VERSION ""

NS_ :

BS_:

BU_: EVCC C_ECU C_ECU_GW

BO_ 803 EYE323: 8 C_ECU_GW
 SG_ EYE323_7_0_ISA_OFFSET_CURR : 56|5@1+ (1,-10) [-10|10] "" Vector__XXX
 SG_ EYE323_7_5_SLIF_FUNC_INFO : 61|1@1+ (1,0) [0|1] "" Vector__XXX
 SG_ EYE323_7_6_ISA_FUNC_INFO : 62|1@1+ (1,0) [0|1] "" Vector__XXX
 SG_ EYE323_7_7_ISA_CUSTOMIZE_CURR : 63|1@1+ (1,0) [0|1] "" Vector__XXX
 SG_ EYE323_6_0_LDW_OFFSW_INFO : 48|1@1+ (1,0) [0|1] "" Vector__XXX
 SG_ EYE323_6_1_LDW_ON_OFF_SET : 49|1@1+ (1,0) [0|1] "" Vector__XXX
 SG_ EYE323_6_2_CSTM_DDAW_WARN_SET : 50|1@1+ (1,0) [0|1] "" Vector__XXX
 SG_ EYE323_6_3_IACC_FUNC_INFO : 51|1@1+ (1,0) [0|1] "" Vector__XXX
 SG_ EYE323_6_5_CSTM_LDW_TIMING_SET : 53|1@1+ (1,0) [0|1] "" Vector__XXX
 SG_ EYE323_6_6_CSTM_LDW_TIMING : 54|1@1+ (1,0) [0|1] "" Vector__XXX
 SG_ EYE323_6_7_SLOWDOWNL_FUNC_INFO : 55|1@1+ (1,0) [0|1] "" Vector__XXX
 SG_ EYE323_5_0_CNG_GRN_CONT_CURR : 40|1@1+ (1,0) [0|1] "" Vector__XXX
 SG_ EYE323_5_1_TRAFFIC_FUNC_INFO : 41|1@1+ (1,0) [0|1] "" Vector__XXX
 SG_ EYE323_5_2_FCW_OFFSW_INFO : 42|1@1+ (1,0) [0|1] "" Vector__XXX
 SG_ EYE323_5_3_FCW_ON_OFF_SET : 43|1@1+ (1,0) [0|1] "" Vector__XXX
 SG_ EYE323_5_4_WARNING_SEL_CURR : 44|1@1+ (1,0) [0|1] "" Vector__XXX
 SG_ EYE323_5_5_HAPT_FUNC_INFO : 45|1@1+ (1,0) [0|1] "" Vector__XXX
 SG_ EYE323_5_6_TOLLGATE_CONT_CURR : 46|1@1+ (1,0) [0|1] "" Vector__XXX
 SG_ EYE323_5_7_CURVE_CONT_CURR : 47|1@1+ (1,0) [0|1] "" Vector__XXX
 SG_ EYE323_4_0_FCTB_ICON_L : 32|2@1+ (1,0) [0|3] "" Vector__XXX
 SG_ EYE323_4_2_FCTB_ICON_R : 34|2@1+ (1,0) [0|3] "" Vector__XXX
 SG_ EYE323_4_4_FCW_CONT_CURR : 36|2@1+ (1,0) [0|3] "" Vector__XXX
 SG_ EYE323_4_6_FCW_DISPLAY_SEL : 38|2@1+ (1,0) [0|3] "" Vector__XXX
 SG_ EYE323_3_0_AES_FUNC_INFO : 24|1@1+ (1,0) [0|1] "" Vector__XXX
 SG_ EYE323_3_1_CSTM_TSR_NO_ENTRY_SET : 25|1@1+ (1,0) [0|1] "" Vector__XXX
 SG_ EYE323_3_2_CSTM_TSR_STOP_SET : 26|1@1+ (1,0) [0|1] "" Vector__XXX
 SG_ EYE323_3_3_CSTM_TSR_GIVE_WAY_SET : 27|1@1+ (1,0) [0|1] "" Vector__XXX
 SG_ EYE323_3_4_WILDERNESS : 28|1@1+ (1,0) [0|1] "" Vector__XXX
 SG_ EYE323_3_5_AES_OFF : 29|1@1+ (1,0) [0|1] "" Vector__XXX
 SG_ EYE323_3_6_FCTB_IND : 30|2@1+ (1,0) [0|3] "" Vector__XXX
 SG_ EYE323_2_0_CSTM_LDW_ALK_B : 16|2@1+ (1,0) [0|3] "" Vector__XXX
 SG_ EYE323_2_2_CSTM_P_CR : 18|1@1+ (1,0) [0|1] "" Vector__XXX
 SG_ EYE323_2_3_SLOWDOWN_FUNC_INFO2 : 19|1@1+ (1,0) [0|1] "" Vector__XXX
 SG_ EYE323_2_4_CID_CODE_WARN : 20|4@1+ (1,0) [0|15] "" Vector__XXX
 SG_ EYE323_1_0_MSG_COUNTER : 8|4@1+ (1,0) [0|15] "" Vector__XXX
 SG_ EYE323_1_4_DISP_FOLLOW_FORWARD : 12|1@1+ (1,0) [0|1] "" Vector__XXX
 SG_ EYE323_1_5_KEEP_LINE_SENTER_ACT : 13|1@1+ (1,0) [0|1] "" Vector__XXX
 SG_ EYE323_1_6_DDAW_FAIL_OFF : 14|2@1+ (1,0) [0|3] "" Vector__XXX
 SG_ EYE323_0_0_CHECK_SUM : 0|8@1+ (1,0) [0|255] "" Vector__XXX

BO_ 2564481222 EVCC18DAE0C6: 8 EVCC
 SG_ EVCC18DAE0C6_DIAG_DATA : 7|64@0+ (1,0) [0|1.844674407371E+19] ""  C_ECU_GW

BO_ 2564474592 DNT18DAC6E0: 8 C_ECU_GW
 SG_ DNT18DAC6E0_DIAG_DATA : 7|64@0+ (1,0) [0|1.844674407371E+19] ""  EVCC

BO_ 2564481219 EVCC18DAE0C3: 8 EVCC
 SG_ EVCC18DAE0C3_DIAG_DATA : 7|64@0+ (1,0) [0|1.844674407371E+19] ""  C_ECU_GW

BO_ 2564473824 DNT18DAC3E0: 8 C_ECU_GW
 SG_ DNT18DAC3E0_DIAG_DATA : 7|64@0+ (1,0) [0|1.844674407371E+19] ""  EVCC

BO_ 2564481478 EVCC18DAE1C6: 64 EVCC
 SG_ EVCC18DAE1C6_DIAG_DATA_EXT7 : 455|64@0+ (1,0) [0|1.844674407371E+19] ""  C_ECU
 SG_ EVCC18DAE1C6_DIAG_DATA_EXT6 : 391|64@0+ (1,0) [0|1.844674407371E+19] ""  C_ECU
 SG_ EVCC18DAE1C6_DIAG_DATA_EXT5 : 327|64@0+ (1,0) [0|1.844674407371E+19] ""  C_ECU
 SG_ EVCC18DAE1C6_DIAG_DATA_EXT4 : 263|64@0+ (1,0) [0|1.844674407371E+19] ""  C_ECU
 SG_ EVCC18DAE1C6_DIAG_DATA_EXT3 : 199|64@0+ (1,0) [0|1.844674407371E+19] ""  C_ECU
 SG_ EVCC18DAE1C6_DIAG_DATA_EXT2 : 135|64@0+ (1,0) [0|1.844674407371E+19] ""  C_ECU
 SG_ EVCC18DAE1C6_DIAG_DATA_EXT1 : 71|64@0+ (1,0) [0|1.844674407371E+19] ""  C_ECU
 SG_ EVCC18DAE1C6_DIAG_DATA : 7|64@0+ (1,0) [0|1.844674407371E+19] ""  C_ECU

BO_ 2564474593 CECU18DAC6E1: 64 C_ECU
 SG_ CECU18DAC6E1_DIAG_DATA_EXT7 : 455|64@0+ (1,0) [0|1.844674407371E+19] ""  EVCC
 SG_ CECU18DAC6E1_DIAG_DATA_EXT6 : 391|64@0+ (1,0) [0|1.844674407371E+19] ""  EVCC
 SG_ CECU18DAC6E1_DIAG_DATA_EXT5 : 327|64@0+ (1,0) [0|1.844674407371E+19] ""  EVCC
 SG_ CECU18DAC6E1_DIAG_DATA_EXT4 : 263|64@0+ (1,0) [0|1.844674407371E+19] ""  EVCC
 SG_ CECU18DAC6E1_DIAG_DATA_EXT3 : 199|64@0+ (1,0) [0|1.844674407371E+19] ""  EVCC
 SG_ CECU18DAC6E1_DIAG_DATA_EXT2 : 135|64@0+ (1,0) [0|1.844674407371E+19] ""  EVCC
 SG_ CECU18DAC6E1_DIAG_DATA_EXT1 : 71|64@0+ (1,0) [0|1.844674407371E+19] ""  EVCC
 SG_ CECU18DAC6E1_DIAG_DATA : 7|64@0+ (1,0) [0|1.844674407371E+19] ""  EVCC

BO_ 2564481475 EVCC18DAE1C3: 64 EVCC
 SG_ EVCC18DAE1C3_DIAG_DATA_EXT7 : 455|64@0+ (1,0) [0|1.844674407371E+19] ""  C_ECU
 SG_ EVCC18DAE1C3_DIAG_DATA_EXT6 : 391|64@0+ (1,0) [0|1.844674407371E+19] ""  C_ECU
 SG_ EVCC18DAE1C3_DIAG_DATA_EXT5 : 327|64@0+ (1,0) [0|1.844674407371E+19] ""  C_ECU
 SG_ EVCC18DAE1C3_DIAG_DATA_EXT4 : 263|64@0+ (1,0) [0|1.844674407371E+19] ""  C_ECU
 SG_ EVCC18DAE1C3_DIAG_DATA_EXT3 : 199|64@0+ (1,0) [0|1.844674407371E+19] ""  C_ECU
 SG_ EVCC18DAE1C3_DIAG_DATA_EXT2 : 135|64@0+ (1,0) [0|1.844674407371E+19] ""  C_ECU
 SG_ EVCC18DAE1C3_DIAG_DATA_EXT1 : 71|64@0+ (1,0) [0|1.844674407371E+19] ""  C_ECU
 SG_ EVCC18DAE1C3_DIAG_DATA : 7|64@0+ (1,0) [0|1.844674407371E+19] ""  C_ECU

BO_ 2564473825 CECU18DAC3E1: 64 C_ECU
 SG_ CECU18DAC3E1_DIAG_DATA_EXT7 : 455|64@0+ (1,0) [0|1.844674407371E+19] ""  EVCC
 SG_ CECU18DAC3E1_DIAG_DATA_EXT6 : 391|64@0+ (1,0) [0|1.844674407371E+19] ""  EVCC
 SG_ CECU18DAC3E1_DIAG_DATA_EXT5 : 327|64@0+ (1,0) [0|1.844674407371E+19] ""  EVCC
 SG_ CECU18DAC3E1_DIAG_DATA_EXT4 : 263|64@0+ (1,0) [0|1.844674407371E+19] ""  EVCC
 SG_ CECU18DAC3E1_DIAG_DATA_EXT3 : 199|64@0+ (1,0) [0|1.844674407371E+19] ""  EVCC
 SG_ CECU18DAC3E1_DIAG_DATA_EXT2 : 135|64@0+ (1,0) [0|1.844674407371E+19] ""  EVCC
 SG_ CECU18DAC3E1_DIAG_DATA_EXT1 : 71|64@0+ (1,0) [0|1.844674407371E+19] ""  EVCC
 SG_ CECU18DAC3E1_DIAG_DATA : 7|64@0+ (1,0) [0|1.844674407371E+19] ""  EVCC

BO_ 1100 EVCC44C: 8 EVCC
 SG_ EVCC44C_2_0_E2E_COUNTER : 16|8@1+ (1,0) [0|255] ""  C_ECU_GW
 SG_ EVCC44C_0_0_E2E_CRC : 0|16@1+ (1,0) [0|65535] ""  C_ECU_GW

BO_ 1099 EVCC44B: 32 EVCC
 SG_ EVCC44B_27_0_EVSE_ID_7_EVCC : 216|32@1+ (1,0) [0|31] ""  C_ECU_GW
 SG_ EVCC44B_23_0_EVSE_ID_6_EVCC : 184|32@1+ (1,0) [0|31] ""  C_ECU_GW
 SG_ EVCC44B_19_0_EVSE_ID_5_EVCC : 152|32@1+ (1,0) [0|31] ""  C_ECU_GW
 SG_ EVCC44B_15_0_EVSE_ID_4_EVCC : 120|32@1+ (1,0) [0|31] ""  C_ECU_GW
 SG_ EVCC44B_11_0_EVSE_ID_3_EVCC : 88|32@1+ (1,0) [0|31] ""  C_ECU_GW
 SG_ EVCC44B_7_0_EVSE_ID_2_EVCC : 56|32@1+ (1,0) [0|31] ""  C_ECU_GW
 SG_ EVCC44B_3_0_EVSE_ID_1_EVCC : 24|32@1+ (1,0) [0|31] ""  C_ECU_GW
 SG_ EVCC44B_2_0_E2E_COUNTER : 16|8@1+ (1,0) [0|255] ""  C_ECU_GW
 SG_ EVCC44B_0_0_E2E_CRC : 0|16@1+ (1,0) [0|65535] ""  C_ECU_GW

BO_ 1098 EVCC44A: 32 EVCC
 SG_ EVCC44A_3_0_PNC_CC_SAVE_RES_RSLT : 24|8@1+ (1,0) [0|5] ""  C_ECU,C_ECU_GW
 SG_ EVCC44A_2_0_E2E_COUNTER : 16|8@1+ (1,0) [0|255] ""  C_ECU,C_ECU_GW
 SG_ EVCC44A_0_0_E2E_CRC : 0|16@1+ (1,0) [0|65535] ""  C_ECU,C_ECU_GW

BO_ 1097 EVCC449: 8 EVCC
 SG_ EVCC449_2_0_E2E_COUNTER : 16|8@1+ (1,0) [0|255] ""  C_ECU_GW
 SG_ EVCC449_0_0_E2E_CRC : 0|16@1+ (1,0) [0|65535] ""  C_ECU_GW

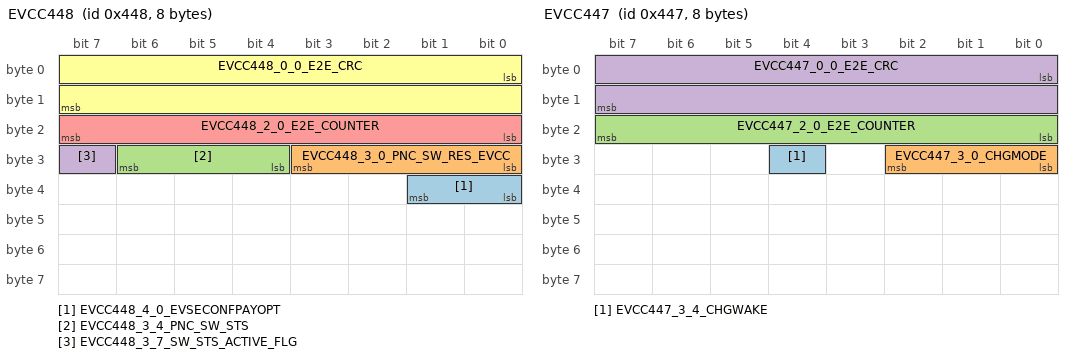
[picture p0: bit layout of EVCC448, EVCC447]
BO_ 1096 EVCC448: 8 EVCC
 SG_ EVCC448_4_0_EVSECONFPAYOPT : 32|2@1+ (1,0) [0|2] ""  C_ECU_GW
 SG_ EVCC448_3_0_PNC_SW_RES_EVCC : 24|4@1+ (1,0) [0|8] ""  C_ECU_GW
 SG_ EVCC448_3_4_PNC_SW_STS : 28|3@1+ (1,0) [0|7] ""  C_ECU_GW
 SG_ EVCC448_3_7_SW_STS_ACTIVE_FLG : 31|1@1+ (1,0) [0|1] ""  C_ECU_GW
 SG_ EVCC448_2_0_E2E_COUNTER : 16|8@1+ (1,0) [0|255] ""  C_ECU_GW
 SG_ EVCC448_0_0_E2E_CRC : 0|16@1+ (1,0) [0|65535] ""  C_ECU_GW

BO_ 1095 EVCC447: 8 EVCC
 SG_ EVCC447_3_4_CHGWAKE : 28|1@1+ (1,0) [0|1] ""  C_ECU,C_ECU_GW
 SG_ EVCC447_3_0_CHGMODE : 24|3@1+ (1,0) [0|7] ""  C_ECU,C_ECU_GW
 SG_ EVCC447_2_0_E2E_COUNTER : 16|8@1+ (1,0) [0|255] ""  C_ECU,C_ECU_GW
 SG_ EVCC447_0_0_E2E_CRC : 0|16@1+ (1,0) [0|65535] ""  C_ECU,C_ECU_GW

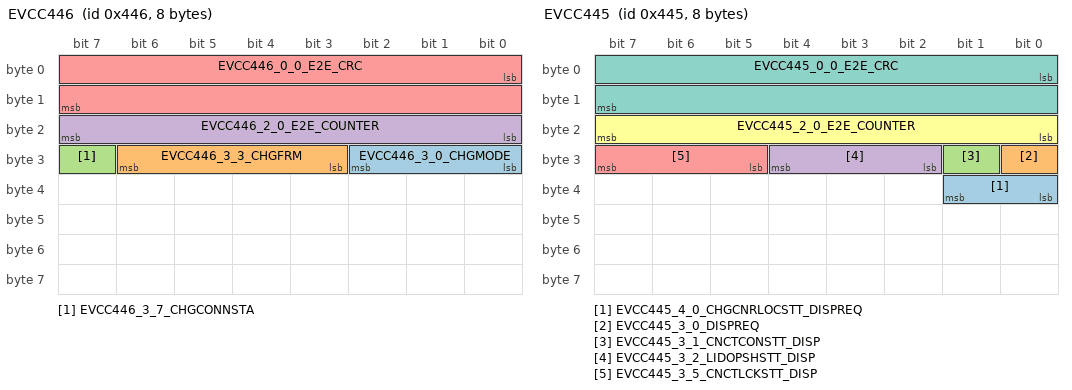
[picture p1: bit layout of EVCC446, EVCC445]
BO_ 1094 EVCC446: 8 EVCC
 SG_ EVCC446_3_0_CHGMODE : 24|3@1+ (1,0) [0|7] ""  C_ECU_GW
 SG_ EVCC446_3_3_CHGFRM : 27|4@1+ (1,0) [0|15] ""  C_ECU_GW
 SG_ EVCC446_3_7_CHGCONNSTA : 31|1@1+ (1,0) [0|1] ""  C_ECU_GW
 SG_ EVCC446_2_0_E2E_COUNTER : 16|8@1+ (1,0) [0|255] ""  C_ECU_GW
 SG_ EVCC446_0_0_E2E_CRC : 0|16@1+ (1,0) [0|65535] ""  C_ECU_GW

BO_ 1093 EVCC445: 8 EVCC
 SG_ EVCC445_4_0_CHGCNRLOCSTT_DISPREQ : 32|2@1+ (1,0) [0|2] ""  C_ECU_GW
 SG_ EVCC445_3_0_DISPREQ : 24|1@1+ (1,0) [0|1] ""  C_ECU_GW
 SG_ EVCC445_3_1_CNCTCONSTT_DISP : 25|1@1+ (1,0) [0|1] ""  C_ECU_GW
 SG_ EVCC445_3_2_LIDOPSHSTT_DISP : 26|3@1+ (1,0) [0|2] ""  C_ECU_GW
 SG_ EVCC445_3_5_CNCTLCKSTT_DISP : 29|3@1+ (1,0) [0|2] ""  C_ECU_GW
 SG_ EVCC445_2_0_E2E_COUNTER : 16|8@1+ (1,0) [0|255] ""  C_ECU_GW
 SG_ EVCC445_0_0_E2E_CRC : 0|16@1+ (1,0) [0|65535] ""  C_ECU_GW

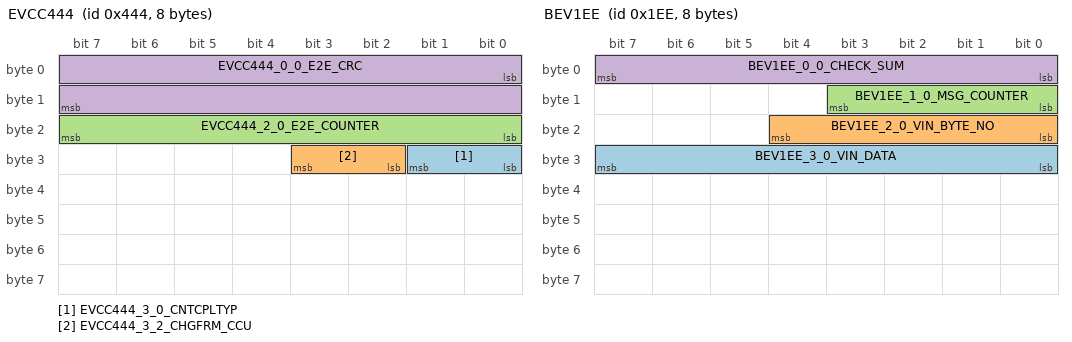
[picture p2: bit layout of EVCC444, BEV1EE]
BO_ 1092 EVCC444: 8 EVCC
 SG_ EVCC444_3_0_CNTCPLTYP : 24|2@1+ (1,0) [0|1] ""  C_ECU_GW
 SG_ EVCC444_3_2_CHGFRM_CCU : 26|2@1+ (1,0) [0|2] ""  C_ECU_GW
 SG_ EVCC444_2_0_E2E_COUNTER : 16|8@1+ (1,0) [0|255] ""  C_ECU_GW
 SG_ EVCC444_0_0_E2E_CRC : 0|16@1+ (1,0) [0|65535] ""  C_ECU_GW

BO_ 1305 EVCC519: 8 EVCC
 SG_ EVCC519_1_4_ACTIVEWAKEUPBIT : 12|1@1+ (1,0) [0|1] ""  C_ECU
 SG_ EVCC519_0_0_SOURCENODEID : 0|8@1+ (1,0) [0|255] ""  C_ECU

BO_ 494 BEV1EE: 8 C_ECU_GW
 SG_ BEV1EE_3_0_VIN_DATA : 24|8@1+ (1,0) [0|255] "" Vector__XXX
 SG_ BEV1EE_2_0_VIN_BYTE_NO : 16|5@1+ (1,0) [0|17] "" Vector__XXX
 SG_ BEV1EE_1_0_MSG_COUNTER : 8|4@1+ (1,0) [0|15] "" Vector__XXX
 SG_ BEV1EE_0_0_CHECK_SUM : 0|8@1+ (1,0) [0|255] "" Vector__XXX

BO_ 2564550625 CECU18DBEFE1: 8 C_ECU
 SG_ CECU18DBEFE1_DIAG_DATA : 7|64@0+ (1,0) [0|1.844674407371E+19] ""  EVCC

BO_ 2564550624 DNT18DBEFE0: 8 C_ECU_GW
 SG_ DNT18DBEFE0_DIAG_DATA : 7|64@0+ (1,0) [0|1.844674407371E+19] "" Vector__XXX

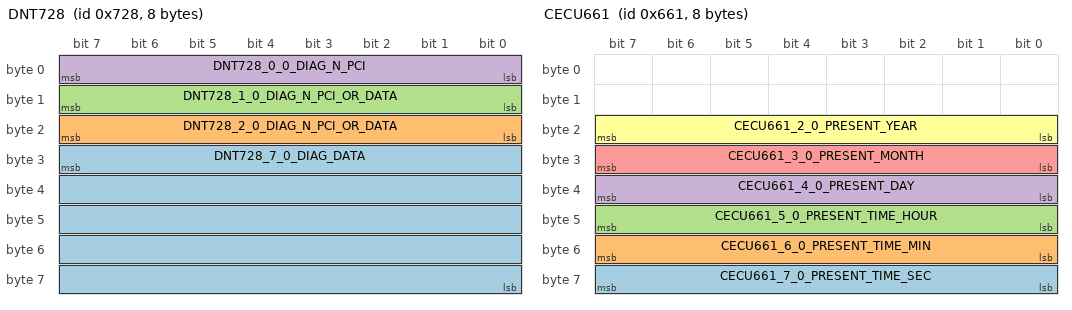
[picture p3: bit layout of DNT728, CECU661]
BO_ 1832 DNT728: 8 C_ECU_GW
 SG_ DNT728_7_0_DIAG_DATA : 31|40@0+ (1,0) [0|1099511627775] "" Vector__XXX
 SG_ DNT728_2_0_DIAG_N_PCI_OR_DATA : 23|8@0+ (1,0) [0|255] "" Vector__XXX
 SG_ DNT728_1_0_DIAG_N_PCI_OR_DATA : 15|8@0+ (1,0) [0|255] "" Vector__XXX
 SG_ DNT728_0_0_DIAG_N_PCI : 7|8@0+ (1,0) [0|255] "" Vector__XXX

BO_ 1280 CGW500: 8 C_ECU
 SG_ CGW500_1_4_ActiveWakeUpBit : 12|1@1+ (1,0) [0|1] ""  EVCC
 SG_ CGW500_0_0_SourceNodeID : 0|8@1+ (1,0) [0|255] ""  EVCC

BO_ 1633 CECU661: 8 C_ECU
 SG_ CECU661_7_0_PRESENT_TIME_SEC : 63|8@0+ (1,0) [0|89] "s"  EVCC
 SG_ CECU661_6_0_PRESENT_TIME_MIN : 55|8@0+ (1,0) [0|89] "m"  EVCC
 SG_ CECU661_5_0_PRESENT_TIME_HOUR : 47|8@0+ (1,0) [0|35] "h"  EVCC
 SG_ CECU661_4_0_PRESENT_DAY : 39|8@0+ (1,0) [1|49] "Day"  EVCC
 SG_ CECU661_3_0_PRESENT_MONTH : 31|8@0+ (1,0) [1|18] "Month"  EVCC
 SG_ CECU661_2_0_PRESENT_YEAR : 23|8@0+ (1,0) [0|153] "Year"  EVCC

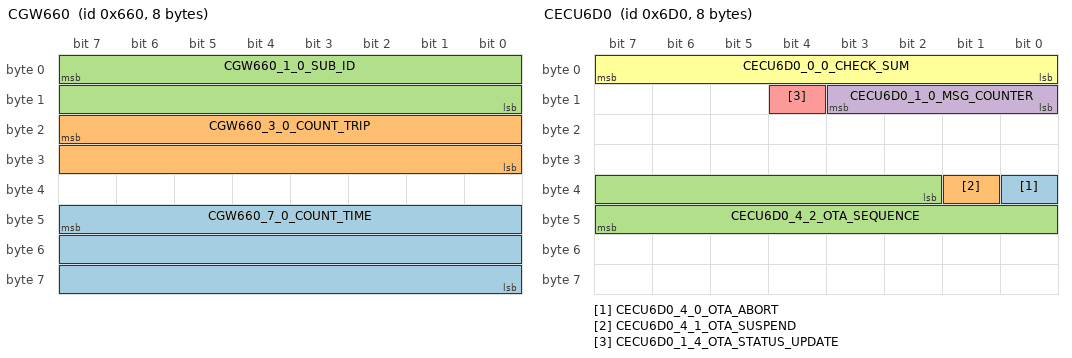
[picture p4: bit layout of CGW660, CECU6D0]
BO_ 1632 CGW660: 8 C_ECU
 SG_ CGW660_7_0_COUNT_TIME : 47|24@0+ (100,0) [0|1677721400] "ms" Vector__XXX
 SG_ CGW660_3_0_COUNT_TRIP : 23|16@0+ (1,0) [0|65534] "trip" Vector__XXX
 SG_ CGW660_1_0_SUB_ID : 7|16@0+ (1,0) [0|65535] "" Vector__XXX

BO_ 1744 CECU6D0: 8 C_ECU
 SG_ CECU6D0_4_0_OTA_ABORT : 32|1@1+ (1,0) [0|1] "" Vector__XXX
 SG_ CECU6D0_4_1_OTA_SUSPEND : 33|1@1+ (1,0) [0|1] "" Vector__XXX
 SG_ CECU6D0_4_2_OTA_SEQUENCE : 34|14@1+ (1,0) [0|33170] "" Vector__XXX
 SG_ CECU6D0_1_0_MSG_COUNTER : 8|4@1+ (1,0) [0|15] "" Vector__XXX
 SG_ CECU6D0_1_4_OTA_STATUS_UPDATE : 12|1@1+ (1,0) [0|0] "" Vector__XXX
 SG_ CECU6D0_0_0_CHECK_SUM : 0|8@1+ (1,0) [0|255] "" Vector__XXX

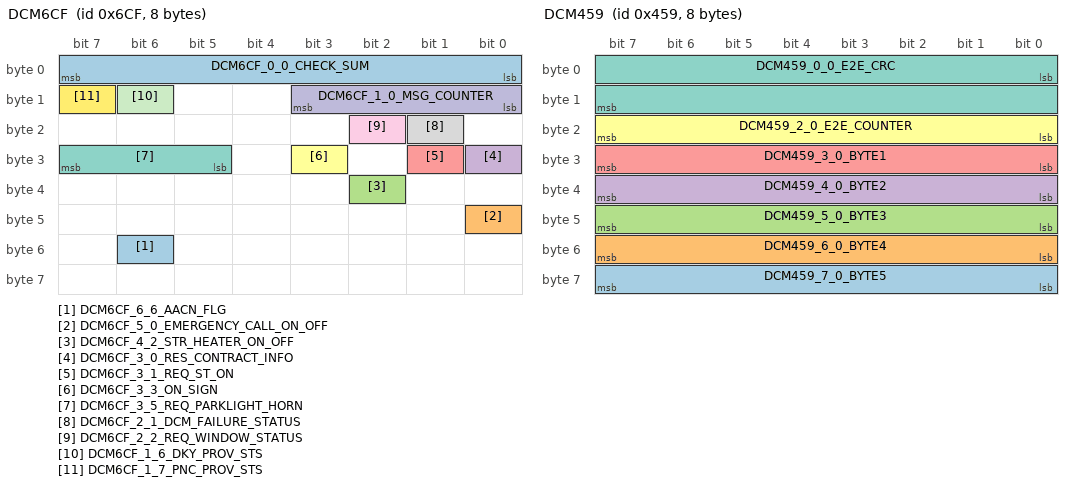
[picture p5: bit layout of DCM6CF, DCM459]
BO_ 1743 DCM6CF: 8 C_ECU_GW
 SG_ DCM6CF_6_6_AACN_FLG : 54|1@1+ (1,0) [0|1] "" Vector__XXX
 SG_ DCM6CF_5_0_EMERGENCY_CALL_ON_OFF : 40|1@1+ (1,0) [0|1] "" Vector__XXX
 SG_ DCM6CF_4_2_STR_HEATER_ON_OFF : 34|1@1+ (1,0) [0|1] "" Vector__XXX
 SG_ DCM6CF_3_0_RES_CONTRACT_INFO : 24|1@1+ (1,0) [0|1] "" Vector__XXX
 SG_ DCM6CF_3_1_REQ_ST_ON : 25|1@1+ (1,0) [0|1] "" Vector__XXX
 SG_ DCM6CF_3_3_ON_SIGN : 27|1@1+ (1,0) [0|1] "" Vector__XXX
 SG_ DCM6CF_3_5_REQ_PARKLIGHT_HORN : 29|3@1+ (1,0) [0|7] "" Vector__XXX
 SG_ DCM6CF_2_1_DCM_FAILURE_STATUS : 17|1@1+ (1,0) [0|1] "" Vector__XXX
 SG_ DCM6CF_2_2_REQ_WINDOW_STATUS : 18|1@1+ (1,0) [0|1] "" Vector__XXX
 SG_ DCM6CF_1_0_MSG_COUNTER : 8|4@1+ (1,0) [0|15] "" Vector__XXX
 SG_ DCM6CF_1_6_DKY_PROV_STS : 14|1@1+ (1,0) [0|1] "" Vector__XXX
 SG_ DCM6CF_1_7_PNC_PROV_STS : 15|1@1+ (1,0) [0|1] ""  EVCC
 SG_ DCM6CF_0_0_CHECK_SUM : 0|8@1+ (1,0) [0|255] "" Vector__XXX

BO_ 1113 DCM459: 8 C_ECU_GW
 SG_ DCM459_7_0_BYTE5 : 56|8@1+ (1,0) [0|255] ""  EVCC
 SG_ DCM459_6_0_BYTE4 : 48|8@1+ (1,0) [0|255] ""  EVCC
 SG_ DCM459_5_0_BYTE3 : 40|8@1+ (1,0) [0|255] ""  EVCC
 SG_ DCM459_4_0_BYTE2 : 32|8@1+ (1,0) [0|255] ""  EVCC
 SG_ DCM459_3_0_BYTE1 : 24|8@1+ (1,0) [0|255] ""  EVCC
 SG_ DCM459_2_0_E2E_COUNTER : 16|8@1+ (1,0) [0|255] ""  EVCC
 SG_ DCM459_0_0_E2E_CRC : 0|16@1+ (1,0) [0|65535] ""  EVCC

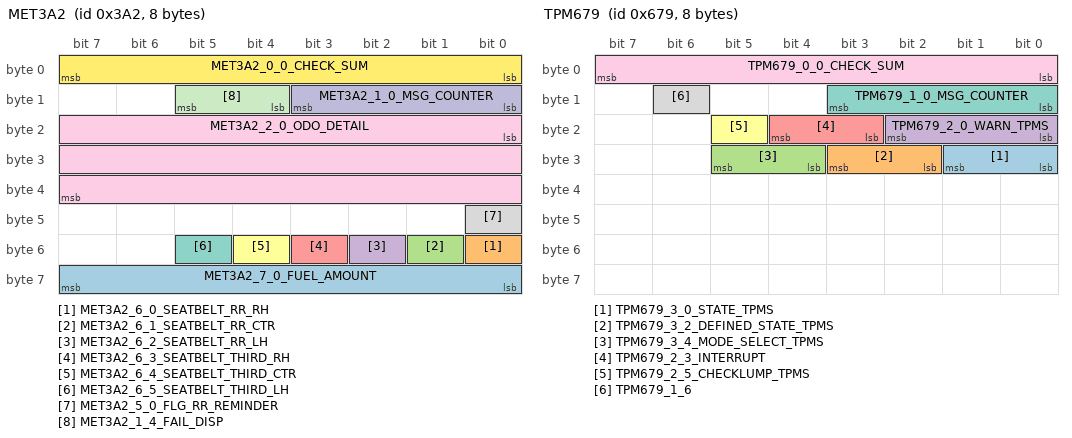
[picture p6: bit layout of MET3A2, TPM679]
BO_ 930 MET3A2: 8 C_ECU_GW
 SG_ MET3A2_7_0_FUEL_AMOUNT : 56|8@1+ (1,0) [0|100] "%" Vector__XXX
 SG_ MET3A2_6_0_SEATBELT_RR_RH : 48|1@1+ (1,0) [0|1] "" Vector__XXX
 SG_ MET3A2_6_1_SEATBELT_RR_CTR : 49|1@1+ (1,0) [0|1] "" Vector__XXX
 SG_ MET3A2_6_2_SEATBELT_RR_LH : 50|1@1+ (1,0) [0|1] "" Vector__XXX
 SG_ MET3A2_6_3_SEATBELT_THIRD_RH : 51|1@1+ (1,0) [0|1] "" Vector__XXX
 SG_ MET3A2_6_4_SEATBELT_THIRD_CTR : 52|1@1+ (1,0) [0|1] "" Vector__XXX
 SG_ MET3A2_6_5_SEATBELT_THIRD_LH : 53|1@1+ (1,0) [0|1] "" Vector__XXX
 SG_ MET3A2_5_0_FLG_RR_REMINDER : 40|1@1+ (1,0) [0|1] "" Vector__XXX
 SG_ MET3A2_2_0_ODO_DETAIL : 16|24@1+ (0.1,0) [0|1609103.5] "km" Vector__XXX
 SG_ MET3A2_1_0_MSG_COUNTER : 8|4@1+ (1,0) [0|15] "" Vector__XXX
 SG_ MET3A2_1_4_FAIL_DISP : 12|2@1+ (1,0) [0|3] "" Vector__XXX
 SG_ MET3A2_0_0_CHECK_SUM : 0|8@1+ (1,0) [0|255] "" Vector__XXX

BO_ 912 MET390: 8 C_ECU_GW
 SG_ MET390_7_0_VDC_ON_OFF : 56|2@1+ (1,0) [0|3] "" Vector__XXX
 SG_ MET390_7_2_RR_DOOR_RECORD_L : 58|1@1+ (1,0) [0|1] "" Vector__XXX
 SG_ MET390_7_3_RR_DOOR_RECORD_R : 59|1@1+ (1,0) [0|1] "" Vector__XXX
 SG_ MET390_7_4_REQ_CHG_CSTM_PSM : 60|1@1+ (1,0) [0|1] "" Vector__XXX
 SG_ MET390_7_5_REQ_RESET_CSTM_PSM : 61|1@1+ (1,0) [0|1] "" Vector__XXX
 SG_ MET390_7_6_CSTM_MIR_AFOLD_CONT : 62|1@1+ (1,0) [0|1] "" Vector__XXX
 SG_ MET390_7_7_CSTM_MIR_RTILT_CONT : 63|1@1+ (1,0) [0|1] "" Vector__XXX
 SG_ MET390_6_0_SEATBELT_DRVR : 48|1@1+ (1,0) [0|1] "" Vector__XXX
 SG_ MET390_6_1_SEATBELT_PASS : 49|1@1+ (1,0) [0|1] "" Vector__XXX
 SG_ MET390_6_2_TURN_SIG_LEFT : 50|1@1+ (1,0) [0|1] "" Vector__XXX
 SG_ MET390_6_3_TURN_SIG_RIGHT : 51|1@1+ (1,0) [0|1] "" Vector__XXX
 SG_ MET390_6_4_BRIGHT_SW : 52|1@1+ (1,0) [0|1] "" Vector__XXX
 SG_ MET390_6_5_FAIL_UART_WA_BOX : 53|1@1+ (1,0) [0|1] "" Vector__XXX
 SG_ MET390_6_6_ISS_OFF_SW : 54|1@1+ (1,0) [0|1] "" Vector__XXX
 SG_ MET390_6_7_FLG_DMS : 55|1@1+ (1,0) [0|1] "" Vector__XXX
 SG_ MET390_5_0_ILL_BRIGHTNESS : 40|8@1+ (0.4,0) [0|100] "%" Vector__XXX
 SG_ MET390_4_0_OUTTEMP_FOR_IND : 32|8@1+ (0.5,-40) [-40|80] "℃" Vector__XXX
 SG_ MET390_3_0_UNIT_SPEED_TRIP : 24|1@1+ (1,0) [0|1] "" Vector__XXX
 SG_ MET390_3_1_FLG_EYESIGHT : 25|1@1+ (1,0) [0|1] "" Vector__XXX
 SG_ MET390_3_2_FLG_ISS : 26|1@1+ (1,0) [0|1] "" Vector__XXX
 SG_ MET390_3_3_FLG_HEV : 27|1@1+ (1,0) [0|1] "" Vector__XXX
 SG_ MET390_3_4_FLG_IMB : 28|1@1+ (1,0) [0|1] "" Vector__XXX
 SG_ MET390_3_5_TIRE_SIZE : 29|1@1+ (1,0) [0|1] "" Vector__XXX
 SG_ MET390_3_6_FLG_XMODE : 30|2@1+ (1,0) [0|3] "" Vector__XXX
 SG_ MET390_2_0_VEHICLE_SERIES : 16|3@1+ (1,0) [0|7] "" Vector__XXX
 SG_ MET390_2_3_DESTINATION : 19|4@1+ (1,0) [0|12] "" Vector__XXX
 SG_ MET390_2_7_PASS_DOOR_RECORD : 23|1@1+ (1,0) [0|1] "" Vector__XXX
 SG_ MET390_1_0_MSG_COUNTER : 8|4@1+ (1,0) [0|15] "" Vector__XXX
 SG_ MET390_1_4_WAKE_UP_FRAME : 12|1@1+ (1,0) [0|1] "" Vector__XXX
 SG_ MET390_1_5_REQ_COMM_CONT : 13|1@1+ (1,0) [0|1] "" Vector__XXX
 SG_ MET390_1_6_DMS_ID_SET : 14|1@1+ (1,0) [0|1] "" Vector__XXX
 SG_ MET390_1_7_FAIL_EEPROM : 15|1@1+ (1,0) [0|1] "" Vector__XXX
 SG_ MET390_0_0_CHECK_SUM : 0|8@1+ (1,0) [0|255] "" Vector__XXX

BO_ 1657 TPM679: 8 C_ECU_GW
 SG_ TPM679_3_0_STATE_TPMS : 24|2@1+ (1,0) [0|3] "" Vector__XXX
 SG_ TPM679_3_2_DEFINED_STATE_TPMS : 26|2@1+ (1,0) [0|3] "" Vector__XXX
 SG_ TPM679_3_4_MODE_SELECT_TPMS : 28|2@1+ (1,0) [0|3] "" Vector__XXX
 SG_ TPM679_2_0_WARN_TPMS : 16|3@1+ (1,0) [0|7] "" Vector__XXX
 SG_ TPM679_2_3_INTERRUPT : 19|2@1+ (1,0) [0|2] "" Vector__XXX
 SG_ TPM679_2_5_CHECKLUMP_TPMS : 21|1@1+ (1,0) [0|1] "" Vector__XXX
 SG_ TPM679_1_0_MSG_COUNTER : 8|4@1+ (1,0) [0|15] "" Vector__XXX
 SG_ TPM679_1_6 : 14|1@1+ (1,0) [0|1] "" Vector__XXX
 SG_ TPM679_0_0_CHECK_SUM : 0|8@1+ (1,0) [0|255] "" Vector__XXX

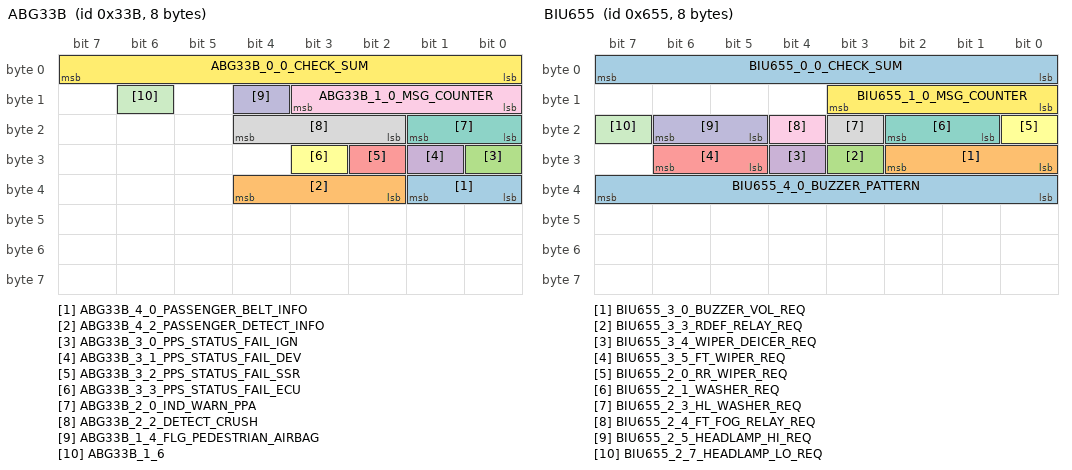
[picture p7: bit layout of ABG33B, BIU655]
BO_ 827 ABG33B: 8 C_ECU_GW
 SG_ ABG33B_4_0_PASSENGER_BELT_INFO : 32|2@1+ (1,0) [0|3] "" Vector__XXX
 SG_ ABG33B_4_2_PASSENGER_DETECT_INFO : 34|3@1+ (1,0) [0|7] "" Vector__XXX
 SG_ ABG33B_3_0_PPS_STATUS_FAIL_IGN : 24|1@1+ (1,0) [0|1] "" Vector__XXX
 SG_ ABG33B_3_1_PPS_STATUS_FAIL_DEV : 25|1@1+ (1,0) [0|1] "" Vector__XXX
 SG_ ABG33B_3_2_PPS_STATUS_FAIL_SSR : 26|1@1+ (1,0) [0|1] "" Vector__XXX
 SG_ ABG33B_3_3_PPS_STATUS_FAIL_ECU : 27|1@1+ (1,0) [0|1] "" Vector__XXX
 SG_ ABG33B_2_0_IND_WARN_PPA : 16|2@1+ (1,0) [0|3] "" Vector__XXX
 SG_ ABG33B_2_2_DETECT_CRUSH : 18|3@1+ (1,0) [0|7] "" Vector__XXX
 SG_ ABG33B_1_0_MSG_COUNTER : 8|4@1+ (1,0) [0|15] "" Vector__XXX
 SG_ ABG33B_1_4_FLG_PEDESTRIAN_AIRBAG : 12|1@1+ (1,0) [0|1] "" Vector__XXX
 SG_ ABG33B_1_6 : 14|1@1+ (1,0) [0|1] "" Vector__XXX
 SG_ ABG33B_0_0_CHECK_SUM : 0|8@1+ (1,0) [0|255] "" Vector__XXX

BO_ 1621 BIU655: 8 C_ECU_GW
 SG_ BIU655_4_0_BUZZER_PATTERN : 32|8@1+ (1,0) [0|240] "" Vector__XXX
 SG_ BIU655_3_0_BUZZER_VOL_REQ : 24|3@1+ (1,0) [0|7] "" Vector__XXX
 SG_ BIU655_3_3_RDEF_RELAY_REQ : 27|1@1+ (1,0) [0|1] "" Vector__XXX
 SG_ BIU655_3_4_WIPER_DEICER_REQ : 28|1@1+ (1,0) [0|1] "" Vector__XXX
 SG_ BIU655_3_5_FT_WIPER_REQ : 29|2@1+ (1,0) [0|3] "" Vector__XXX
 SG_ BIU655_2_0_RR_WIPER_REQ : 16|1@1+ (1,0) [0|1] "" Vector__XXX
 SG_ BIU655_2_1_WASHER_REQ : 17|2@1+ (1,0) [0|3] "" Vector__XXX
 SG_ BIU655_2_3_HL_WASHER_REQ : 19|1@1+ (1,0) [0|1] "" Vector__XXX
 SG_ BIU655_2_4_FT_FOG_RELAY_REQ : 20|1@1+ (1,0) [0|1] "" Vector__XXX
 SG_ BIU655_2_5_HEADLAMP_HI_REQ : 21|2@1+ (1,0) [0|3] "" Vector__XXX
 SG_ BIU655_2_7_HEADLAMP_LO_REQ : 23|1@1+ (1,0) [0|1] "" Vector__XXX
 SG_ BIU655_1_0_MSG_COUNTER : 8|4@1+ (1,0) [0|15] "" Vector__XXX
 SG_ BIU655_0_0_CHECK_SUM : 0|8@1+ (1,0) [0|255] "" Vector__XXX

BO_ 1618 BIU652: 8 C_ECU_GW
 SG_ BIU652_7_0_IND_SECURITY_IMB : 56|8@1+ (1,0) [0|240] "" Vector__XXX
 SG_ BIU652_6_0_OCCUPATION_3RDRH : 48|1@1+ (1,0) [0|1] "" Vector__XXX
 SG_ BIU652_6_1_OCCUPATION_3RDCTR : 49|1@1+ (1,0) [0|1] "" Vector__XXX
 SG_ BIU652_6_2_OCCUPATION_3RDLH : 50|1@1+ (1,0) [0|1] "" Vector__XXX
 SG_ BIU652_6_3_OCCUPATION_RRRH : 51|1@1+ (1,0) [0|1] "" Vector__XXX
 SG_ BIU652_6_4_OCCUPATION_RRCTR : 52|1@1+ (1,0) [0|1] "" Vector__XXX
 SG_ BIU652_6_5_OCCUPATION_RRLH : 53|1@1+ (1,0) [0|1] "" Vector__XXX
 SG_ BIU652_6_6_HORNHAZARD_RES_SIG : 54|1@1+ (1,0) [0|1] "" Vector__XXX
 SG_ BIU652_6_7_OCCUPATION_DRVR : 55|1@1+ (1,0) [0|1] "" Vector__XXX
 SG_ BIU652_5_0_STATUS_ROOMLAMP : 40|3@1+ (1,0) [0|7] "" Vector__XXX
 SG_ BIU652_5_3_HEADLAMP_SMALL : 43|1@1+ (1,0) [0|1] "" Vector__XXX
 SG_ BIU652_5_4_ALL_UNLOCK_STATE : 44|1@1+ (1,0) [0|1] "" Vector__XXX
 SG_ BIU652_5_5_DRVR_UNLOCK_STATE : 45|1@1+ (1,0) [0|1] "" Vector__XXX
 SG_ BIU652_5_6_ALL_LOCK_STATE : 46|1@1+ (1,0) [0|1] "" Vector__XXX
 SG_ BIU652_4_0_TRIG_LOCK_UNLOCK : 32|8@1+ (1,0) [0|255] "" Vector__XXX
 SG_ BIU652_3_0_DOOR_DRVR : 24|1@1+ (1,0) [0|1] ""  EVCC
 SG_ BIU652_3_1_DOOR_PASS : 25|1@1+ (1,0) [0|1] ""  EVCC
 SG_ BIU652_3_2_DOOR_RRRH : 26|1@1+ (1,0) [0|1] ""  EVCC
 SG_ BIU652_3_3_DOOR_RRLH : 27|1@1+ (1,0) [0|1] ""  EVCC
 SG_ BIU652_3_4_DOOR_RG : 28|1@1+ (1,0) [0|1] ""  EVCC
 SG_ BIU652_3_5_DOOR_TR : 29|1@1+ (1,0) [0|1] ""  EVCC
 SG_ BIU652_3_7_OPENSW_RG : 31|1@1+ (1,0) [0|1] "" Vector__XXX
 SG_ BIU652_2_0_LOCKSTATUS_DRVR : 16|1@1+ (1,0) [0|1] ""  EVCC
 SG_ BIU652_2_1_LOCKSTATUS_PASS : 17|1@1+ (1,0) [0|1] ""  EVCC
 SG_ BIU652_2_2_LOCKSTATUS_RRRH : 18|1@1+ (1,0) [0|1] ""  EVCC
 SG_ BIU652_2_3_LOCKSTATUS_RRLH : 19|1@1+ (1,0) [0|1] ""  EVCC
 SG_ BIU652_2_4_LOCKSTATUS_RG : 20|1@1+ (1,0) [0|1] ""  EVCC
 SG_ BIU652_2_6_UNLOCK_DOORKEYSW : 22|1@1+ (1,0) [0|1] "" Vector__XXX
 SG_ BIU652_2_7_LOCK_DOORKEYSW : 23|1@1+ (1,0) [0|1] "" Vector__XXX
 SG_ BIU652_1_0_MSG_COUNTER : 8|4@1+ (1,0) [0|15] "" Vector__XXX
 SG_ BIU652_0_0_CHECK_SUM : 0|8@1+ (1,0) [0|255] "" Vector__XXX

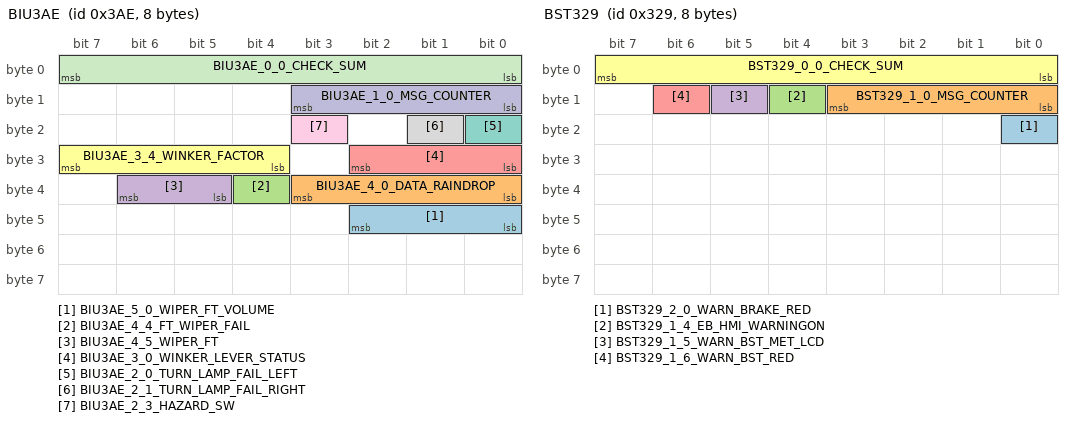
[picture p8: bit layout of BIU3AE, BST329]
BO_ 942 BIU3AE: 8 C_ECU_GW
 SG_ BIU3AE_5_0_WIPER_FT_VOLUME : 40|3@1+ (1,0) [0|5] "" Vector__XXX
 SG_ BIU3AE_4_0_DATA_RAINDROP : 32|4@1+ (1,0) [0|8] "" Vector__XXX
 SG_ BIU3AE_4_4_FT_WIPER_FAIL : 36|1@1+ (1,0) [0|1] "" Vector__XXX
 SG_ BIU3AE_4_5_WIPER_FT : 37|2@1+ (1,0) [0|3] "" Vector__XXX
 SG_ BIU3AE_3_0_WINKER_LEVER_STATUS : 24|3@1+ (1,0) [0|5] "" Vector__XXX
 SG_ BIU3AE_3_4_WINKER_FACTOR : 28|4@1+ (1,0) [0|15] "" Vector__XXX
 SG_ BIU3AE_2_0_TURN_LAMP_FAIL_LEFT : 16|1@1+ (1,0) [0|1] "" Vector__XXX
 SG_ BIU3AE_2_1_TURN_LAMP_FAIL_RIGHT : 17|1@1+ (1,0) [0|1] "" Vector__XXX
 SG_ BIU3AE_2_3_HAZARD_SW : 19|1@1+ (1,0) [0|1] "" Vector__XXX
 SG_ BIU3AE_1_0_MSG_COUNTER : 8|4@1+ (1,0) [0|15] "" Vector__XXX
 SG_ BIU3AE_0_0_CHECK_SUM : 0|8@1+ (1,0) [0|255] "" Vector__XXX

BO_ 940 BIU3AC: 8 C_ECU_GW
 SG_ BIU3AC_7_0_HEADLAMP_SMALL : 56|1@1+ (1,0) [0|1] "" Vector__XXX
 SG_ BIU3AC_7_1_HEADLAMP_LO_REQ : 57|1@1+ (1,0) [0|1] "" Vector__XXX
 SG_ BIU3AC_7_2_HEADLAMP_HI_REQ : 58|1@1+ (1,0) [0|1] "" Vector__XXX
 SG_ BIU3AC_7_3_FT_FOG_RELAY_REQ : 59|1@1+ (1,0) [0|1] "" Vector__XXX
 SG_ BIU3AC_7_4_FOGLAMP_RR : 60|1@1+ (1,0) [0|1] "" Vector__XXX
 SG_ BIU3AC_7_5_DRL : 61|1@1+ (1,0) [0|1] "" Vector__XXX
 SG_ BIU3AC_7_6_WIPER_FRONT : 62|1@1+ (1,0) [0|1] "" Vector__XXX
 SG_ BIU3AC_7_7_RDEF_RELAY_REQ : 63|1@1+ (1,0) [0|1] "" Vector__XXX
 SG_ BIU3AC_6_0_RDEFOGSW : 48|1@1+ (1,0) [0|1] "" Vector__XXX
 SG_ BIU3AC_6_1_CSTM_PRG : 49|1@1+ (1,0) [0|1] "" Vector__XXX
 SG_ BIU3AC_6_2_FAIL_SHIFTLOCKSOL : 50|1@1+ (1,0) [0|1] "" Vector__XXX
 SG_ BIU3AC_6_3_REQ_CANCEL_ISS : 51|1@1+ (1,0) [0|1] "" Vector__XXX
 SG_ BIU3AC_6_4_REVERSE_MT : 52|1@1+ (1,0) [0|1] "" Vector__XXX
 SG_ BIU3AC_6_5_HANDBRAKE : 53|1@1+ (1,0) [0|1] "" Vector__XXX
 SG_ BIU3AC_6_6_BRAKELAMPSW : 54|1@1+ (1,0) [0|1] "" Vector__XXX
 SG_ BIU3AC_6_7_TOWING_SW : 55|1@1+ (1,0) [0|1] "" Vector__XXX
 SG_ BIU3AC_5_0_LANE_OFF_SW : 40|2@1+ (1,0) [0|3] "" Vector__XXX
 SG_ BIU3AC_5_2_PCR_OFF_SW : 42|2@1+ (1,0) [0|3] "" Vector__XXX
 SG_ BIU3AC_5_4_DIMMER_CANCEL : 44|1@1+ (1,0) [0|1] "" Vector__XXX
 SG_ BIU3AC_5_5_KEYSW : 45|1@1+ (1,0) [0|1] "" Vector__XXX
 SG_ BIU3AC_5_6_IND_ND_SHIFTLOCK : 46|1@1+ (1,0) [0|1] "" Vector__XXX
 SG_ BIU3AC_4_0_DOOR_DRVR : 32|1@1+ (1,0) [0|1] "" Vector__XXX
 SG_ BIU3AC_4_1_DOOR_PASS : 33|1@1+ (1,0) [0|1] "" Vector__XXX
 SG_ BIU3AC_4_2_DOOR_RRRH : 34|1@1+ (1,0) [0|1] "" Vector__XXX
 SG_ BIU3AC_4_3_DOOR_RRLH : 35|1@1+ (1,0) [0|1] "" Vector__XXX
 SG_ BIU3AC_4_4_DOOR_RG : 36|1@1+ (1,0) [0|1] "" Vector__XXX
 SG_ BIU3AC_4_5_DOOR_TR : 37|1@1+ (1,0) [0|1] "" Vector__XXX
 SG_ BIU3AC_4_6_HOOD_CLOSE : 38|1@1+ (1,0) [0|1] "" Vector__XXX
 SG_ BIU3AC_4_7_HOOD_OPEN : 39|1@1+ (1,0) [0|1] "" Vector__XXX
 SG_ BIU3AC_3_0_GW_STSW_RES : 24|1@1+ (1,0) [0|1] "" Vector__XXX
 SG_ BIU3AC_3_1_GW_POWER_RES : 25|2@1+ (1,0) [0|2] "" Vector__XXX
 SG_ BIU3AC_3_3_ST1 : 27|1@1+ (1,0) [0|1] "" Vector__XXX
 SG_ BIU3AC_3_4_ST2 : 28|1@1+ (1,0) [0|1] "" Vector__XXX
 SG_ BIU3AC_3_5_ACC : 29|1@1+ (1,0) [0|1] "" Vector__XXX
 SG_ BIU3AC_3_6_IGA : 30|1@1+ (1,0) [0|1] "" Vector__XXX
 SG_ BIU3AC_3_7_BAT_BACKUP : 31|1@1+ (1,0) [0|1] "" Vector__XXX
 SG_ BIU3AC_2_0_CSTM_AC : 16|1@1+ (1,0) [0|1] "" Vector__XXX
 SG_ BIU3AC_2_1_IMB_SMT : 17|2@1+ (1,0) [0|3] "" Vector__XXX
 SG_ BIU3AC_2_3_CSTM_WGN_SDN : 19|1@1+ (1,0) [0|1] "" Vector__XXX
 SG_ BIU3AC_2_4_VAL_SEAT_BACK_CTSM : 20|1@1+ (1,0) [0|1] "" Vector__XXX
 SG_ BIU3AC_2_5_VAL_MIR_AFOLD_CTSM : 21|1@1+ (1,0) [0|1] "" Vector__XXX
 SG_ BIU3AC_2_6_VAL_MIR_RTILT_CTSM : 22|1@1+ (1,0) [0|1] "" Vector__XXX
 SG_ BIU3AC_2_7_WIPER_REAR : 23|1@1+ (1,0) [0|1] "" Vector__XXX
 SG_ BIU3AC_1_0_MSG_COUNTER : 8|4@1+ (1,0) [0|15] "" Vector__XXX
 SG_ BIU3AC_1_4_PADDLESHIFT_DOWN_SW : 12|1@1+ (1,0) [0|1] "" Vector__XXX
 SG_ BIU3AC_1_5_PADDLESHIFT_UP_SW : 13|1@1+ (1,0) [0|1] "" Vector__XXX
 SG_ BIU3AC_1_6_MANUALMODE_SW : 14|1@1+ (1,0) [0|1] "" Vector__XXX
 SG_ BIU3AC_0_0_CHECK_SUM : 0|8@1+ (1,0) [0|255] "" Vector__XXX

BO_ 1616 BIU650: 8 C_ECU_GW
 SG_ BIU650_7_0_Reserved : 56|1@1+ (1,0) [0|1] "" Vector__XXX
 SG_ BIU650_7_1_Reserved : 57|1@1+ (1,0) [0|1] "" Vector__XXX
 SG_ BIU650_7_2_Reserved : 58|1@1+ (1,0) [0|1] "" Vector__XXX
 SG_ BIU650_7_3_DOOR_LINK_SW_STS : 59|1@1+ (1,0) [0|1] "" Vector__XXX
 SG_ BIU650_7_4_Reserved : 60|1@1+ (1,0) [0|1] "" Vector__XXX
 SG_ BIU650_6_0_Reserved : 48|3@1+ (1,0) [0|7] "" Vector__XXX
 SG_ BIU650_6_3_RR_WIPER_STATUS : 51|2@1+ (1,0) [0|3] "" Vector__XXX
 SG_ BIU650_6_5_WIPER_SENSITIVITY_CTM : 53|2@1+ (1,0) [0|3] "" Vector__XXX
 SG_ BIU650_5_0_Reserved : 40|1@1+ (1,0) [0|1] "" Vector__XXX
 SG_ BIU650_5_1_Reserved : 41|1@1+ (1,0) [0|1] "" Vector__XXX
 SG_ BIU650_5_2_FMH_DOOR_LOCK : 42|2@1+ (1,0) [0|3] "" Vector__XXX
 SG_ BIU650_5_4_LMH_DOOR_LOCK : 44|2@1+ (1,0) [0|3] "" Vector__XXX
 SG_ BIU650_4_0_REQ_OPE_AUTOLIGHT : 32|2@1+ (1,0) [0|3] "" Vector__XXX
 SG_ BIU650_4_2_STATE_SHINSSR : 34|2@1+ (1,0) [0|3] "" Vector__XXX
 SG_ BIU650_4_4_STATE_RLS_FAIL : 36|2@1+ (1,0) [0|3] "" Vector__XXX
 SG_ BIU650_3_0_REQ_FWASHER_ITLOCK : 24|1@1+ (1,0) [0|1] "" Vector__XXX
 SG_ BIU650_3_1_FWIPER_RTN : 25|1@1+ (1,0) [0|1] "" Vector__XXX
 SG_ BIU650_3_2_TURN_LAMP_STATE_LEFT : 26|1@1+ (1,0) [0|1] "" Vector__XXX
 SG_ BIU650_3_3_TURN_LAMP_STATE_RIGHT : 27|1@1+ (1,0) [0|1] "" Vector__XXX
 SG_ BIU650_3_4_Reserved : 28|1@1+ (1,0) [0|1] "" Vector__XXX
 SG_ BIU650_2_0_HEADLAMP_SMALL_SW : 16|1@1+ (1,0) [0|1] "" Vector__XXX
 SG_ BIU650_2_1_HEADLAMP_LO_SW : 17|1@1+ (1,0) [0|1] "" Vector__XXX
 SG_ BIU650_2_2_HEADLAMP_OFF_SW : 18|1@1+ (1,0) [0|1] "" Vector__XXX
 SG_ BIU650_2_3_HEADLAMP_Hi_SW : 19|1@1+ (1,0) [0|1] "" Vector__XXX
 SG_ BIU650_2_4_HEAD_LAMP_PASS_SW : 20|1@1+ (1,0) [0|1] "" Vector__XXX
 SG_ BIU650_2_5_FFOG_SW : 21|1@1+ (1,0) [0|1] "" Vector__XXX
 SG_ BIU650_2_6_RFOG_SW : 22|1@1+ (1,0) [0|1] "" Vector__XXX
 SG_ BIU650_1_0_MSG_COUNTER : 8|4@1+ (1,0) [0|15] "" Vector__XXX
 SG_ BIU650_0_0_CHECK_SUM : 0|8@1+ (1,0) [0|255] "" Vector__XXX

BO_ 809 BST329: 8 C_ECU_GW
 SG_ BST329_2_0_WARN_BRAKE_RED : 16|1@1+ (1,0) [0|1] "" Vector__XXX
 SG_ BST329_1_0_MSG_COUNTER : 8|4@1+ (1,0) [0|15] "" Vector__XXX
 SG_ BST329_1_4_EB_HMI_WARNINGON : 12|1@1+ (1,0) [0|1] "" Vector__XXX
 SG_ BST329_1_5_WARN_BST_MET_LCD : 13|1@1+ (1,0) [0|1] "" Vector__XXX
 SG_ BST329_1_6_WARN_BST_RED : 14|1@1+ (1,0) [0|1] "" Vector__XXX
 SG_ BST329_0_0_CHECK_SUM : 0|8@1+ (1,0) [0|255] "" Vector__XXX

BO_ 811 EPB32B: 8 C_ECU_GW
 SG_ EPB32B_7_0_AVH_TARGET_PRESS : 56|8@1+ (0.0235,0) [0|255] "MPa" Vector__XXX
 SG_ EPB32B_6_0_VEHICLE_RUN_STOP_FLG : 48|2@1+ (1,0) [0|3] "" Vector__XXX
 SG_ EPB32B_6_2_REQ_HILL_P_CAUTION : 50|1@1+ (1,0) [0|1] "" Vector__XXX
 SG_ EPB32B_5_0_FLG_AVH_OILPRES_EPB : 40|1@1+ (1,0) [0|1] "" Vector__XXX
 SG_ EPB32B_5_1_FLG_AVH : 41|1@1+ (1,0) [0|1] "" Vector__XXX
 SG_ EPB32B_5_2_AVH_INTENSIFY_PRES : 42|1@1+ (1,0) [0|1] "" Vector__XXX
 SG_ EPB32B_5_3_BREAK_IND : 43|2@1+ (1,0) [0|3] "" Vector__XXX
 SG_ EPB32B_5_5_AVH_ON_LAMP : 45|1@1+ (1,0) [0|1] "" Vector__XXX
 SG_ EPB32B_5_6_AVH_FUNC_ON_LUMP : 46|1@1+ (1,0) [0|1] "" Vector__XXX
 SG_ EPB32B_5_7_AVH_ACTIVE : 47|1@1+ (1,0) [0|1] "" Vector__XXX
 SG_ EPB32B_4_0_BUZZER : 32|2@1+ (1,0) [0|3] "" Vector__XXX
 SG_ EPB32B_4_2_HILL_HOLD_ON_LAMP : 34|1@1+ (1,0) [0|1] "" Vector__XXX
 SG_ EPB32B_4_3_CLAMP_LAMP : 35|2@1+ (1,0) [0|3] "" Vector__XXX
 SG_ EPB32B_4_5_WARN_LAMP : 37|2@1+ (1,0) [0|3] "" Vector__XXX
 SG_ EPB32B_4_7_WARN_EPB_MET_LCD : 39|1@1+ (1,0) [0|1] "" Vector__XXX
 SG_ EPB32B_3_0_STATUS_EPB : 24|3@1+ (1,0) [0|7] "" Vector__XXX
 SG_ EPB32B_3_3_DYNAMIC_PARKING : 27|1@1+ (1,0) [0|1] "" Vector__XXX
 SG_ EPB32B_3_4_HILL_HOLD_RUN_FLG : 28|1@1+ (1,0) [0|1] "" Vector__XXX
 SG_ EPB32B_3_5_INHIBIT_ISS_DELAY : 29|1@1+ (1,0) [0|1] "" Vector__XXX
 SG_ EPB32B_3_6_INHIBIT_ISS : 30|1@1+ (1,0) [0|1] "" Vector__XXX
 SG_ EPB32B_3_7_AVH_PERMIT_CONT_ACC : 31|1@1+ (1,0) [0|1] "" Vector__XXX
 SG_ EPB32B_2_0_ERR_INFO : 16|2@1+ (1,0) [0|3] "" Vector__XXX
 SG_ EPB32B_2_2_EPB_FAIL_FLG1 : 18|1@1+ (1,0) [0|1] "" Vector__XXX
 SG_ EPB32B_2_3_EPB_FAIL_FLG2 : 19|1@1+ (1,0) [0|1] "" Vector__XXX
 SG_ EPB32B_2_4_EPB_FAIL_FLG3 : 20|1@1+ (1,0) [0|1] "" Vector__XXX
 SG_ EPB32B_1_0_MSG_COUNTER : 8|4@1+ (1,0) [0|15] "" Vector__XXX
 SG_ EPB32B_1_4_WAKE_UP_FRAME : 12|1@1+ (1,0) [0|1] "" Vector__XXX
 SG_ EPB32B_1_5_REQ_COMM_CONT : 13|1@1+ (1,0) [0|1] "" Vector__XXX
 SG_ EPB32B_1_6 : 14|1@1+ (1,0) [0|1] "" Vector__XXX
 SG_ EPB32B_0_0_CHECK_SUM : 0|8@1+ (1,0) [0|255] "" Vector__XXX

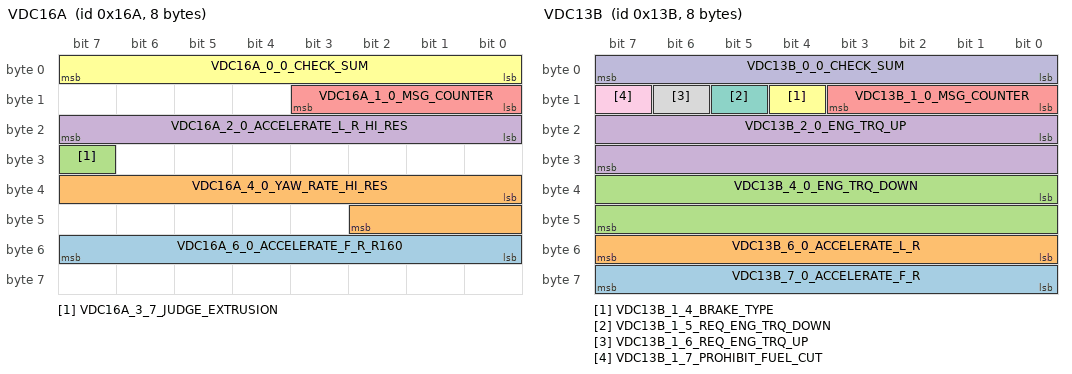
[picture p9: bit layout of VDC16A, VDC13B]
BO_ 362 VDC16A: 8 C_ECU_GW
 SG_ VDC16A_6_0_ACCELERATE_F_R_R160 : 48|8@1- (0.2,0) [-17.6|17.6] "m/s^2" Vector__XXX
 SG_ VDC16A_4_0_YAW_RATE_HI_RES : 32|11@1- (0.1,0) [-85|85] "deg/s" Vector__XXX
 SG_ VDC16A_3_7_JUDGE_EXTRUSION : 31|1@1+ (1,0) [0|1] "" Vector__XXX
 SG_ VDC16A_2_0_ACCELERATE_L_R_HI_RES : 16|8@1- (0.1,0) [-7|7] "m/s2" Vector__XXX
 SG_ VDC16A_1_0_MSG_COUNTER : 8|4@1+ (1,0) [0|15] "" Vector__XXX
 SG_ VDC16A_0_0_CHECK_SUM : 0|8@1+ (1,0) [0|255] "" Vector__XXX

BO_ 808 VDC328: 8 C_ECU_GW
 SG_ VDC328_7_1_IND_WARN_CBC : 57|1@1+ (1,0) [0|1] "" Vector__XXX
 SG_ VDC328_7_2_ACTIVATE_CBC : 58|1@1+ (1,0) [0|1] "" Vector__XXX
 SG_ VDC328_7_3_FLAG_ACT_CBC : 59|1@1+ (1,0) [0|1] "" Vector__XXX
 SG_ VDC328_6_0_PROHIBIT_VDC_OFF_CCU : 48|1@1+ (1,0) [0|1] "" Vector__XXX
 SG_ VDC328_6_1_PROHIBIT_AVH_CCU : 49|1@1+ (1,0) [0|1] "" Vector__XXX
 SG_ VDC328_5_0_VDC_BUZZER : 40|2@1+ (1,0) [0|3] "" Vector__XXX
 SG_ VDC328_5_2_WARN_BRAKE_BOOST : 42|1@1+ (1,0) [0|1] "" Vector__XXX
 SG_ VDC328_5_4_WARN_RBS : 44|2@1+ (1,0) [0|3] "" Vector__XXX
 SG_ VDC328_5_6_IND_HSA_ON : 46|1@1+ (1,0) [0|1] "" Vector__XXX
 SG_ VDC328_5_7_IND_TCS_OFF : 47|1@1+ (1,0) [0|1] "" Vector__XXX
 SG_ VDC328_4_0_IND_VDC_OFF : 32|1@1+ (1,0) [0|1] "" Vector__XXX
 SG_ VDC328_4_1_STATE_ACTIVATE_VDC : 33|1@1+ (1,0) [0|1] "" Vector__XXX
 SG_ VDC328_4_2_IND_HSA_OFF : 34|1@1+ (1,0) [0|1] "" Vector__XXX
 SG_ VDC328_4_3_IND_HDC : 35|2@1+ (1,0) [0|3] "" Vector__XXX
 SG_ VDC328_4_5_WARNING_BRAKE_SYS : 37|2@1+ (1,0) [0|3] "" Vector__XXX
 SG_ VDC328_4_7_ACTIVE_OHB : 39|1@1+ (1,0) [0|1] "" Vector__XXX
 SG_ VDC328_3_0_IND_WARN_EBD : 24|1@1+ (1,0) [0|1] "" Vector__XXX
 SG_ VDC328_3_1_IND_WARN_ABS : 25|1@1+ (1,0) [0|1] "" Vector__XXX
 SG_ VDC328_3_2_IND_WARN_VDC : 26|1@1+ (1,0) [0|1] "" Vector__XXX
 SG_ VDC328_3_3_IND_WARN_HSA : 27|1@1+ (1,0) [0|1] "" Vector__XXX
 SG_ VDC328_3_4_WARN_BRAKEFLUID_LV : 28|2@1+ (1,0) [0|3] "" Vector__XXX
 SG_ VDC328_3_6_IND_TCS_OFF : 30|1@1+ (1,0) [0|1] "" Vector__XXX
 SG_ VDC328_3_7_EXIST_EPB : 31|1@1+ (1,0) [0|1] "" Vector__XXX
 SG_ VDC328_2_0_WARN_EBD_MET_LCD : 16|1@1+ (1,0) [0|1] "" Vector__XXX
 SG_ VDC328_2_1_WARN_ABS_MET_LCD : 17|1@1+ (1,0) [0|1] "" Vector__XXX
 SG_ VDC328_2_2_WARN_VDC_MET_LCD : 18|1@1+ (1,0) [0|1] "" Vector__XXX
 SG_ VDC328_2_3_WARN_HSA_MET_LCD : 19|1@1+ (1,0) [0|1] "" Vector__XXX
 SG_ VDC328_2_4_EXIST_VECTARING : 20|1@1+ (1,0) [0|1] "" Vector__XXX
 SG_ VDC328_1_0_MSG_COUNTER : 8|4@1+ (1,0) [0|15] "" Vector__XXX
 SG_ VDC328_0_0_CHECK_SUM : 0|8@1+ (1,0) [0|255] "" Vector__XXX

BO_ 315 VDC13B: 8 C_ECU_GW
 SG_ VDC13B_7_0_ACCELERATE_F_R : 56|8@1- (0.1,0) [-12.5|12.5] "m/s^2" Vector__XXX
 SG_ VDC13B_6_0_ACCELERATE_L_R : 48|8@1- (0.1923,0) [-17.64|17.64] "m/s^2" Vector__XXX
 SG_ VDC13B_4_0_ENG_TRQ_DOWN : 32|16@1+ (0.1,-1000) [-1000|5553.5] "Nm" Vector__XXX
 SG_ VDC13B_2_0_ENG_TRQ_UP : 16|16@1+ (0.1,-1000) [-1000|5553.5] "Nm" Vector__XXX
 SG_ VDC13B_1_0_MSG_COUNTER : 8|4@1+ (1,0) [0|15] "" Vector__XXX
 SG_ VDC13B_1_4_BRAKE_TYPE : 12|1@1+ (1,0) [0|1] "" Vector__XXX
 SG_ VDC13B_1_5_REQ_ENG_TRQ_DOWN : 13|1@1+ (1,0) [0|1] "" Vector__XXX
 SG_ VDC13B_1_6_REQ_ENG_TRQ_UP : 14|1@1+ (1,0) [0|1] "" Vector__XXX
 SG_ VDC13B_1_7_PROHIBIT_FUEL_CUT : 15|1@1+ (1,0) [0|1] "" Vector__XXX
 SG_ VDC13B_0_0_CHECK_SUM : 0|8@1+ (1,0) [0|255] "" Vector__XXX

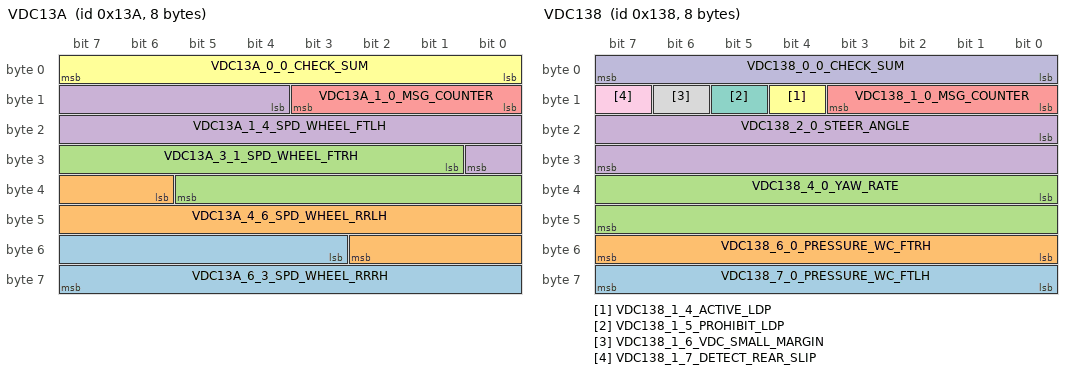
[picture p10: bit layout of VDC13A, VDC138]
BO_ 314 VDC13A: 8 C_ECU_GW
 SG_ VDC13A_6_3_SPD_WHEEL_RRRH : 51|13@1+ (0.05625,0) [0|299.98125] "km/h" Vector__XXX
 SG_ VDC13A_4_6_SPD_WHEEL_RRLH : 38|13@1+ (0.05625,0) [0|299.98125] "km/h" Vector__XXX
 SG_ VDC13A_3_1_SPD_WHEEL_FTRH : 25|13@1+ (0.05625,0) [0|299.98125] "km/h" Vector__XXX
 SG_ VDC13A_1_4_SPD_WHEEL_FTLH : 12|13@1+ (0.05625,0) [0|299.98125] "km/h" Vector__XXX
 SG_ VDC13A_1_0_MSG_COUNTER : 8|4@1+ (1,0) [0|15] "" Vector__XXX
 SG_ VDC13A_0_0_CHECK_SUM : 0|8@1+ (1,0) [0|255] "" Vector__XXX

BO_ 313 VDC139: 8 C_ECU_GW
 SG_ VDC139_7_4_FAIL_PRESSURE_SSR : 60|1@1+ (1,0) [0|1] "" Vector__XXX
 SG_ VDC139_7_5_STATUS_EPB : 61|3@1+ (1,0) [0|7] "" Vector__XXX
 SG_ VDC139_6_0_SSR_N_PRESS : 48|12@1+ (1,0) [193|3896] "" Vector__XXX
 SG_ VDC139_5_0_PRESSURE_BRAKE : 40|8@1+ (0.13058823529412,0) [0|25] "MPa" Vector__XXX
 SG_ VDC139_4_0_HDC_STATUS : 32|2@1+ (1,0) [0|3] "" Vector__XXX
 SG_ VDC139_4_2_BRAKELAMPSW : 34|1@1+ (1,0) [0|1] "" Vector__XXX
 SG_ VDC139_4_3_FAIL_BRAKELAMPSW : 35|1@1+ (1,0) [0|1] "" Vector__XXX
 SG_ VDC139_4_4_ACTIVATE_ABS : 36|1@1+ (1,0) [0|1] "" Vector__XXX
 SG_ VDC139_4_5_ACTIVATE_TCS : 37|1@1+ (1,0) [0|1] "" Vector__XXX
 SG_ VDC139_4_6_CONT_OVER_STR : 38|1@1+ (1,0) [0|1] "" Vector__XXX
 SG_ VDC139_4_7_CONT_UNDER_STR : 39|1@1+ (1,0) [0|1] "" Vector__XXX
 SG_ VDC139_3_5_FAIL_VDC_SSR : 29|1@1+ (1,0) [0|1] "" Vector__XXX
 SG_ VDC139_3_6_FAIL_SPD_SSR_FHI : 30|1@1+ (1,0) [0|1] "" Vector__XXX
 SG_ VDC139_3_7_FAIL_ABS_SYS : 31|1@1+ (1,0) [0|1] "" Vector__XXX
 SG_ VDC139_2_0_SPD_WHEEL_AVE : 16|13@1+ (0.05625,0) [0|299.98125] "km/h" Vector__XXX
 SG_ VDC139_1_0_MSG_COUNTER : 8|4@1+ (1,0) [0|15] "" Vector__XXX
 SG_ VDC139_1_4_FAIL_HDC_SYS : 12|1@1+ (1,0) [0|1] "" Vector__XXX
 SG_ VDC139_1_5_VEHICLE_HIGHT : 13|2@1+ (1,0) [0|2] "" Vector__XXX
 SG_ VDC139_1_7_REPROGRAMING : 15|1@1+ (1,0) [0|1] "" Vector__XXX
 SG_ VDC139_0_0_CHECK_SUM : 0|8@1+ (1,0) [0|255] "" Vector__XXX

BO_ 312 VDC138: 8 C_ECU_GW
 SG_ VDC138_7_0_PRESSURE_WC_FTLH : 56|8@1+ (0.08,0) [0|20.4] "MPa" Vector__XXX
 SG_ VDC138_6_0_PRESSURE_WC_FTRH : 48|8@1+ (0.08,0) [0|20.4] "MPa" Vector__XXX
 SG_ VDC138_4_0_YAW_RATE : 32|16@1- (0.0047358121330724,0) [-1.571|1.571] "rad/s" Vector__XXX
 SG_ VDC138_2_0_STEER_ANGLE : 16|16@1- (0.1,0) [-719.9|719.9] "deg" Vector__XXX
 SG_ VDC138_1_0_MSG_COUNTER : 8|4@1+ (1,0) [0|15] "" Vector__XXX
 SG_ VDC138_1_4_ACTIVE_LDP : 12|1@1+ (1,0) [0|1] "" Vector__XXX
 SG_ VDC138_1_5_PROHIBIT_LDP : 13|1@1+ (1,0) [0|1] "" Vector__XXX
 SG_ VDC138_1_6_VDC_SMALL_MARGIN : 14|1@1+ (1,0) [0|1] "" Vector__XXX
 SG_ VDC138_1_7_DETECT_REAR_SLIP : 15|1@1+ (1,0) [0|1] "" Vector__XXX
 SG_ VDC138_0_0_CHECK_SUM : 0|8@1+ (1,0) [0|255] "" Vector__XXX

BO_ 1143 CCU477: 32 C_ECU_GW
 SG_ CCU477_28_4_Reserved : 228|4@1+ (1,0) [0|16] "" Vector__XXX
 SG_ CCU477_28_2_TIM_CHG_CHG_FLG : 226|1@1+ (1,0) [0|3] "" Vector__XXX
 SG_ CCU477_28_0_TIM_CHG_ICON_DISP : 224|2@1+ (1,0) [0|3] "" Vector__XXX
 SG_ CCU477_27_4_TIM_CHG_STATUS : 220|4@1+ (1,0) [0|15] ""  EVCC
 SG_ CCU477_27_1_DEP_TIM_PRE_CON_FLAG : 217|3@1+ (1,0) [0|7] "" Vector__XXX
 SG_ CCU477_27_0_TIM_CHG_PERM_FLAG : 216|1@1+ (1,0) [0|1] "" Vector__XXX
 SG_ CCU477_26_0_TIM4_CHG_WEEK_DAYS : 208|8@1+ (1,0) [0|255] "" Vector__XXX
 SG_ CCU477_25_3_Reserved : 203|5@1+ (1,0) [0|31] "" Vector__XXX
 SG_ CCU477_24_0_TIM4_CHG_END_TIME : 192|11@1+ (1,0) [0|1439] "min" Vector__XXX
 SG_ CCU477_23_5_Reserved : 189|3@1+ (1,0) [0|7] "" Vector__XXX
 SG_ CCU477_22_2_TIM4_CHG_START_TIME : 178|11@1+ (1,0) [0|1439] "min" Vector__XXX
 SG_ CCU477_22_0_TIM4_CHG_SET_TYPE : 176|2@1+ (1,0) [0|3] "" Vector__XXX
 SG_ CCU477_21_7_Reserved : 175|1@1+ (1,0) [0|1] "" Vector__XXX
 SG_ CCU477_21_5_TIM4_CHG_SW_STS : 173|2@1+ (1,0) [0|3] "" Vector__XXX
 SG_ CCU477_21_0_TIM4_DISP_ID : 168|5@1+ (1,0) [0|31] "" Vector__XXX
 SG_ CCU477_20_0_TIM3_CHG_WEEK_DAYS : 160|8@1+ (1,0) [0|255] "" Vector__XXX
 SG_ CCU477_19_3_Reserved : 155|5@1+ (1,0) [0|31] "" Vector__XXX
 SG_ CCU477_18_0_TIM3_CHG_END_TIME : 144|11@1+ (1,0) [0|1439] "min" Vector__XXX
 SG_ CCU477_17_5_Reserved : 141|3@1+ (1,0) [0|7] "" Vector__XXX
 SG_ CCU477_16_2_TIM3_CHG_START_TIME : 130|11@1+ (1,0) [0|1439] "min" Vector__XXX
 SG_ CCU477_16_0_TIM3_CHG_SET_TYPE : 128|2@1+ (1,0) [0|3] "" Vector__XXX
 SG_ CCU477_15_7_Reserved : 127|1@1+ (1,0) [0|1] "" Vector__XXX
 SG_ CCU477_15_5_TIM3_CHG_SW_STS : 125|2@1+ (1,0) [0|3] "" Vector__XXX
 SG_ CCU477_15_0_TIM3_DISP_ID : 120|5@1+ (1,0) [0|31] "" Vector__XXX
 SG_ CCU477_14_0_TIM2_CHG_WEEK_DAYS : 112|8@1+ (1,0) [0|255] "" Vector__XXX
 SG_ CCU477_13_3_Reserved : 107|5@1+ (1,0) [0|31] "" Vector__XXX
 SG_ CCU477_12_0_TIM2_CHG_END_TIME : 96|11@1+ (1,0) [0|1439] "min" Vector__XXX
 SG_ CCU477_11_5_Reserved : 93|3@1+ (1,0) [0|7] "" Vector__XXX
 SG_ CCU477_10_2_TIM2_CHG_START_TIME : 82|11@1+ (1,0) [0|1439] "min" Vector__XXX
 SG_ CCU477_10_0_TIM2_CHG_SET_TYPE : 80|2@1+ (1,0) [0|3] "" Vector__XXX
 SG_ CCU477_9_7_Reserved : 79|1@1+ (1,0) [0|1] "" Vector__XXX
 SG_ CCU477_9_5_TIM2_CHG_SW_STS : 77|2@1+ (1,0) [0|3] "" Vector__XXX
 SG_ CCU477_9_0_TIM2_DISP_ID : 72|5@1+ (1,0) [0|31] "" Vector__XXX
 SG_ CCU477_8_0_TIM1_CHG_WEEK_DAYS : 64|8@1+ (1,0) [0|255] "" Vector__XXX
 SG_ CCU477_7_3_Reserved : 59|5@1+ (1,0) [0|31] "" Vector__XXX
 SG_ CCU477_6_0_TIM1_CHG_END_TIME : 48|11@1+ (1,0) [0|1439] "min" Vector__XXX
 SG_ CCU477_5_5_Reserved : 45|3@1+ (1,0) [0|7] "" Vector__XXX
 SG_ CCU477_4_2_TIM1_CHG_START_TIME : 34|11@1+ (1,0) [0|1439] "min" Vector__XXX
 SG_ CCU477_4_0_TIM1_CHG_SET_TYPE : 32|2@1+ (1,0) [0|3] "" Vector__XXX
 SG_ CCU477_3_7_Reserved : 31|1@1+ (1,0) [0|1] "" Vector__XXX
 SG_ CCU477_3_5_TIM1_CHG_SW_STS : 29|2@1+ (1,0) [0|3] "" Vector__XXX
 SG_ CCU477_3_0_TIM1_DISP_ID : 24|5@1+ (1,0) [0|31] "" Vector__XXX
 SG_ CCU477_2_0_E2E_COUNTER : 16|8@1+ (1,0) [0|255] ""  EVCC
 SG_ CCU477_0_0_E2E_CRC : 0|16@1+ (1,0) [0|65535] ""  EVCC

BO_ 1142 CCU476: 32 C_ECU_GW
 SG_ CCU476_17_2_SW_STOP_CHG : 138|1@1+ (1,0) [0|1] "" Vector__XXX
 SG_ CCU476_17_1_SW_NORMAL_MOD_CHG : 137|1@1+ (1,0) [0|1] "" Vector__XXX
 SG_ CCU476_17_0_SW_PWR_MOD_CHG : 136|1@1+ (1,0) [0|1] "" Vector__XXX
 SG_ CCU476_16_4_AC_CUR_MAX_LIM_CHG : 132|4@1+ (1,0) [0|6] "A" Vector__XXX
 SG_ CCU476_16_0_DC_PWR_MAX_LIM_CHG : 128|4@1+ (1,0) [0|8] "kW" Vector__XXX
 SG_ CCU476_15_0_SOC_MAX_LIM_CHG : 120|7@1+ (1,0) [0|100] "%" Vector__XXX
 SG_ CCU476_14_0_HIS_ID_PNC : 112|7@1+ (1,0) [0|100] "" Vector__XXX
 SG_ CCU476_13_5_SW_CAUTION_PNC : 109|1@1+ (1,0) [0|1] "" Vector__XXX
 SG_ CCU476_13_4_SW_NEW_PNC : 108|1@1+ (1,0) [0|1] "" Vector__XXX
 SG_ CCU476_13_3_START_CTR_PNC : 107|1@1+ (1,0) [0|1] "" Vector__XXX
 SG_ CCU476_13_1_STS_PNC : 105|2@1+ (1,0) [0|3] "" Vector__XXX
 SG_ CCU476_13_0_DESC_PNC : 104|1@1+ (1,0) [0|1] "" Vector__XXX
 SG_ CCU476_11_1_STOP_TIM_TIM_CHG : 89|9@1+ (5,0) [0|1435] "" Vector__XXX
 SG_ CCU476_10_0_START_TIM_TIM_CHG : 80|9@1+ (5,0) [0|1435] "" Vector__XXX
 SG_ CCU476_9_0_WKD_SET_TIM_CHG : 72|3@1+ (1,0) [0|7] "" Vector__XXX
 SG_ CCU476_8_0_LOGIN_REQ_TIM_CHG : 64|2@1+ (1,0) [0|3] "" Vector__XXX
 SG_ CCU476_7_0_WKD_SEL_TIM_CHG : 56|7@1+ (1,0) [0|127] "" Vector__XXX
 SG_ CCU476_5_1_STOP_TIM_CH_TIM_CHG : 41|9@1+ (5,0) [0|1435] "" Vector__XXX
 SG_ CCU476_4_0_START_TIM_CH_TIM_CHG : 32|9@1+ (5,0) [0|1435] "" Vector__XXX
 SG_ CCU476_3_0_PNC_SW_REQ_CCU : 24|3@1+ (1,0) [0|5] ""  EVCC
 SG_ CCU476_2_7_SW_TIM_CHG : 23|1@1+ (1,0) [0|1] "" Vector__XXX
 SG_ CCU476_2_0_E2E_COUNTER : 16|8@1+ (1,0) [0|255] ""  EVCC
 SG_ CCU476_0_0_E2E_CRC : 0|16@1+ (1,0) [0|65535] ""  EVCC

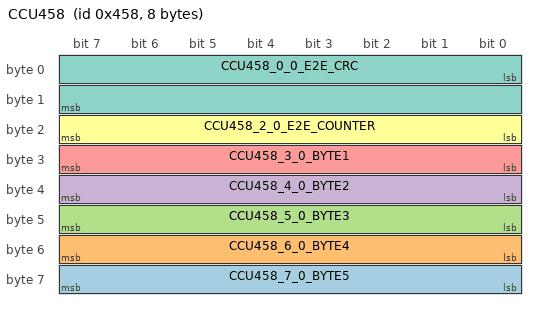
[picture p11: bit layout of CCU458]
BO_ 1112 CCU458: 8 C_ECU_GW
 SG_ CCU458_7_0_BYTE5 : 56|8@1+ (1,0) [0|255] ""  EVCC
 SG_ CCU458_6_0_BYTE4 : 48|8@1+ (1,0) [0|255] ""  EVCC
 SG_ CCU458_5_0_BYTE3 : 40|8@1+ (1,0) [0|255] ""  EVCC
 SG_ CCU458_4_0_BYTE2 : 32|8@1+ (1,0) [0|255] ""  EVCC
 SG_ CCU458_3_0_BYTE1 : 24|8@1+ (1,0) [0|255] ""  EVCC
 SG_ CCU458_2_0_E2E_COUNTER : 16|8@1+ (1,0) [0|255] ""  EVCC
 SG_ CCU458_0_0_E2E_CRC : 0|16@1+ (1,0) [0|65535] ""  EVCC

CM_ SG_ 803 EYE323_7_0_ISA_OFFSET_CURR "ISA制限車速オフセット値
";
CM_ SG_ 803 EYE323_7_5_SLIF_FUNC_INFO "標識認識機能有無情報
";
CM_ SG_ 803 EYE323_7_6_ISA_FUNC_INFO "ISA機能有無情報
";
CM_ SG_ 803 EYE323_7_7_ISA_CUSTOMIZE_CURR "ｱｲｻｲﾄｶｽﾀﾏｲｽﾞ現在設定値(ISA)
";
CM_ SG_ 803 EYE323_6_0_LDW_OFFSW_INFO "LDW音　OFFスイッチ有無
";
CM_ SG_ 803 EYE323_6_1_LDW_ON_OFF_SET "LDW音 ON/OFF現在設定値
";
CM_ SG_ 803 EYE323_6_2_CSTM_DDAW_WARN_SET "カスタマイズ現在値(DDAW警報)
";
CM_ SG_ 803 EYE323_6_3_IACC_FUNC_INFO "iACC機能有無フラグ
";
CM_ SG_ 803 EYE323_6_5_CSTM_LDW_TIMING_SET "LDWタイミングカスタマイズ現在設定値
";
CM_ SG_ 803 EYE323_6_6_CSTM_LDW_TIMING "LDWタイミングカスタマイズ有無
";
CM_ SG_ 803 EYE323_6_7_SLOWDOWNL_FUNC_INFO "カーブ前減速機能有無
";
CM_ SG_ 803 EYE323_5_0_CNG_GRN_CONT_CURR "カスタマイズ現在値（青信号切り替わりお知らせ）
";
CM_ SG_ 803 EYE323_5_1_TRAFFIC_FUNC_INFO "信号制御機能有無
";
CM_ SG_ 803 EYE323_5_2_FCW_OFFSW_INFO "FCW OFFスイッチ有無
";
CM_ SG_ 803 EYE323_5_3_FCW_ON_OFF_SET "FCW ON/OFF現在設定値
";
CM_ SG_ 803 EYE323_5_4_WARNING_SEL_CURR "カスタマイズ現在値（警報方法）
";
CM_ SG_ 803 EYE323_5_5_HAPT_FUNC_INFO "ステア振動（警報方法）機能有無
";
CM_ SG_ 803 EYE323_5_6_TOLLGATE_CONT_CURR "カスタマイズ現在値（料金所減速 ）
";
CM_ SG_ 803 EYE323_5_7_CURVE_CONT_CURR "カスタマイズ現在値（カーブ減速 ）
";
CM_ SG_ 803 EYE323_4_0_FCTB_ICON_L "FCTBお知らせアイコン_左
";
CM_ SG_ 803 EYE323_4_2_FCTB_ICON_R "FCTBお知らせアイコン_右
";
CM_ SG_ 803 EYE323_4_4_FCW_CONT_CURR "カスタマイズ現在値（FCW)
";
CM_ SG_ 803 EYE323_4_6_FCW_DISPLAY_SEL "FCWカスタマイズ項目表示指示
";
CM_ SG_ 803 EYE323_3_0_AES_FUNC_INFO "AES機能有無
";
CM_ SG_ 803 EYE323_3_1_CSTM_TSR_NO_ENTRY_SET "カスタマイズ現在値(進入禁止標識)
";
CM_ SG_ 803 EYE323_3_2_CSTM_TSR_STOP_SET "カスタマイズ現在値(一時停止標識)
";
CM_ SG_ 803 EYE323_3_3_CSTM_TSR_GIVE_WAY_SET "カスタマイズ現在値(前方優先道路標識)
";
CM_ SG_ 803 EYE323_3_4_WILDERNESS "Wilderness識別情報
";
CM_ SG_ 803 EYE323_3_5_AES_OFF "AES  OFFｲﾝｼﾞｹｰﾀ信号
";
CM_ SG_ 803 EYE323_3_6_FCTB_IND "FCTBインジケータ
";
CM_ SG_ 803 EYE323_2_0_CSTM_LDW_ALK_B "ｱｲｻｲﾄｶｽﾀﾏｲｽﾞ現在値設定（LDW/ALK-B）
";
CM_ SG_ 803 EYE323_2_2_CSTM_P_CR "ｱｲｻｲﾄｶｽﾀﾏｲｽﾞ現在値設定（P-CR）
";
CM_ SG_ 803 EYE323_2_3_SLOWDOWN_FUNC_INFO2 "料金所前減速機能有無
";
CM_ SG_ 803 EYE323_2_4_CID_CODE_WARN "CID警報ｺｰﾄﾞ
";
CM_ SG_ 803 EYE323_1_0_MSG_COUNTER "ﾒｯｾｰｼﾞｶｳﾝﾀ
";
CM_ SG_ 803 EYE323_1_4_DISP_FOLLOW_FORWARD "先行車追従表示フラグ
";
CM_ SG_ 803 EYE323_1_5_KEEP_LINE_SENTER_ACT "白線中央維持制御中フラグ
";
CM_ SG_ 803 EYE323_1_6_DDAW_FAIL_OFF "DDAW故障/OFF灯
";
CM_ SG_ 803 EYE323_0_0_CHECK_SUM "ﾁｪｯｸｻﾑ
";
CM_ SG_ 2564481222 EVCC18DAE0C6_DIAG_DATA "ﾃﾞｰﾀ
";
CM_ SG_ 2564474592 DNT18DAC6E0_DIAG_DATA "ﾃﾞｰﾀ
";
CM_ SG_ 2564481219 EVCC18DAE0C3_DIAG_DATA "ﾃﾞｰﾀ
";
CM_ SG_ 2564473824 DNT18DAC3E0_DIAG_DATA "ﾃﾞｰﾀ
";
CM_ SG_ 2564481478 EVCC18DAE1C6_DIAG_DATA_EXT7 "ﾃﾞｰﾀ
";
CM_ SG_ 2564481478 EVCC18DAE1C6_DIAG_DATA_EXT6 "ﾃﾞｰﾀ
";
CM_ SG_ 2564481478 EVCC18DAE1C6_DIAG_DATA_EXT5 "ﾃﾞｰﾀ
";
CM_ SG_ 2564481478 EVCC18DAE1C6_DIAG_DATA_EXT4 "ﾃﾞｰﾀ
";
CM_ SG_ 2564481478 EVCC18DAE1C6_DIAG_DATA_EXT3 "ﾃﾞｰﾀ
";
CM_ SG_ 2564481478 EVCC18DAE1C6_DIAG_DATA_EXT2 "ﾃﾞｰﾀ
";
CM_ SG_ 2564481478 EVCC18DAE1C6_DIAG_DATA_EXT1 "ﾃﾞｰﾀ
";
CM_ SG_ 2564481478 EVCC18DAE1C6_DIAG_DATA "ﾃﾞｰﾀ
";
CM_ SG_ 2564474593 CECU18DAC6E1_DIAG_DATA_EXT7 "ﾃﾞｰﾀ
";
CM_ SG_ 2564474593 CECU18DAC6E1_DIAG_DATA_EXT6 "ﾃﾞｰﾀ
";
CM_ SG_ 2564474593 CECU18DAC6E1_DIAG_DATA_EXT5 "ﾃﾞｰﾀ
";
CM_ SG_ 2564474593 CECU18DAC6E1_DIAG_DATA_EXT4 "ﾃﾞｰﾀ
";
CM_ SG_ 2564474593 CECU18DAC6E1_DIAG_DATA_EXT3 "ﾃﾞｰﾀ
";
CM_ SG_ 2564474593 CECU18DAC6E1_DIAG_DATA_EXT2 "ﾃﾞｰﾀ
";
CM_ SG_ 2564474593 CECU18DAC6E1_DIAG_DATA_EXT1 "ﾃﾞｰﾀ
";
CM_ SG_ 2564474593 CECU18DAC6E1_DIAG_DATA "ﾃﾞｰﾀ
";
CM_ SG_ 2564481475 EVCC18DAE1C3_DIAG_DATA_EXT7 "ﾃﾞｰﾀ
";
CM_ SG_ 2564481475 EVCC18DAE1C3_DIAG_DATA_EXT6 "ﾃﾞｰﾀ
";
CM_ SG_ 2564481475 EVCC18DAE1C3_DIAG_DATA_EXT5 "ﾃﾞｰﾀ
";
CM_ SG_ 2564481475 EVCC18DAE1C3_DIAG_DATA_EXT4 "ﾃﾞｰﾀ
";
CM_ SG_ 2564481475 EVCC18DAE1C3_DIAG_DATA_EXT3 "ﾃﾞｰﾀ
";
CM_ SG_ 2564481475 EVCC18DAE1C3_DIAG_DATA_EXT2 "ﾃﾞｰﾀ
";
CM_ SG_ 2564481475 EVCC18DAE1C3_DIAG_DATA_EXT1 "ﾃﾞｰﾀ
";
CM_ SG_ 2564481475 EVCC18DAE1C3_DIAG_DATA "ﾃﾞｰﾀ
";
CM_ SG_ 2564473825 CECU18DAC3E1_DIAG_DATA_EXT7 "ﾃﾞｰﾀ
";
CM_ SG_ 2564473825 CECU18DAC3E1_DIAG_DATA_EXT6 "ﾃﾞｰﾀ
";
CM_ SG_ 2564473825 CECU18DAC3E1_DIAG_DATA_EXT5 "ﾃﾞｰﾀ
";
CM_ SG_ 2564473825 CECU18DAC3E1_DIAG_DATA_EXT4 "ﾃﾞｰﾀ
";
CM_ SG_ 2564473825 CECU18DAC3E1_DIAG_DATA_EXT3 "ﾃﾞｰﾀ
";
CM_ SG_ 2564473825 CECU18DAC3E1_DIAG_DATA_EXT2 "ﾃﾞｰﾀ
";
CM_ SG_ 2564473825 CECU18DAC3E1_DIAG_DATA_EXT1 "ﾃﾞｰﾀ
";
CM_ SG_ 2564473825 CECU18DAC3E1_DIAG_DATA "ﾃﾞｰﾀ
";
CM_ SG_ 1100 EVCC44C_2_0_E2E_COUNTER "E2Eカウンタ
";
CM_ SG_ 1100 EVCC44C_0_0_E2E_CRC "CRC
";
CM_ SG_ 1099 EVCC44B_27_0_EVSE_ID_7_EVCC "EVSE ID_7_EVCC
";
CM_ SG_ 1099 EVCC44B_23_0_EVSE_ID_6_EVCC "EVSE ID_6_EVCC
";
CM_ SG_ 1099 EVCC44B_19_0_EVSE_ID_5_EVCC "EVSE ID_5_EVCC
";
CM_ SG_ 1099 EVCC44B_15_0_EVSE_ID_4_EVCC "EVSE ID_4_EVCC
";
CM_ SG_ 1099 EVCC44B_11_0_EVSE_ID_3_EVCC "EVSE ID_3_EVCC
";
CM_ SG_ 1099 EVCC44B_7_0_EVSE_ID_2_EVCC "EVSE ID_2_EVCC
";
CM_ SG_ 1099 EVCC44B_3_0_EVSE_ID_1_EVCC "EVSE ID_1_EVCC
";
CM_ SG_ 1099 EVCC44B_2_0_E2E_COUNTER "E2Eカウンタ
";
CM_ SG_ 1099 EVCC44B_0_0_E2E_CRC "CRC
";
CM_ SG_ 1098 EVCC44A_3_0_PNC_CC_SAVE_RES_RSLT "PnC契約関連証明書保存応答
";
CM_ SG_ 1098 EVCC44A_2_0_E2E_COUNTER "E2Eカウンタ
";
CM_ SG_ 1098 EVCC44A_0_0_E2E_CRC "CRC
";
CM_ SG_ 1097 EVCC449_2_0_E2E_COUNTER "E2Eカウンタ
";
CM_ SG_ 1097 EVCC449_0_0_E2E_CRC "CRC
";
CM_ SG_ 1096 EVCC448_4_0_EVSECONFPAYOPT "支払い方式
";
CM_ SG_ 1096 EVCC448_3_0_PNC_SW_RES_EVCC "PnCサービスONOFF切替応答_EVCC
";
CM_ SG_ 1096 EVCC448_3_4_PNC_SW_STS "PnC_ONOFFLOCK状態表示
";
CM_ SG_ 1096 EVCC448_3_7_SW_STS_ACTIVE_FLG "PnC状態表示_変化有無フラグ_EVCC
";
CM_ SG_ 1096 EVCC448_2_0_E2E_COUNTER "E2Eカウンタ
";
CM_ SG_ 1096 EVCC448_0_0_E2E_CRC "CRC
";
CM_ SG_ 1095 EVCC447_3_4_CHGWAKE "車両システム起動要求
";
CM_ SG_ 1095 EVCC447_3_0_CHGMODE "充放電モード
";
CM_ SG_ 1095 EVCC447_2_0_E2E_COUNTER "E2Eカウンタ
";
CM_ SG_ 1095 EVCC447_0_0_E2E_CRC "CRC
";
CM_ SG_ 1094 EVCC446_3_0_CHGMODE "充放電モード
";
CM_ SG_ 1094 EVCC446_3_3_CHGFRM "充電方式
";
CM_ SG_ 1094 EVCC446_3_7_CHGCONNSTA "充電コネクタ接続状態
";
CM_ SG_ 1094 EVCC446_2_0_E2E_COUNTER "E2Eカウンタ
";
CM_ SG_ 1094 EVCC446_0_0_E2E_CRC "CRC
";
CM_ SG_ 1093 EVCC445_4_0_CHGCNRLOCSTT_DISPREQ "充電コネクタロック状態表示要求
";
CM_ SG_ 1093 EVCC445_3_0_DISPREQ "App表示要求ステータス
";
CM_ SG_ 1093 EVCC445_3_1_CNCTCONSTT_DISP "充電コネクタ接続状態
";
CM_ SG_ 1093 EVCC445_3_2_LIDOPSHSTT_DISP "リッド開閉状態
";
CM_ SG_ 1093 EVCC445_3_5_CNCTLCKSTT_DISP "充電コネクタロック状態
";
CM_ SG_ 1093 EVCC445_2_0_E2E_COUNTER "E2Eカウンタ
";
CM_ SG_ 1093 EVCC445_0_0_E2E_CRC "CRC
";
CM_ SG_ 1092 EVCC444_3_0_CNTCPLTYP "接続カプラータイプ
";
CM_ SG_ 1092 EVCC444_3_2_CHGFRM_CCU "充電方式
";
CM_ SG_ 1092 EVCC444_2_0_E2E_COUNTER "E2Eカウンタ
";
CM_ SG_ 1092 EVCC444_0_0_E2E_CRC "CRC
";
CM_ SG_ 1305 EVCC519_1_4_ACTIVEWAKEUPBIT "Active Wakeup ﾌﾗｸﾞ
";
CM_ SG_ 1305 EVCC519_0_0_SOURCENODEID "送信元ID
";
CM_ SG_ 494 BEV1EE_3_0_VIN_DATA "VIN Data
";
CM_ SG_ 494 BEV1EE_2_0_VIN_BYTE_NO "VIN ByteNo
";
CM_ SG_ 494 BEV1EE_1_0_MSG_COUNTER "ﾒｯｾｰｼﾞｶｳﾝﾀ
";
CM_ SG_ 494 BEV1EE_0_0_CHECK_SUM "ﾁｪｯｸｻﾑ
";
CM_ SG_ 2564550625 CECU18DBEFE1_DIAG_DATA "ﾃﾞｰﾀ
";
CM_ SG_ 2564550624 DNT18DBEFE0_DIAG_DATA "ﾃﾞｰﾀ
";
CM_ SG_ 1832 DNT728_7_0_DIAG_DATA "ﾃﾞｰﾀ
";
CM_ SG_ 1832 DNT728_2_0_DIAG_N_PCI_OR_DATA "N_PCI　 or 　ﾃﾞｰﾀ
";
CM_ SG_ 1832 DNT728_1_0_DIAG_N_PCI_OR_DATA "N_PCI　 or 　ﾃﾞｰﾀ
";
CM_ SG_ 1832 DNT728_0_0_DIAG_N_PCI "N_PCI
";
CM_ SG_ 1280 CGW500_1_4_ActiveWakeUpBit "Active Wakeup ﾌﾗｸﾞ
";
CM_ SG_ 1280 CGW500_0_0_SourceNodeID "送信元ID
";
CM_ SG_ 1633 CECU661_7_0_PRESENT_TIME_SEC "現在時刻(秒)
";
CM_ SG_ 1633 CECU661_6_0_PRESENT_TIME_MIN "現在時刻(分)
";
CM_ SG_ 1633 CECU661_5_0_PRESENT_TIME_HOUR "現在時刻(時)
";
CM_ SG_ 1633 CECU661_4_0_PRESENT_DAY "現在年月日(日)
";
CM_ SG_ 1633 CECU661_3_0_PRESENT_MONTH "現在年月日(月)
";
CM_ SG_ 1633 CECU661_2_0_PRESENT_YEAR "現在年月日(年)
";
CM_ SG_ 1632 CGW660_7_0_COUNT_TIME "時間ｶｳﾝﾀ
";
CM_ SG_ 1632 CGW660_3_0_COUNT_TRIP "Tripｶｳﾝﾀ
";
CM_ SG_ 1632 CGW660_1_0_SUB_ID "ｻﾌﾞID
";
CM_ SG_ 1744 CECU6D0_4_0_OTA_ABORT "OTA中止
";
CM_ SG_ 1744 CECU6D0_4_1_OTA_SUSPEND "OTA中断
";
CM_ SG_ 1744 CECU6D0_4_2_OTA_SEQUENCE "OTA実行シーケンス
";
CM_ SG_ 1744 CECU6D0_1_0_MSG_COUNTER "ﾒｯｾｰｼﾞｶｳﾝﾀ
";
CM_ SG_ 1744 CECU6D0_1_4_OTA_STATUS_UPDATE "OTAステータス アップデート実行中
";
CM_ SG_ 1744 CECU6D0_0_0_CHECK_SUM "ﾁｪｯｸｻﾑ
";
CM_ SG_ 1743 DCM6CF_6_6_AACN_FLG "AACNフラグ
";
CM_ SG_ 1743 DCM6CF_5_0_EMERGENCY_CALL_ON_OFF "緊急通報ON/OFF
";
CM_ SG_ 1743 DCM6CF_4_2_STR_HEATER_ON_OFF "ｽﾃｱﾘﾝｸﾞﾋｰﾀｰ ON/OFF
";
CM_ SG_ 1743 DCM6CF_3_0_RES_CONTRACT_INFO "ﾘﾓｽﾀ契約情報
";
CM_ SG_ 1743 DCM6CF_3_1_REQ_ST_ON "Request ST ON
";
CM_ SG_ 1743 DCM6CF_3_3_ON_SIGN "E/G start signal
";
CM_ SG_ 1743 DCM6CF_3_5_REQ_PARKLIGHT_HORN "Request park light ＆Horn
";
CM_ SG_ 1743 DCM6CF_2_1_DCM_FAILURE_STATUS "DCM故障ｽﾃｰﾀｽ
";
CM_ SG_ 1743 DCM6CF_2_2_REQ_WINDOW_STATUS "窓&ｻﾝﾙｰﾌ開閉状態要求
";
CM_ SG_ 1743 DCM6CF_1_0_MSG_COUNTER "ﾒｯｾｰｼﾞｶｳﾝﾀ
";
CM_ SG_ 1743 DCM6CF_1_6_DKY_PROV_STS "DKCU向けDKY契約状態通知
";
CM_ SG_ 1743 DCM6CF_1_7_PNC_PROV_STS "EVCC向けPnC契約状態通知
";
CM_ SG_ 1743 DCM6CF_0_0_CHECK_SUM "ﾁｪｯｸｻﾑ
";
CM_ SG_ 1113 DCM459_7_0_BYTE5 "開発用変数5
";
CM_ SG_ 1113 DCM459_6_0_BYTE4 "開発用変数4
";
CM_ SG_ 1113 DCM459_5_0_BYTE3 "開発用変数3
";
CM_ SG_ 1113 DCM459_4_0_BYTE2 "開発用変数2
";
CM_ SG_ 1113 DCM459_3_0_BYTE1 "開発用変数1
";
CM_ SG_ 1113 DCM459_2_0_E2E_COUNTER "E2Eカウンタ
";
CM_ SG_ 1113 DCM459_0_0_E2E_CRC "CRC
";
CM_ SG_ 930 MET3A2_7_0_FUEL_AMOUNT "残燃料表示
";
CM_ SG_ 930 MET3A2_6_0_SEATBELT_RR_RH "ｼｰﾄﾍﾞﾙﾄﾊﾞｯｸﾙSW　後席右
";
CM_ SG_ 930 MET3A2_6_1_SEATBELT_RR_CTR "ｼｰﾄﾍﾞﾙﾄﾊﾞｯｸﾙSW　後席中央
";
CM_ SG_ 930 MET3A2_6_2_SEATBELT_RR_LH "ｼｰﾄﾍﾞﾙﾄﾊﾞｯｸﾙSW　後席左
";
CM_ SG_ 930 MET3A2_6_3_SEATBELT_THIRD_RH "ｼｰﾄﾍﾞﾙﾄﾊﾞｯｸﾙSW　3rd後席右
";
CM_ SG_ 930 MET3A2_6_4_SEATBELT_THIRD_CTR "ｼｰﾄﾍﾞﾙﾄﾊﾞｯｸﾙSW　3rd後席中央
";
CM_ SG_ 930 MET3A2_6_5_SEATBELT_THIRD_LH "ｼｰﾄﾍﾞﾙﾄﾊﾞｯｸﾙSW　3rd後席左
";
CM_ SG_ 930 MET3A2_5_0_FLG_RR_REMINDER "幼児置き去り警報実施フラグ
";
CM_ SG_ 930 MET3A2_2_0_ODO_DETAIL "オドﾒｰﾀ値
";
CM_ SG_ 930 MET3A2_1_0_MSG_COUNTER "ﾒｯｾｰｼﾞｶｳﾝﾀ
";
CM_ SG_ 930 MET3A2_1_4_FAIL_DISP "MET表示フェールフラグ
";
CM_ SG_ 930 MET3A2_0_0_CHECK_SUM "ﾁｪｯｸｻﾑ
";
CM_ SG_ 912 MET390_7_0_VDC_ON_OFF "VDC SW情報
";
CM_ SG_ 912 MET390_7_2_RR_DOOR_RECORD_L "後席ﾄﾞｱ開履歴送信（左）
";
CM_ SG_ 912 MET390_7_3_RR_DOOR_RECORD_R "後席ﾄﾞｱ開履歴送信（右）
";
CM_ SG_ 912 MET390_7_4_REQ_CHG_CSTM_PSM "PSMｶｽﾀﾏｲｽﾞ要求変更
";
CM_ SG_ 912 MET390_7_5_REQ_RESET_CSTM_PSM "PSM　ｶｽﾀﾏｲｽﾞﾘｾｯﾄ要求
";
CM_ SG_ 912 MET390_7_6_CSTM_MIR_AFOLD_CONT "ﾄﾞｱﾐﾗｰｶｽﾀﾏｲｽﾞ変更設定(ｵｰﾄ電動格納ﾐﾗｰ)
";
CM_ SG_ 912 MET390_7_7_CSTM_MIR_RTILT_CONT "ﾄﾞｱﾐﾗｰｶｽﾀﾏｲｽﾞ変更設定(ﾘﾊﾞｰｽ連動ﾐﾗｰ)
";
CM_ SG_ 912 MET390_6_0_SEATBELT_DRVR "ｼｰﾄﾍﾞﾙﾄﾊﾞｯｸﾙSW　D席
";
CM_ SG_ 912 MET390_6_1_SEATBELT_PASS "ｼｰﾄﾍﾞﾙﾄﾊﾞｯｸﾙSW　P席
";
CM_ SG_ 912 MET390_6_2_TURN_SIG_LEFT "ﾀｰﾝ左出力信号
";
CM_ SG_ 912 MET390_6_3_TURN_SIG_RIGHT "ﾀｰﾝ右出力信号
";
CM_ SG_ 912 MET390_6_4_BRIGHT_SW "ﾌﾞﾗｲﾄ信号
";
CM_ SG_ 912 MET390_6_5_FAIL_UART_WA_BOX "WA-BOX UART通信異常
";
CM_ SG_ 912 MET390_6_6_ISS_OFF_SW "ISS OFFｽｲｯﾁ状態
";
CM_ SG_ 912 MET390_6_7_FLG_DMS "DMS車両装備情報
";
CM_ SG_ 912 MET390_5_0_ILL_BRIGHTNESS "ｲﾙﾐ輝度値
";
CM_ SG_ 912 MET390_4_0_OUTTEMP_FOR_IND "表示用外気温
";
CM_ SG_ 912 MET390_3_0_UNIT_SPEED_TRIP "速度計/距離計表示単位
";
CM_ SG_ 912 MET390_3_1_FLG_EYESIGHT "EyeSightﾌﾗｸﾞ
";
CM_ SG_ 912 MET390_3_2_FLG_ISS "ISSﾌﾗｸﾞ
";
CM_ SG_ 912 MET390_3_3_FLG_HEV "HEVﾌﾗｸﾞ
";
CM_ SG_ 912 MET390_3_4_FLG_IMB "IMﾌﾗｸﾞ
";
CM_ SG_ 912 MET390_3_5_TIRE_SIZE "ﾀｲﾔ径情報
";
CM_ SG_ 912 MET390_3_6_FLG_XMODE "Xモード車両装備情報
";
CM_ SG_ 912 MET390_2_0_VEHICLE_SERIES "車型情報
";
CM_ SG_ 912 MET390_2_3_DESTINATION "仕向地情報
";
CM_ SG_ 912 MET390_2_7_PASS_DOOR_RECORD "助手席ﾄﾞｱ開履歴送信
";
CM_ SG_ 912 MET390_1_0_MSG_COUNTER "ﾒｯｾｰｼﾞｶｳﾝﾀ
";
CM_ SG_ 912 MET390_1_4_WAKE_UP_FRAME "ｳｪｲｸｱｯﾌﾟﾌﾚｰﾑ識別ﾌﾗｸﾞ
";
CM_ SG_ 912 MET390_1_5_REQ_COMM_CONT "通信継続要求ﾌﾗｸﾞ
";
CM_ SG_ 912 MET390_1_6_DMS_ID_SET "DMS ID設定完了ﾌﾗｸﾞ
";
CM_ SG_ 912 MET390_1_7_FAIL_EEPROM "EEPROMﾌｪｰﾙ
";
CM_ SG_ 912 MET390_0_0_CHECK_SUM "ﾁｪｯｸｻﾑ
";
CM_ SG_ 1657 TPM679_3_0_STATE_TPMS "TPMS状態ﾌﾗｸﾞ
";
CM_ SG_ 1657 TPM679_3_2_DEFINED_STATE_TPMS "TPMS状態確定
";
CM_ SG_ 1657 TPM679_3_4_MODE_SELECT_TPMS "TPMSカスタマイズMode種別
";
CM_ SG_ 1657 TPM679_2_0_WARN_TPMS "TPMSｳｫｰﾆﾝｸﾞ
";
CM_ SG_ 1657 TPM679_2_3_INTERRUPT "割り込み表示
";
CM_ SG_ 1657 TPM679_2_5_CHECKLUMP_TPMS "TPMSチェックランプ点灯信号
";
CM_ SG_ 1657 TPM679_1_0_MSG_COUNTER "ﾒｯｾｰｼﾞｶｳﾝﾀ
";
CM_ SG_ 1657 TPM679_1_6 "予約:通信継続要求ﾌﾗｸﾞ(拡張)
";
CM_ SG_ 1657 TPM679_0_0_CHECK_SUM "ﾁｪｯｸｻﾑ
";
CM_ SG_ 827 ABG33B_4_0_PASSENGER_BELT_INFO "助手席シートベルト情報
";
CM_ SG_ 827 ABG33B_4_2_PASSENGER_DETECT_INFO "助手席乗員判定情報
";
CM_ SG_ 827 ABG33B_3_0_PPS_STATUS_FAIL_IGN "歩行者保護A/B故障有無状態（点火）
";
CM_ SG_ 827 ABG33B_3_1_PPS_STATUS_FAIL_DEV "歩行者保護A/B故障有無状態（ﾃﾞﾊﾞｲｽ）
";
CM_ SG_ 827 ABG33B_3_2_PPS_STATUS_FAIL_SSR "歩行者保護A/B故障有無状態（ｾﾝｻ）
";
CM_ SG_ 827 ABG33B_3_3_PPS_STATUS_FAIL_ECU "歩行者保護A/B故障有無状態（ECU）
";
CM_ SG_ 827 ABG33B_2_0_IND_WARN_PPA "歩行者ｴｱﾊﾞｯｸﾞｳｫｰﾆﾝｸﾞﾗﾝﾌﾟ点灯・点滅要求
";
CM_ SG_ 827 ABG33B_2_2_DETECT_CRUSH "衝突検知信号(歩行者)
";
CM_ SG_ 827 ABG33B_1_0_MSG_COUNTER "ﾒｯｾｰｼﾞｶｳﾝﾀ
";
CM_ SG_ 827 ABG33B_1_4_FLG_PEDESTRIAN_AIRBAG "歩行者保護A/B有無ﾌﾗｸﾞ
";
CM_ SG_ 827 ABG33B_1_6 "予約:通信継続要求ﾌﾗｸﾞ(拡張)
";
CM_ SG_ 827 ABG33B_0_0_CHECK_SUM "ﾁｪｯｸｻﾑ
";
CM_ SG_ 1621 BIU655_4_0_BUZZER_PATTERN "ﾌﾞｻﾞｰ出力ﾊﾟﾀｰﾝ要求
";
CM_ SG_ 1621 BIU655_3_0_BUZZER_VOL_REQ "室外ﾌﾞｻﾞｰ音量要求
";
CM_ SG_ 1621 BIU655_3_3_RDEF_RELAY_REQ "ﾘｱﾃﾞﾌｫｯｶﾞ出力要求
";
CM_ SG_ 1621 BIU655_3_4_WIPER_DEICER_REQ "ﾜｲﾊﾟﾃﾞｱｲｻ出力要求
";
CM_ SG_ 1621 BIU655_3_5_FT_WIPER_REQ "Fﾜｲﾊﾟ駆動要求
";
CM_ SG_ 1621 BIU655_2_0_RR_WIPER_REQ "Rﾜｲﾊﾟ駆動要求
";
CM_ SG_ 1621 BIU655_2_1_WASHER_REQ "ｳｫｯｼｬ出力要求
";
CM_ SG_ 1621 BIU655_2_3_HL_WASHER_REQ "H/Lｳｫｯｼｬ出力要求
";
CM_ SG_ 1621 BIU655_2_4_FT_FOG_RELAY_REQ "Fﾌｫｸﾞﾗﾝﾌﾟﾘﾚｰ出力要求
";
CM_ SG_ 1621 BIU655_2_5_HEADLAMP_HI_REQ "ﾗｲﾃｨﾝｸﾞHi出力要求
";
CM_ SG_ 1621 BIU655_2_7_HEADLAMP_LO_REQ "ﾗｲﾃｨﾝｸﾞLo出力要求
";
CM_ SG_ 1621 BIU655_1_0_MSG_COUNTER "ﾒｯｾｰｼﾞｶｳﾝﾀ
";
CM_ SG_ 1621 BIU655_0_0_CHECK_SUM "ﾁｪｯｸｻﾑ
";
CM_ SG_ 1618 BIU652_7_0_IND_SECURITY_IMB "ｾｷｭﾘﾃｨ(ｲﾓﾋﾞ)ｲﾝｼﾞｹｰﾀ表示
";
CM_ SG_ 1618 BIU652_6_0_OCCUPATION_3RDRH "3列目右乗員有無信号
";
CM_ SG_ 1618 BIU652_6_1_OCCUPATION_3RDCTR "3列目中央乗員有無信号
";
CM_ SG_ 1618 BIU652_6_2_OCCUPATION_3RDLH "3列目左乗員有無信号
";
CM_ SG_ 1618 BIU652_6_3_OCCUPATION_RRRH "後席右乗員有無信号
";
CM_ SG_ 1618 BIU652_6_4_OCCUPATION_RRCTR "後席中央乗員有無信号
";
CM_ SG_ 1618 BIU652_6_5_OCCUPATION_RRLH "後席左乗員有無信号
";
CM_ SG_ 1618 BIU652_6_6_HORNHAZARD_RES_SIG "ﾘﾓｰﾄﾎｰﾝ&ﾗｲﾄ応答信号
";
CM_ SG_ 1618 BIU652_6_7_OCCUPATION_DRVR "D席乗員有無信号
";
CM_ SG_ 1618 BIU652_5_0_STATUS_ROOMLAMP "ﾙｰﾑﾗﾝﾌﾟ状態
";
CM_ SG_ 1618 BIU652_5_3_HEADLAMP_SMALL "ﾍｯﾄﾞﾗﾝﾌﾟ　ｽﾓｰﾙ
";
CM_ SG_ 1618 BIU652_5_4_ALL_UNLOCK_STATE "全席ｱﾝﾛｯｸ出力状態
";
CM_ SG_ 1618 BIU652_5_5_DRVR_UNLOCK_STATE "運転席ｱﾝﾛｯｸ出力状態
";
CM_ SG_ 1618 BIU652_5_6_ALL_LOCK_STATE "全席ﾛｯｸ出力状態
";
CM_ SG_ 1618 BIU652_4_0_TRIG_LOCK_UNLOCK "ﾄﾞｱﾛｯｸ/ｱﾝﾛｯｸ出力要因信号
";
CM_ SG_ 1618 BIU652_3_0_DOOR_DRVR "ﾄﾞｱSW　D席
";
CM_ SG_ 1618 BIU652_3_1_DOOR_PASS "ﾄﾞｱSW　P席
";
CM_ SG_ 1618 BIU652_3_2_DOOR_RRRH "ﾄﾞｱSW　後席右
";
CM_ SG_ 1618 BIU652_3_3_DOOR_RRLH "ﾄﾞｱSW　後席左
";
CM_ SG_ 1618 BIU652_3_4_DOOR_RG "ﾄﾞｱSW　Rｹﾞｰﾄ
";
CM_ SG_ 1618 BIU652_3_5_DOOR_TR "ﾄﾞｱSW　ﾄﾗﾝｸ
";
CM_ SG_ 1618 BIU652_3_7_OPENSW_RG "ﾘﾔｹﾞｰﾄｵｰﾌﾟﾅSW信号
";
CM_ SG_ 1618 BIU652_2_0_LOCKSTATUS_DRVR "ﾄﾞｱﾛｯｸ状態信号（運席）
";
CM_ SG_ 1618 BIU652_2_1_LOCKSTATUS_PASS "ﾄﾞｱﾛｯｸ状態信号（助手席）
";
CM_ SG_ 1618 BIU652_2_2_LOCKSTATUS_RRRH "ﾄﾞｱﾛｯｸ状態信号（後席右）
";
CM_ SG_ 1618 BIU652_2_3_LOCKSTATUS_RRLH "ﾄﾞｱﾛｯｸ状態信号（後席左）
";
CM_ SG_ 1618 BIU652_2_4_LOCKSTATUS_RG "ﾄﾞｱﾛｯｸ状態信号（Rｹﾞｰﾄ）
";
CM_ SG_ 1618 BIU652_2_6_UNLOCK_DOORKEYSW "ﾄﾞｱｷｰSW　ｱﾝﾛｯｸ
";
CM_ SG_ 1618 BIU652_2_7_LOCK_DOORKEYSW "ﾄﾞｱｷｰSW ﾛｯｸ
";
CM_ SG_ 1618 BIU652_1_0_MSG_COUNTER "ﾒｯｾｰｼﾞｶｳﾝﾀ
";
CM_ SG_ 1618 BIU652_0_0_CHECK_SUM "ﾁｪｯｸｻﾑ
";
CM_ SG_ 942 BIU3AE_5_0_WIPER_FT_VOLUME "ﾄﾞﾗｲﾊﾞAUTO感度設定
";
CM_ SG_ 942 BIU3AE_4_0_DATA_RAINDROP "雨滴情報
";
CM_ SG_ 942 BIU3AE_4_4_FT_WIPER_FAIL "Fﾜｲﾊﾟﾌｪｰﾙ状態
";
CM_ SG_ 942 BIU3AE_4_5_WIPER_FT "FtﾜｲﾊﾟSW状態
";
CM_ SG_ 942 BIU3AE_3_0_WINKER_LEVER_STATUS "ウィンカーレバー状態
";
CM_ SG_ 942 BIU3AE_3_4_WINKER_FACTOR "ｳｨﾝｶｰ出力要因
";
CM_ SG_ 942 BIU3AE_2_0_TURN_LAMP_FAIL_LEFT "メインバルブ異常検知(左)
";
CM_ SG_ 942 BIU3AE_2_1_TURN_LAMP_FAIL_RIGHT "メインバルブ異常検知(右)
";
CM_ SG_ 942 BIU3AE_2_3_HAZARD_SW "ハザードSW状態
";
CM_ SG_ 942 BIU3AE_1_0_MSG_COUNTER "ﾒｯｾｰｼﾞｶｳﾝﾀ
";
CM_ SG_ 942 BIU3AE_0_0_CHECK_SUM "ﾁｪｯｸｻﾑ
";
CM_ SG_ 940 BIU3AC_7_0_HEADLAMP_SMALL "ﾍｯﾄﾞﾗﾝﾌﾟ　ｽﾓｰﾙ
";
CM_ SG_ 940 BIU3AC_7_1_HEADLAMP_LO_REQ "ﾗｲﾃｨﾝｸﾞLo出力要求
";
CM_ SG_ 940 BIU3AC_7_2_HEADLAMP_HI_REQ "ﾗｲﾃｨﾝｸﾞHi出力要求
";
CM_ SG_ 940 BIU3AC_7_3_FT_FOG_RELAY_REQ "Fﾌｫｸﾞﾗﾝﾌﾟﾘﾚｰ出力要求
";
CM_ SG_ 940 BIU3AC_7_4_FOGLAMP_RR "ﾘｱﾌｫｸﾞﾗﾝﾌﾟ
";
CM_ SG_ 940 BIU3AC_7_5_DRL "DRL出力信号
";
CM_ SG_ 940 BIU3AC_7_6_WIPER_FRONT "FTﾜｲﾊﾟ(RTN)
";
CM_ SG_ 940 BIU3AC_7_7_RDEF_RELAY_REQ "ﾘｱﾃﾞﾌｫｯｶﾞ出力要求
";
CM_ SG_ 940 BIU3AC_6_0_RDEFOGSW "ﾘｱﾃﾞﾌｫｯｶﾞSW状態
";
CM_ SG_ 940 BIU3AC_6_1_CSTM_PRG "ﾊﾟﾜｰﾘｱｹﾞｰﾄ有無ﾌﾗｸﾞ
";
CM_ SG_ 940 BIU3AC_6_2_FAIL_SHIFTLOCKSOL "ｼﾌﾄﾛｯｸｿﾚﾉｲﾄﾞ異常
";
CM_ SG_ 940 BIU3AC_6_3_REQ_CANCEL_ISS "ISSｷｬﾝｾﾙ要求
";
CM_ SG_ 940 BIU3AC_6_4_REVERSE_MT "MTﾘﾊﾞｰｽSW
";
CM_ SG_ 940 BIU3AC_6_5_HANDBRAKE "ﾊﾟｰｷﾝｸﾞﾌﾞﾚｰｷSW
";
CM_ SG_ 940 BIU3AC_6_6_BRAKELAMPSW "ﾌﾞﾚｰｷﾗﾝﾌﾟSW
";
CM_ SG_ 940 BIU3AC_6_7_TOWING_SW "ﾄｰｲﾝｸﾞSW
";
CM_ SG_ 940 BIU3AC_5_0_LANE_OFF_SW "LANE OFFｽｲｯﾁ
";
CM_ SG_ 940 BIU3AC_5_2_PCR_OFF_SW "P-CR　OFFｽｲｯﾁ
";
CM_ SG_ 940 BIU3AC_5_4_DIMMER_CANCEL "ﾃﾞｨﾏｰｷｬﾝｾﾙ信号
";
CM_ SG_ 940 BIU3AC_5_5_KEYSW "ｷｰSW
";
CM_ SG_ 940 BIU3AC_5_6_IND_ND_SHIFTLOCK "N-Dｼﾌﾄﾛｯｸ用ﾌﾞﾚｰｷ押下表示有無
";
CM_ SG_ 940 BIU3AC_4_0_DOOR_DRVR "ﾄﾞｱSW　D席
";
CM_ SG_ 940 BIU3AC_4_1_DOOR_PASS "ﾄﾞｱSW　P席
";
CM_ SG_ 940 BIU3AC_4_2_DOOR_RRRH "ﾄﾞｱSW　後席右
";
CM_ SG_ 940 BIU3AC_4_3_DOOR_RRLH "ﾄﾞｱSW　後席左
";
CM_ SG_ 940 BIU3AC_4_4_DOOR_RG "ﾄﾞｱSW　Rｹﾞｰﾄ
";
CM_ SG_ 940 BIU3AC_4_5_DOOR_TR "ﾄﾞｱSW　ﾄﾗﾝｸ
";
CM_ SG_ 940 BIU3AC_4_6_HOOD_CLOSE "ﾌｰﾄﾞSW　閉側
";
CM_ SG_ 940 BIU3AC_4_7_HOOD_OPEN "ﾌｰﾄﾞＳＷ　開側
";
CM_ SG_ 940 BIU3AC_3_0_GW_STSW_RES "RESからのSTSWﾃﾞｰﾀ
";
CM_ SG_ 940 BIU3AC_3_1_GW_POWER_RES "SMTからのﾘﾓｽﾀ電源ONﾃﾞｰﾀ
";
CM_ SG_ 940 BIU3AC_3_3_ST1 "STﾌﾗｸﾞ1
";
CM_ SG_ 940 BIU3AC_3_4_ST2 "STﾌﾗｸﾞ2
";
CM_ SG_ 940 BIU3AC_3_5_ACC "ACC
";
CM_ SG_ 940 BIU3AC_3_6_IGA "IG-a
";
CM_ SG_ 940 BIU3AC_3_7_BAT_BACKUP "B/up
";
CM_ SG_ 940 BIU3AC_2_0_CSTM_AC "A/C　ＣＡＮ接続有無ﾌﾗｸﾞ
";
CM_ SG_ 940 BIU3AC_2_1_IMB_SMT "IM/SMT判別情報
";
CM_ SG_ 940 BIU3AC_2_3_CSTM_WGN_SDN "WGN/SDN判別ﾌﾗｸﾞ
";
CM_ SG_ 940 BIU3AC_2_4_VAL_SEAT_BACK_CTSM "ｼｰﾄ現在設定値
";
CM_ SG_ 940 BIU3AC_2_5_VAL_MIR_AFOLD_CTSM "ﾐﾗｰ電格設定値
";
CM_ SG_ 940 BIU3AC_2_6_VAL_MIR_RTILT_CTSM "R連動ﾐﾗｰ設定値
";
CM_ SG_ 940 BIU3AC_2_7_WIPER_REAR "RRﾜｲﾊﾟ(RTN)
";
CM_ SG_ 940 BIU3AC_1_0_MSG_COUNTER "ﾒｯｾｰｼﾞｶｳﾝﾀ
";
CM_ SG_ 940 BIU3AC_1_4_PADDLESHIFT_DOWN_SW "ﾊﾟﾄﾞﾙｼﾌﾄﾀﾞｳﾝSW
";
CM_ SG_ 940 BIU3AC_1_5_PADDLESHIFT_UP_SW "ﾊﾟﾄﾞﾙｼﾌﾄｱｯﾌﾟSW
";
CM_ SG_ 940 BIU3AC_1_6_MANUALMODE_SW "ﾏﾆｭｱﾙﾓｰﾄﾞSW
";
CM_ SG_ 940 BIU3AC_0_0_CHECK_SUM "ﾁｪｯｸｻﾑ
";
CM_ SG_ 1616 BIU650_7_0_Reserved "ワイパーサービスモードSW操作禁止フラグ
";
CM_ SG_ 1616 BIU650_7_1_Reserved "ワイパーサービスモード有無フラグ
";
CM_ SG_ 1616 BIU650_7_2_Reserved "ワイパーサービスモード状態
";
CM_ SG_ 1616 BIU650_7_3_DOOR_LINK_SW_STS "室内灯DOOR連動SW状態
";
CM_ SG_ 1616 BIU650_7_4_Reserved "ウィンドウロックSW信号
";
CM_ SG_ 1616 BIU650_6_0_Reserved "オートライト感度調整設定値
";
CM_ SG_ 1616 BIU650_6_3_RR_WIPER_STATUS "Ｒワイパ駆動状態
";
CM_ SG_ 1616 BIU650_6_5_WIPER_SENSITIVITY_CTM "ワイパ感度設定
";
CM_ SG_ 1616 BIU650_5_0_Reserved "ﾄﾞｱSW運転席信号
";
CM_ SG_ 1616 BIU650_5_1_Reserved "全ﾄﾞｱ開閉変化ｲﾍﾞﾝﾄ判定
";
CM_ SG_ 1616 BIU650_5_2_FMH_DOOR_LOCK "フォローミーホームドアロック判定
";
CM_ SG_ 1616 BIU650_5_4_LMH_DOOR_LOCK "リードミーホームドアロック判定
";
CM_ SG_ 1616 BIU650_4_0_REQ_OPE_AUTOLIGHT "オートライト点灯/消灯要求
";
CM_ SG_ 1616 BIU650_4_2_STATE_SHINSSR "ライトセンサステータス
";
CM_ SG_ 1616 BIU650_4_4_STATE_RLS_FAIL "RLS異常状態
";
CM_ SG_ 1616 BIU650_3_0_REQ_FWASHER_ITLOCK "F ウォッシャ連動要求
";
CM_ SG_ 1616 BIU650_3_1_FWIPER_RTN "F ワイパ（RTN)補正
";
CM_ SG_ 1616 BIU650_3_2_TURN_LAMP_STATE_LEFT "左ターンランプ状態
";
CM_ SG_ 1616 BIU650_3_3_TURN_LAMP_STATE_RIGHT "右ターンランプ状態
";
CM_ SG_ 1616 BIU650_3_4_Reserved "RES操作ﾗｲﾃｨﾝｸﾞ1出力要求
";
CM_ SG_ 1616 BIU650_2_0_HEADLAMP_SMALL_SW "ライティング1SW信号
";
CM_ SG_ 1616 BIU650_2_1_HEADLAMP_LO_SW "ライティング2SW信号
";
CM_ SG_ 1616 BIU650_2_2_HEADLAMP_OFF_SW "ライティングOFF SW信号
";
CM_ SG_ 1616 BIU650_2_3_HEADLAMP_Hi_SW "ディマーHi SW 信号
";
CM_ SG_ 1616 BIU650_2_4_HEAD_LAMP_PASS_SW "ディマーPass SW 信号
";
CM_ SG_ 1616 BIU650_2_5_FFOG_SW "FフォグランプSW信号
";
CM_ SG_ 1616 BIU650_2_6_RFOG_SW "RフォグランプSW信号
";
CM_ SG_ 1616 BIU650_1_0_MSG_COUNTER "メッセージカウンタ
";
CM_ SG_ 1616 BIU650_0_0_CHECK_SUM "チェックサム
";
CM_ SG_ 809 BST329_2_0_WARN_BRAKE_RED "電動ﾌﾞｰｽﾀﾜｰﾆﾝｸﾞﾗﾝﾌﾟ信号（赤）
";
CM_ SG_ 809 BST329_1_0_MSG_COUNTER "メッセージカウンタ
";
CM_ SG_ 809 BST329_1_4_EB_HMI_WARNINGON "電動ﾌﾞｰｽﾀﾜｰﾆﾝｸﾞﾗﾝﾌﾟ信号
";
CM_ SG_ 809 BST329_1_5_WARN_BST_MET_LCD "メータ内液晶用BSTウォーニング
";
CM_ SG_ 809 BST329_1_6_WARN_BST_RED "ﾜｰﾆﾝｸﾞﾗﾝﾌﾟ信号（赤）
";
CM_ SG_ 809 BST329_0_0_CHECK_SUM "チェックサム
";
CM_ SG_ 811 EPB32B_7_0_AVH_TARGET_PRESS "AVH目標保持圧
";
CM_ SG_ 811 EPB32B_6_0_VEHICLE_RUN_STOP_FLG "車両走行停止判定ﾌﾗｸﾞ
";
CM_ SG_ 811 EPB32B_6_2_REQ_HILL_P_CAUTION "坂道駐車警告表示要求
";
CM_ SG_ 811 EPB32B_5_0_FLG_AVH_OILPRES_EPB "AVH制御ﾌﾗｸﾞ(液圧/EPB)
";
CM_ SG_ 811 EPB32B_5_1_FLG_AVH "AVH作動ﾌﾗｸﾞ
";
CM_ SG_ 811 EPB32B_5_2_AVH_INTENSIFY_PRES "ISS中AVH中増圧ﾌﾗｸﾞ
";
CM_ SG_ 811 EPB32B_5_3_BREAK_IND "ﾌﾞﾚｰｷ踏み指示
";
CM_ SG_ 811 EPB32B_5_5_AVH_ON_LAMP "AVH_ON灯
";
CM_ SG_ 811 EPB32B_5_6_AVH_FUNC_ON_LUMP "AVH 作動灯
";
CM_ SG_ 811 EPB32B_5_7_AVH_ACTIVE "AVH有無ﾌﾗｸﾞ
";
CM_ SG_ 811 EPB32B_4_0_BUZZER "ﾌﾞｻﾞｰ
";
CM_ SG_ 811 EPB32B_4_2_HILL_HOLD_ON_LAMP "ﾋﾙﾎｰﾙﾄﾞ機能ONﾗﾝﾌﾟ
";
CM_ SG_ 811 EPB32B_4_3_CLAMP_LAMP "EPB作動灯
";
CM_ SG_ 811 EPB32B_4_5_WARN_LAMP "EPB警告灯
";
CM_ SG_ 811 EPB32B_4_7_WARN_EPB_MET_LCD "ﾒｰﾀ内液晶用EPB警告灯
";
CM_ SG_ 811 EPB32B_3_0_STATUS_EPB "EPB作動状態
";
CM_ SG_ 811 EPB32B_3_3_DYNAMIC_PARKING "動的ﾊﾟｰｷﾝｸﾞﾌﾗｸﾞ
";
CM_ SG_ 811 EPB32B_3_4_HILL_HOLD_RUN_FLG "ﾋﾙﾎｰﾙﾄﾞ作動ﾌﾗｸﾞ
";
CM_ SG_ 811 EPB32B_3_5_INHIBIT_ISS_DELAY "ISS作動禁止要求ﾌﾗｸﾞ(判定ﾃﾞｨﾚｲ有り)
";
CM_ SG_ 811 EPB32B_3_6_INHIBIT_ISS "ISS作動禁止要求ﾌﾗｸﾞ(判定ﾃﾞｨﾚｲ無し)
";
CM_ SG_ 811 EPB32B_3_7_AVH_PERMIT_CONT_ACC "AVH-ACC協調許可フラグ
";
CM_ SG_ 811 EPB32B_2_0_ERR_INFO "EPBｴﾗｰ情報
";
CM_ SG_ 811 EPB32B_2_2_EPB_FAIL_FLG1 "EPBﾌｪｰﾙﾌﾗｸﾞ1
";
CM_ SG_ 811 EPB32B_2_3_EPB_FAIL_FLG2 "EPBﾌｪｰﾙﾌﾗｸﾞ2
";
CM_ SG_ 811 EPB32B_2_4_EPB_FAIL_FLG3 "EPBﾌｪｰﾙﾌﾗｸﾞ3
";
CM_ SG_ 811 EPB32B_1_0_MSG_COUNTER "ﾒｯｾｰｼﾞｶｳﾝﾀ
";
CM_ SG_ 811 EPB32B_1_4_WAKE_UP_FRAME "ｳｪｲｸｱｯﾌﾟﾌﾚｰﾑ識別ﾌﾗｸﾞ
";
CM_ SG_ 811 EPB32B_1_5_REQ_COMM_CONT "通信継続要求ﾌﾗｸﾞ
";
CM_ SG_ 811 EPB32B_1_6 "予約:通信継続要求ﾌﾗｸﾞ(拡張)
";
CM_ SG_ 811 EPB32B_0_0_CHECK_SUM "ﾁｪｯｸｻﾑ
";
CM_ SG_ 362 VDC16A_6_0_ACCELERATE_F_R_R160 "前後Gｾﾝｻ値(UN-R160-01用)
";
CM_ SG_ 362 VDC16A_4_0_YAW_RATE_HI_RES "ヨーレート(高分解能)
";
CM_ SG_ 362 VDC16A_3_7_JUDGE_EXTRUSION "押し出し判定ﾌﾗｸﾞ
";
CM_ SG_ 362 VDC16A_2_0_ACCELERATE_L_R_HI_RES "横加速度(高分解能)
";
CM_ SG_ 362 VDC16A_1_0_MSG_COUNTER "メッセージカウンタ
";
CM_ SG_ 362 VDC16A_0_0_CHECK_SUM "チェックサム
";
CM_ SG_ 808 VDC328_7_1_IND_WARN_CBC "CBC 警告灯
";
CM_ SG_ 808 VDC328_7_2_ACTIVATE_CBC "CBC 作動灯
";
CM_ SG_ 808 VDC328_7_3_FLAG_ACT_CBC "CBC 作動フラグ
";
CM_ SG_ 808 VDC328_6_0_PROHIBIT_VDC_OFF_CCU "CCU協調VDC OFF制御禁止状態
";
CM_ SG_ 808 VDC328_6_1_PROHIBIT_AVH_CCU "CCU協調AVH制御禁止状態
";
CM_ SG_ 808 VDC328_5_0_VDC_BUZZER "VDCブザー
";
CM_ SG_ 808 VDC328_5_2_WARN_BRAKE_BOOST "ﾌﾞﾚｰｷ倍力機能ｳｫｰﾆﾝｸﾞ
";
CM_ SG_ 808 VDC328_5_4_WARN_RBS "RBS 警告灯
";
CM_ SG_ 808 VDC328_5_6_IND_HSA_ON "HSA ON灯
";
CM_ SG_ 808 VDC328_5_7_IND_TCS_OFF "TCS OFFﾗﾝﾌﾟ
";
CM_ SG_ 808 VDC328_4_0_IND_VDC_OFF "VDC OFFﾗﾝﾌﾟ
";
CM_ SG_ 808 VDC328_4_1_STATE_ACTIVATE_VDC "VDC/TCS作動状態信号
";
CM_ SG_ 808 VDC328_4_2_IND_HSA_OFF "HSA OFF灯
";
CM_ SG_ 808 VDC328_4_3_IND_HDC "HDCﾗﾝﾌﾟ
";
CM_ SG_ 808 VDC328_4_5_WARNING_BRAKE_SYS "ブレーキシステムウォーニング
";
CM_ SG_ 808 VDC328_4_7_ACTIVE_OHB "OHB作動ﾌﾗｸﾞ
";
CM_ SG_ 808 VDC328_3_0_IND_WARN_EBD "EBDｳｫｰﾆﾝｸﾞ
";
CM_ SG_ 808 VDC328_3_1_IND_WARN_ABS "ABSｳｫｰﾆﾝｸﾞ
";
CM_ SG_ 808 VDC328_3_2_IND_WARN_VDC "VDCｳｫｰﾆﾝｸﾞ
";
CM_ SG_ 808 VDC328_3_3_IND_WARN_HSA "HSA警告灯(HSAｳｫｰﾆﾝｸﾞ)
";
CM_ SG_ 808 VDC328_3_4_WARN_BRAKEFLUID_LV "ﾌﾞﾚｰｷﾌﾙｰﾄﾞﾚﾍﾞﾙ警告灯
";
CM_ SG_ 808 VDC328_3_6_IND_TCS_OFF "TCS OFFランプ
";
CM_ SG_ 808 VDC328_3_7_EXIST_EPB "EPB設定情報
";
CM_ SG_ 808 VDC328_2_0_WARN_EBD_MET_LCD "ﾒｰﾀ内液晶用EBDｳｫｰﾆﾝｸﾞ
";
CM_ SG_ 808 VDC328_2_1_WARN_ABS_MET_LCD "ﾒｰﾀ内液晶用ABSｳｫｰﾆﾝｸﾞ
";
CM_ SG_ 808 VDC328_2_2_WARN_VDC_MET_LCD "ﾒｰﾀ内液晶用VDCｳｫｰﾆﾝｸﾞ
";
CM_ SG_ 808 VDC328_2_3_WARN_HSA_MET_LCD "ﾒｰﾀ内液晶用HSA警告灯(HSAｳｫｰﾆﾝｸﾞ)
";
CM_ SG_ 808 VDC328_2_4_EXIST_VECTARING "ﾍﾞｸﾀﾘﾝｸﾞ機能設定情報
";
CM_ SG_ 808 VDC328_1_0_MSG_COUNTER "ﾒｯｾｰｼﾞｶｳﾝﾀ
";
CM_ SG_ 808 VDC328_0_0_CHECK_SUM "ﾁｪｯｸｻﾑ
";
CM_ SG_ 315 VDC13B_7_0_ACCELERATE_F_R "前後Gｾﾝｻ値
";
CM_ SG_ 315 VDC13B_6_0_ACCELERATE_L_R "横加速度
";
CM_ SG_ 315 VDC13B_4_0_ENG_TRQ_DOWN "ｴﾝｼﾞﾝﾄﾙｸ減少要求値
";
CM_ SG_ 315 VDC13B_2_0_ENG_TRQ_UP "ｴﾝｼﾞﾝﾄﾙｸｱｯﾌﾟ要求値
";
CM_ SG_ 315 VDC13B_1_0_MSG_COUNTER "ﾒｯｾｰｼﾞｶｳﾝﾀ
";
CM_ SG_ 315 VDC13B_1_4_BRAKE_TYPE "ﾌﾞﾚｰｷｼｽﾃﾑﾌﾗｸﾞ
";
CM_ SG_ 315 VDC13B_1_5_REQ_ENG_TRQ_DOWN "ｴﾝｼﾞﾝﾄﾙｸ減少要求ﾌﾗｸﾞ
";
CM_ SG_ 315 VDC13B_1_6_REQ_ENG_TRQ_UP "ｴﾝｼﾞﾝﾄﾙｸｱｯﾌﾟ要求ﾌﾗｸﾞ
";
CM_ SG_ 315 VDC13B_1_7_PROHIBIT_FUEL_CUT "ﾌｭｰｴﾙｶｯﾄ禁止ﾌﾗｸﾞ
";
CM_ SG_ 315 VDC13B_0_0_CHECK_SUM "ﾁｪｯｸｻﾑ
";
CM_ SG_ 314 VDC13A_6_3_SPD_WHEEL_RRRH "右後輪車輪速
";
CM_ SG_ 314 VDC13A_4_6_SPD_WHEEL_RRLH "左後輪車輪速
";
CM_ SG_ 314 VDC13A_3_1_SPD_WHEEL_FTRH "右前輪車輪速
";
CM_ SG_ 314 VDC13A_1_4_SPD_WHEEL_FTLH "左前輪車輪速
";
CM_ SG_ 314 VDC13A_1_0_MSG_COUNTER "ﾒｯｾｰｼﾞｶｳﾝﾀ
";
CM_ SG_ 314 VDC13A_0_0_CHECK_SUM "ﾁｪｯｸｻﾑ
";
CM_ SG_ 313 VDC139_7_4_FAIL_PRESSURE_SSR "圧力ｾﾝｻ故障ﾌﾗｸﾞ
";
CM_ SG_ 313 VDC139_7_5_STATUS_EPB "EPB作動状態
";
CM_ SG_ 313 VDC139_6_0_SSR_N_PRESS "負圧ｾﾝｻ値
";
CM_ SG_ 313 VDC139_5_0_PRESSURE_BRAKE "ﾌﾞﾚｰｷ圧力
";
CM_ SG_ 313 VDC139_4_0_HDC_STATUS "HDC状態信号
";
CM_ SG_ 313 VDC139_4_2_BRAKELAMPSW "BLS信号
";
CM_ SG_ 313 VDC139_4_3_FAIL_BRAKELAMPSW "BLS故障信号
";
CM_ SG_ 313 VDC139_4_4_ACTIVATE_ABS "ABS作動ﾌﾗｸﾞ
";
CM_ SG_ 313 VDC139_4_5_ACTIVATE_TCS "TCS作動ﾌﾗｸﾞ
";
CM_ SG_ 313 VDC139_4_6_CONT_OVER_STR "VDCｵｰﾊﾞｰ制御ﾌﾗｸﾞ
";
CM_ SG_ 313 VDC139_4_7_CONT_UNDER_STR "VDCｱﾝﾀﾞｰ制御ﾌﾗｸﾞ
";
CM_ SG_ 313 VDC139_3_5_FAIL_VDC_SSR "VDCｾﾝｻﾌｪｰﾙﾌﾗｸﾞ
";
CM_ SG_ 313 VDC139_3_6_FAIL_SPD_SSR_FHI "ｽﾋﾟｰﾄﾞｾﾝｻﾌｪｰﾙﾌﾗｸﾞ（FHI）
";
CM_ SG_ 313 VDC139_3_7_FAIL_ABS_SYS "ABSｼｽﾃﾑﾌｪｰﾙﾌﾗｸﾞ
";
CM_ SG_ 313 VDC139_2_0_SPD_WHEEL_AVE "駆動輪軸平均車輪速（VSO）
";
CM_ SG_ 313 VDC139_1_0_MSG_COUNTER "ﾒｯｾｰｼﾞｶｳﾝﾀ
";
CM_ SG_ 313 VDC139_1_4_FAIL_HDC_SYS "HDCｼｽﾃﾑﾌｪｰﾙﾌﾗｸﾞ
";
CM_ SG_ 313 VDC139_1_5_VEHICLE_HIGHT "車高情報
";
CM_ SG_ 313 VDC139_1_7_REPROGRAMING "CAN診断・送信停止
";
CM_ SG_ 313 VDC139_0_0_CHECK_SUM "ﾁｪｯｸｻﾑ
";
CM_ SG_ 312 VDC138_7_0_PRESSURE_WC_FTLH "FL W/C実液圧
";
CM_ SG_ 312 VDC138_6_0_PRESSURE_WC_FTRH "FR W/C実液圧
";
CM_ SG_ 312 VDC138_4_0_YAW_RATE "ﾖｰﾚｰﾄ
";
CM_ SG_ 312 VDC138_2_0_STEER_ANGLE "舵角ｾﾝｻ
";
CM_ SG_ 312 VDC138_1_0_MSG_COUNTER "ﾒｯｾｰｼﾞｶｳﾝﾀ
";
CM_ SG_ 312 VDC138_1_4_ACTIVE_LDP "LDP作動ﾌﾗｸﾞ
";
CM_ SG_ 312 VDC138_1_5_PROHIBIT_LDP "LDP禁止ﾌﾗｸﾞ
";
CM_ SG_ 312 VDC138_1_6_VDC_SMALL_MARGIN "VDC介入余裕小ﾌﾗｸﾞ
";
CM_ SG_ 312 VDC138_1_7_DETECT_REAR_SLIP "ﾘｱｽﾘｯﾌﾟ検出ﾌﾗｸﾞ
";
CM_ SG_ 312 VDC138_0_0_CHECK_SUM "ﾁｪｯｸｻﾑ
";
CM_ SG_ 1143 CCU477_28_4_Reserved "RESERVED
";
CM_ SG_ 1143 CCU477_28_2_TIM_CHG_CHG_FLG "タイマー充電設定変更フラグ
";
CM_ SG_ 1143 CCU477_28_0_TIM_CHG_ICON_DISP "タイマー充電アイコン表示要求
";
CM_ SG_ 1143 CCU477_27_4_TIM_CHG_STATUS "タイマー充電ステータス
";
CM_ SG_ 1143 CCU477_27_1_DEP_TIM_PRE_CON_FLAG "プレコンディションニングフラグ
";
CM_ SG_ 1143 CCU477_27_0_TIM_CHG_PERM_FLAG "タイマー充電許可禁止
";
CM_ SG_ 1143 CCU477_26_0_TIM4_CHG_WEEK_DAYS "タイマー充電ID4曜日
";
CM_ SG_ 1143 CCU477_25_3_Reserved "RESERVED
";
CM_ SG_ 1143 CCU477_24_0_TIM4_CHG_END_TIME "タイマー充電ID4終了時刻
";
CM_ SG_ 1143 CCU477_23_5_Reserved "RESERVED
";
CM_ SG_ 1143 CCU477_22_2_TIM4_CHG_START_TIME "タイマー充電ID4開始時刻
";
CM_ SG_ 1143 CCU477_22_0_TIM4_CHG_SET_TYPE "タイマー充電ID4タイプ
";
CM_ SG_ 1143 CCU477_21_7_Reserved "RESERVED
";
CM_ SG_ 1143 CCU477_21_5_TIM4_CHG_SW_STS "タイマー充電ID4オン・オフ状態
";
CM_ SG_ 1143 CCU477_21_0_TIM4_DISP_ID "タイマー充電ID4の表示順番ID
";
CM_ SG_ 1143 CCU477_20_0_TIM3_CHG_WEEK_DAYS "タイマー充電ID3曜日
";
CM_ SG_ 1143 CCU477_19_3_Reserved "RESERVED
";
CM_ SG_ 1143 CCU477_18_0_TIM3_CHG_END_TIME "タイマー充電ID3終了時刻
";
CM_ SG_ 1143 CCU477_17_5_Reserved "RESERVED
";
CM_ SG_ 1143 CCU477_16_2_TIM3_CHG_START_TIME "タイマー充電ID3開始時刻
";
CM_ SG_ 1143 CCU477_16_0_TIM3_CHG_SET_TYPE "タイマー充電ID3タイプ
";
CM_ SG_ 1143 CCU477_15_7_Reserved "RESERVED
";
CM_ SG_ 1143 CCU477_15_5_TIM3_CHG_SW_STS "タイマー充電ID3オン・オフ状態
";
CM_ SG_ 1143 CCU477_15_0_TIM3_DISP_ID "タイマー充電ID3の表示順番ID
";
CM_ SG_ 1143 CCU477_14_0_TIM2_CHG_WEEK_DAYS "タイマー充電ID2曜日
";
CM_ SG_ 1143 CCU477_13_3_Reserved "RESERVED
";
CM_ SG_ 1143 CCU477_12_0_TIM2_CHG_END_TIME "タイマー充電ID2終了時刻
";
CM_ SG_ 1143 CCU477_11_5_Reserved "RESERVED
";
CM_ SG_ 1143 CCU477_10_2_TIM2_CHG_START_TIME "タイマー充電ID2開始時刻
";
CM_ SG_ 1143 CCU477_10_0_TIM2_CHG_SET_TYPE "タイマー充電ID2タイプ
";
CM_ SG_ 1143 CCU477_9_7_Reserved "RESERVED
";
CM_ SG_ 1143 CCU477_9_5_TIM2_CHG_SW_STS "タイマー充電ID2オン・オフ状態
";
CM_ SG_ 1143 CCU477_9_0_TIM2_DISP_ID "タイマー充電ID2の表示順番ID
";
CM_ SG_ 1143 CCU477_8_0_TIM1_CHG_WEEK_DAYS "タイマー充電ID1曜日
";
CM_ SG_ 1143 CCU477_7_3_Reserved "RESERVED
";
CM_ SG_ 1143 CCU477_6_0_TIM1_CHG_END_TIME "タイマー充電ID1終了時刻
";
CM_ SG_ 1143 CCU477_5_5_Reserved "RESERVED
";
CM_ SG_ 1143 CCU477_4_2_TIM1_CHG_START_TIME "タイマー充電ID1開始時刻
";
CM_ SG_ 1143 CCU477_4_0_TIM1_CHG_SET_TYPE "タイマー充電ID1タイプ
";
CM_ SG_ 1143 CCU477_3_7_Reserved "RESERVED
";
CM_ SG_ 1143 CCU477_3_5_TIM1_CHG_SW_STS "タイマー充電ID1オン・オフ状態
";
CM_ SG_ 1143 CCU477_3_0_TIM1_DISP_ID "タイマー充電ID1の表示順番ID
";
CM_ SG_ 1143 CCU477_2_0_E2E_COUNTER "E2Eカウンタ
";
CM_ SG_ 1143 CCU477_0_0_E2E_CRC "CRC
";
CM_ SG_ 1142 CCU476_17_2_SW_STOP_CHG "充電停止要求
";
CM_ SG_ 1142 CCU476_17_1_SW_NORMAL_MOD_CHG "ノーマルモード要求
";
CM_ SG_ 1142 CCU476_17_0_SW_PWR_MOD_CHG "パワーモード要求
";
CM_ SG_ 1142 CCU476_16_4_AC_CUR_MAX_LIM_CHG "AC充電電流上限設定値(IVI)
";
CM_ SG_ 1142 CCU476_16_0_DC_PWR_MAX_LIM_CHG "DC充電電力上限設定値(IVI)
";
CM_ SG_ 1142 CCU476_15_0_SOC_MAX_LIM_CHG "充電量上限設定要求値
";
CM_ SG_ 1142 CCU476_14_0_HIS_ID_PNC "履歴ID
";
CM_ SG_ 1142 CCU476_13_5_SW_CAUTION_PNC "PnCcaution_push
";
CM_ SG_ 1142 CCU476_13_4_SW_NEW_PNC "New_push
";
CM_ SG_ 1142 CCU476_13_3_START_CTR_PNC "PnC_契約開始
";
CM_ SG_ 1142 CCU476_13_1_STS_PNC "PnC_Status
";
CM_ SG_ 1142 CCU476_13_0_DESC_PNC "PnC説明
";
CM_ SG_ 1142 CCU476_11_1_STOP_TIM_TIM_CHG "充電終了設定時刻
";
CM_ SG_ 1142 CCU476_10_0_START_TIM_TIM_CHG "充電開始設定時刻
";
CM_ SG_ 1142 CCU476_9_0_WKD_SET_TIM_CHG "充電設定曜日
";
CM_ SG_ 1142 CCU476_8_0_LOGIN_REQ_TIM_CHG "タイマー設定登録要求
";
CM_ SG_ 1142 CCU476_7_0_WKD_SEL_TIM_CHG "曜日選択
";
CM_ SG_ 1142 CCU476_5_1_STOP_TIM_CH_TIM_CHG "終了設定時刻変更
";
CM_ SG_ 1142 CCU476_4_0_START_TIM_CH_TIM_CHG "開始設定時刻変更
";
CM_ SG_ 1142 CCU476_3_0_PNC_SW_REQ_CCU "PnCサービスOnOff切替要求_CCU
";
CM_ SG_ 1142 CCU476_2_7_SW_TIM_CHG "オン/オフ状態
";
CM_ SG_ 1142 CCU476_2_0_E2E_COUNTER "E2Eカウンタ
";
CM_ SG_ 1142 CCU476_0_0_E2E_CRC "CRC
";
CM_ SG_ 1112 CCU458_7_0_BYTE5 "開発用変数5
";
CM_ SG_ 1112 CCU458_6_0_BYTE4 "開発用変数4
";
CM_ SG_ 1112 CCU458_5_0_BYTE3 "開発用変数3
";
CM_ SG_ 1112 CCU458_4_0_BYTE2 "開発用変数2
";
CM_ SG_ 1112 CCU458_3_0_BYTE1 "開発用変数1
";
CM_ SG_ 1112 CCU458_2_0_E2E_COUNTER "E2Eカウンタ
";
CM_ SG_ 1112 CCU458_0_0_E2E_CRC "CRC
";
BA_DEF_  "DBCConverterVersion" STRING ;
BA_DEF_  "Manufacturer" STRING ;
BA_DEF_  "BusType" STRING ;
BA_DEF_ BU_  "DiagNode" ENUM  "No","Yes";
BA_DEF_ BU_  "ILUsed" ENUM  "No","Yes";
BA_DEF_ BU_  "NodeLayerModules" STRING ;
BA_DEF_ SG_  "Fhi_SignalComment" STRING ;
BA_DEF_ SG_  "GenSigInactiveValue" INT 0 10000;
BA_DEF_ SG_  "GenSigStartValue" FLOAT 0 100000000000;
BA_DEF_ SG_  "GenSigSendType" ENUM  "Cyclic","OnWrite","OnWriteWithRepetition","OnChange","OnChangeWithRepetition","IfActive","IfActiveWithRepetition","NoSigSendType";
BA_DEF_ BO_  "MsgRoutingId" STRING ;
BA_DEF_ BO_  "DiagResponse" ENUM  "No","Yes";
BA_DEF_ BO_  "DiagRequest" ENUM  "No","Yes";
BA_DEF_ BO_  "DiagState" ENUM  "No","Yes";
BA_DEF_ BO_  "GenMsgILSupport" ENUM  "No","Yes";
BA_DEF_ BO_  "GenMsgNrOfRepetition" INT 0 999999;
BA_DEF_ BO_  "GenMsgDelayTime" INT 0 1000;
BA_DEF_ BO_  "GenMsgCycleTimeFast" INT 0 10000;
BA_DEF_ BO_  "GenMsgCycleTime" INT 0 10000;
BA_DEF_ BO_  "GenMsgSendType" ENUM  "Cyclic","NotUsed","NotUsed","NotUsed","NotUsed","Cyclic","NotUsed","IfActive","NoMsgSendType";
BA_DEF_ BO_  "CANFD_BRS" ENUM  "0","1";
BA_DEF_ BO_  "VFrameFormat" ENUM  "StandardCAN","ExtendedCAN","reserved","reserved","reserved","reserved","reserved","reserved","reserved","reserved","reserved","reserved","reserved","reserved","StandardCAN_FD","ExtendedCAN_FD";
BA_DEF_DEF_  "DBCConverterVersion" "2.0";
BA_DEF_DEF_  "Manufacturer" "FHI";
BA_DEF_DEF_  "BusType" "";
BA_DEF_DEF_  "DiagNode" "No";
BA_DEF_DEF_  "ILUsed" "Yes";
BA_DEF_DEF_  "NodeLayerModules" "CANoeILNLSubaru.dll";
BA_DEF_DEF_  "Fhi_SignalComment" "";
BA_DEF_DEF_  "GenSigInactiveValue" 0;
BA_DEF_DEF_  "GenSigStartValue" 0;
BA_DEF_DEF_  "GenSigSendType" "NoSigSendType";
BA_DEF_DEF_  "MsgRoutingId" "";
BA_DEF_DEF_  "DiagResponse" "No";
BA_DEF_DEF_  "DiagRequest" "No";
BA_DEF_DEF_  "DiagState" "No";
BA_DEF_DEF_  "GenMsgILSupport" "Yes";
BA_DEF_DEF_  "GenMsgNrOfRepetition" 0;
BA_DEF_DEF_  "GenMsgDelayTime" 0;
BA_DEF_DEF_  "GenMsgCycleTimeFast" 0;
BA_DEF_DEF_  "GenMsgCycleTime" 0;
BA_DEF_DEF_  "GenMsgSendType" "Cyclic";
BA_DEF_DEF_  "CANFD_BRS" "1";
BA_DEF_DEF_  "VFrameFormat" "StandardCAN";
BA_ "BusType" "CAN FD";
BA_ "DiagNode" BU_ EVCC 1;
BA_ "DiagNode" BU_ C_ECU 1;
BA_ "DiagNode" BU_ C_ECU_GW 1;
BA_ "GenMsgILSupport" BO_ 803 0;
BA_ "MsgRoutingId" BO_ 803 "269 ";
BA_ "GenMsgNrOfRepetition" BO_ 803 2;
BA_ "GenMsgCycleTimeFast" BO_ 803 50;
BA_ "GenMsgDelayTime" BO_ 803 50;
BA_ "GenMsgCycleTime" BO_ 803 100;
BA_ "VFrameFormat" BO_ 803 14;
BA_ "VFrameFormat" BO_ 2564481222 1;
BA_ "MsgRoutingId" BO_ 2564481222 "251 ";
BA_ "GenMsgILSupport" BO_ 2564481222 0;
BA_ "DiagResponse" BO_ 2564481222 1;
BA_ "GenMsgNrOfRepetition" BO_ 2564481222 1;
BA_ "GenMsgSendType" BO_ 2564481222 8;
BA_ "VFrameFormat" BO_ 2564474592 1;
BA_ "MsgRoutingId" BO_ 2564474592 "250 ";
BA_ "GenMsgILSupport" BO_ 2564474592 0;
BA_ "DiagRequest" BO_ 2564474592 1;
BA_ "GenMsgNrOfRepetition" BO_ 2564474592 1;
BA_ "GenMsgSendType" BO_ 2564474592 8;
BA_ "VFrameFormat" BO_ 2564481219 1;
BA_ "MsgRoutingId" BO_ 2564481219 "249 ";
BA_ "GenMsgILSupport" BO_ 2564481219 0;
BA_ "DiagResponse" BO_ 2564481219 1;
BA_ "GenMsgNrOfRepetition" BO_ 2564481219 1;
BA_ "GenMsgSendType" BO_ 2564481219 8;
BA_ "VFrameFormat" BO_ 2564473824 1;
BA_ "MsgRoutingId" BO_ 2564473824 "248 ";
BA_ "GenMsgILSupport" BO_ 2564473824 0;
BA_ "DiagRequest" BO_ 2564473824 1;
BA_ "GenMsgNrOfRepetition" BO_ 2564473824 1;
BA_ "GenMsgSendType" BO_ 2564473824 8;
BA_ "GenMsgILSupport" BO_ 2564481478 0;
BA_ "DiagResponse" BO_ 2564481478 1;
BA_ "GenMsgNrOfRepetition" BO_ 2564481478 1;
BA_ "GenMsgSendType" BO_ 2564481478 8;
BA_ "VFrameFormat" BO_ 2564481478 15;
BA_ "GenMsgILSupport" BO_ 2564474593 0;
BA_ "DiagRequest" BO_ 2564474593 1;
BA_ "GenMsgNrOfRepetition" BO_ 2564474593 1;
BA_ "GenMsgSendType" BO_ 2564474593 8;
BA_ "VFrameFormat" BO_ 2564474593 15;
BA_ "GenMsgILSupport" BO_ 2564481475 0;
BA_ "DiagResponse" BO_ 2564481475 1;
BA_ "GenMsgNrOfRepetition" BO_ 2564481475 1;
BA_ "GenMsgSendType" BO_ 2564481475 8;
BA_ "VFrameFormat" BO_ 2564481475 15;
BA_ "GenMsgILSupport" BO_ 2564473825 0;
BA_ "DiagRequest" BO_ 2564473825 1;
BA_ "GenMsgNrOfRepetition" BO_ 2564473825 1;
BA_ "GenMsgSendType" BO_ 2564473825 8;
BA_ "VFrameFormat" BO_ 2564473825 15;
BA_ "MsgRoutingId" BO_ 1100 "247 ";
BA_ "GenMsgCycleTime" BO_ 1100 100;
BA_ "VFrameFormat" BO_ 1100 14;
BA_ "MsgRoutingId" BO_ 1099 "246 ";
BA_ "GenMsgCycleTime" BO_ 1099 100;
BA_ "VFrameFormat" BO_ 1099 14;
BA_ "MsgRoutingId" BO_ 1098 "245 ";
BA_ "GenMsgNrOfRepetition" BO_ 1098 3;
BA_ "GenMsgCycleTimeFast" BO_ 1098 100;
BA_ "GenMsgSendType" BO_ 1098 8;
BA_ "VFrameFormat" BO_ 1098 14;
BA_ "MsgRoutingId" BO_ 1097 "244 ";
BA_ "GenMsgCycleTime" BO_ 1097 100;
BA_ "VFrameFormat" BO_ 1097 14;
BA_ "MsgRoutingId" BO_ 1096 "243 ";
BA_ "GenMsgCycleTime" BO_ 1096 100;
BA_ "VFrameFormat" BO_ 1096 14;
BA_ "MsgRoutingId" BO_ 1095 "242 ";
BA_ "GenMsgNrOfRepetition" BO_ 1095 1;
BA_ "GenMsgDelayTime" BO_ 1095 10;
BA_ "GenMsgCycleTime" BO_ 1095 100;
BA_ "VFrameFormat" BO_ 1095 14;
BA_ "MsgRoutingId" BO_ 1094 "241 ";
BA_ "GenMsgCycleTime" BO_ 1094 100;
BA_ "VFrameFormat" BO_ 1094 14;
BA_ "MsgRoutingId" BO_ 1093 "240 ";
BA_ "GenMsgNrOfRepetition" BO_ 1093 1;
BA_ "GenMsgCycleTime" BO_ 1093 100;
BA_ "VFrameFormat" BO_ 1093 14;
BA_ "MsgRoutingId" BO_ 1092 "239 ";
BA_ "GenMsgCycleTime" BO_ 1092 100;
BA_ "VFrameFormat" BO_ 1092 14;
BA_ "GenMsgCycleTime" BO_ 1305 1000;
BA_ "VFrameFormat" BO_ 1305 14;
BA_ "GenMsgILSupport" BO_ 494 0;
BA_ "MsgRoutingId" BO_ 494 "212 ";
BA_ "GenMsgCycleTime" BO_ 494 30;
BA_ "VFrameFormat" BO_ 494 14;
BA_ "VFrameFormat" BO_ 2564550625 1;
BA_ "GenMsgILSupport" BO_ 2564550625 0;
BA_ "DiagState" BO_ 2564550625 1;
BA_ "GenMsgNrOfRepetition" BO_ 2564550625 1;
BA_ "GenMsgSendType" BO_ 2564550625 8;
BA_ "VFrameFormat" BO_ 2564550624 1;
BA_ "MsgRoutingId" BO_ 2564550624 "125 ";
BA_ "GenMsgILSupport" BO_ 2564550624 0;
BA_ "DiagState" BO_ 2564550624 1;
BA_ "GenMsgNrOfRepetition" BO_ 2564550624 1;
BA_ "GenMsgSendType" BO_ 2564550624 8;
BA_ "MsgRoutingId" BO_ 1832 "124 ";
BA_ "GenMsgILSupport" BO_ 1832 0;
BA_ "DiagState" BO_ 1832 1;
BA_ "GenMsgNrOfRepetition" BO_ 1832 1;
BA_ "GenMsgSendType" BO_ 1832 8;
BA_ "GenMsgCycleTime" BO_ 1280 1000;
BA_ "VFrameFormat" BO_ 1280 14;
BA_ "GenMsgCycleTime" BO_ 1633 1000;
BA_ "VFrameFormat" BO_ 1633 14;
BA_ "GenMsgCycleTime" BO_ 1632 500;
BA_ "VFrameFormat" BO_ 1632 14;
BA_ "GenMsgNrOfRepetition" BO_ 1744 1;
BA_ "GenMsgCycleTimeFast" BO_ 1744 100;
BA_ "GenMsgCycleTime" BO_ 1744 1200;
BA_ "VFrameFormat" BO_ 1744 14;
BA_ "GenMsgILSupport" BO_ 1743 0;
BA_ "MsgRoutingId" BO_ 1743 "116 ";
BA_ "GenMsgNrOfRepetition" BO_ 1743 1;
BA_ "GenMsgCycleTimeFast" BO_ 1743 100;
BA_ "GenMsgCycleTime" BO_ 1743 1200;
BA_ "VFrameFormat" BO_ 1743 14;
BA_ "GenMsgILSupport" BO_ 1113 0;
BA_ "MsgRoutingId" BO_ 1113 "113 ";
BA_ "GenMsgCycleTime" BO_ 1113 100;
BA_ "VFrameFormat" BO_ 1113 14;
BA_ "GenMsgILSupport" BO_ 930 0;
BA_ "MsgRoutingId" BO_ 930 "110 ";
BA_ "GenMsgNrOfRepetition" BO_ 930 4;
BA_ "GenMsgCycleTimeFast" BO_ 930 50;
BA_ "GenMsgDelayTime" BO_ 930 10;
BA_ "GenMsgCycleTime" BO_ 930 100;
BA_ "VFrameFormat" BO_ 930 14;
BA_ "GenMsgILSupport" BO_ 912 0;
BA_ "MsgRoutingId" BO_ 912 "105 ";
BA_ "GenMsgNrOfRepetition" BO_ 912 4;
BA_ "GenMsgCycleTimeFast" BO_ 912 50;
BA_ "GenMsgDelayTime" BO_ 912 10;
BA_ "GenMsgCycleTime" BO_ 912 100;
BA_ "VFrameFormat" BO_ 912 14;
BA_ "GenMsgILSupport" BO_ 1657 0;
BA_ "MsgRoutingId" BO_ 1657 "94 ";
BA_ "GenMsgCycleTime" BO_ 1657 1000;
BA_ "VFrameFormat" BO_ 1657 14;
BA_ "GenMsgILSupport" BO_ 827 0;
BA_ "MsgRoutingId" BO_ 827 "93 ";
BA_ "GenMsgNrOfRepetition" BO_ 827 50;
BA_ "GenMsgCycleTimeFast" BO_ 827 120;
BA_ "GenMsgDelayTime" BO_ 827 10;
BA_ "GenMsgCycleTime" BO_ 827 120;
BA_ "VFrameFormat" BO_ 827 14;
BA_ "GenMsgILSupport" BO_ 1621 0;
BA_ "MsgRoutingId" BO_ 1621 "55 ";
BA_ "GenMsgNrOfRepetition" BO_ 1621 10;
BA_ "GenMsgCycleTimeFast" BO_ 1621 20;
BA_ "GenMsgDelayTime" BO_ 1621 10;
BA_ "GenMsgCycleTime" BO_ 1621 1000;
BA_ "VFrameFormat" BO_ 1621 14;
BA_ "GenMsgILSupport" BO_ 1618 0;
BA_ "MsgRoutingId" BO_ 1618 "53 ";
BA_ "GenMsgDelayTime" BO_ 1618 10;
BA_ "GenMsgCycleTime" BO_ 1618 1200;
BA_ "VFrameFormat" BO_ 1618 14;
BA_ "GenMsgILSupport" BO_ 942 0;
BA_ "MsgRoutingId" BO_ 942 "50 ";
BA_ "GenMsgNrOfRepetition" BO_ 942 2;
BA_ "GenMsgCycleTimeFast" BO_ 942 20;
BA_ "GenMsgDelayTime" BO_ 942 10;
BA_ "GenMsgCycleTime" BO_ 942 100;
BA_ "VFrameFormat" BO_ 942 14;
BA_ "GenMsgILSupport" BO_ 940 0;
BA_ "MsgRoutingId" BO_ 940 "49 ";
BA_ "GenMsgNrOfRepetition" BO_ 940 10;
BA_ "GenMsgCycleTimeFast" BO_ 940 20;
BA_ "GenMsgDelayTime" BO_ 940 10;
BA_ "GenMsgCycleTime" BO_ 940 100;
BA_ "VFrameFormat" BO_ 940 14;
BA_ "GenMsgILSupport" BO_ 1616 0;
BA_ "MsgRoutingId" BO_ 1616 "47 ";
BA_ "GenMsgNrOfRepetition" BO_ 1616 10;
BA_ "GenMsgCycleTimeFast" BO_ 1616 20;
BA_ "GenMsgDelayTime" BO_ 1616 10;
BA_ "GenMsgCycleTime" BO_ 1616 1000;
BA_ "VFrameFormat" BO_ 1616 14;
BA_ "GenMsgILSupport" BO_ 809 0;
BA_ "MsgRoutingId" BO_ 809 "41 ";
BA_ "GenMsgNrOfRepetition" BO_ 809 3;
BA_ "GenMsgCycleTimeFast" BO_ 809 20;
BA_ "GenMsgDelayTime" BO_ 809 20;
BA_ "GenMsgCycleTime" BO_ 809 100;
BA_ "VFrameFormat" BO_ 809 14;
BA_ "GenMsgILSupport" BO_ 811 0;
BA_ "MsgRoutingId" BO_ 811 "40 ";
BA_ "GenMsgDelayTime" BO_ 811 10;
BA_ "GenMsgCycleTime" BO_ 811 100;
BA_ "VFrameFormat" BO_ 811 14;
BA_ "GenMsgILSupport" BO_ 362 0;
BA_ "MsgRoutingId" BO_ 362 "38 ";
BA_ "GenMsgCycleTime" BO_ 362 20;
BA_ "VFrameFormat" BO_ 362 14;
BA_ "GenMsgILSupport" BO_ 808 0;
BA_ "MsgRoutingId" BO_ 808 "37 ";
BA_ "GenMsgDelayTime" BO_ 808 10;
BA_ "GenMsgCycleTime" BO_ 808 100;
BA_ "VFrameFormat" BO_ 808 14;
BA_ "GenMsgILSupport" BO_ 315 0;
BA_ "MsgRoutingId" BO_ 315 "35 ";
BA_ "GenMsgCycleTime" BO_ 315 20;
BA_ "VFrameFormat" BO_ 315 14;
BA_ "GenMsgILSupport" BO_ 314 0;
BA_ "MsgRoutingId" BO_ 314 "34 ";
BA_ "GenMsgCycleTime" BO_ 314 20;
BA_ "VFrameFormat" BO_ 314 14;
BA_ "GenMsgILSupport" BO_ 313 0;
BA_ "MsgRoutingId" BO_ 313 "33 ";
BA_ "GenMsgCycleTime" BO_ 313 20;
BA_ "VFrameFormat" BO_ 313 14;
BA_ "GenMsgILSupport" BO_ 312 0;
BA_ "MsgRoutingId" BO_ 312 "32 ";
BA_ "GenMsgCycleTime" BO_ 312 20;
BA_ "VFrameFormat" BO_ 312 14;
BA_ "GenMsgILSupport" BO_ 1143 0;
BA_ "MsgRoutingId" BO_ 1143 "15 ";
BA_ "GenMsgNrOfRepetition" BO_ 1143 3;
BA_ "GenMsgCycleTimeFast" BO_ 1143 20;
BA_ "GenMsgCycleTime" BO_ 1143 1000;
BA_ "VFrameFormat" BO_ 1143 14;
BA_ "GenMsgILSupport" BO_ 1142 0;
BA_ "MsgRoutingId" BO_ 1142 "14 ";
BA_ "GenMsgNrOfRepetition" BO_ 1142 3;
BA_ "GenMsgCycleTimeFast" BO_ 1142 20;
BA_ "GenMsgCycleTime" BO_ 1142 500;
BA_ "VFrameFormat" BO_ 1142 14;
BA_ "GenMsgILSupport" BO_ 1112 0;
BA_ "MsgRoutingId" BO_ 1112 "11 ";
BA_ "GenMsgCycleTime" BO_ 1112 100;
BA_ "VFrameFormat" BO_ 1112 14;
BA_ "GenSigStartValue" SG_ 803 EYE323_7_0_ISA_OFFSET_CURR 10;
BA_ "GenSigStartValue" SG_ 803 EYE323_6_1_LDW_ON_OFF_SET 1;
BA_ "GenSigStartValue" SG_ 803 EYE323_5_3_FCW_ON_OFF_SET 1;
BA_ "GenSigSendType" SG_ 2564481222 EVCC18DAE0C6_DIAG_DATA 2;
BA_ "GenSigSendType" SG_ 2564474592 DNT18DAC6E0_DIAG_DATA 2;
BA_ "GenSigSendType" SG_ 2564481219 EVCC18DAE0C3_DIAG_DATA 2;
BA_ "GenSigSendType" SG_ 2564473824 DNT18DAC3E0_DIAG_DATA 2;
BA_ "GenSigSendType" SG_ 2564481478 EVCC18DAE1C6_DIAG_DATA_EXT7 2;
BA_ "GenSigSendType" SG_ 2564481478 EVCC18DAE1C6_DIAG_DATA_EXT6 2;
BA_ "GenSigSendType" SG_ 2564481478 EVCC18DAE1C6_DIAG_DATA_EXT5 2;
BA_ "GenSigSendType" SG_ 2564481478 EVCC18DAE1C6_DIAG_DATA_EXT4 2;
BA_ "GenSigSendType" SG_ 2564481478 EVCC18DAE1C6_DIAG_DATA_EXT3 2;
BA_ "GenSigSendType" SG_ 2564481478 EVCC18DAE1C6_DIAG_DATA_EXT2 2;
BA_ "GenSigSendType" SG_ 2564481478 EVCC18DAE1C6_DIAG_DATA_EXT1 2;
BA_ "GenSigSendType" SG_ 2564481478 EVCC18DAE1C6_DIAG_DATA 2;
BA_ "GenSigSendType" SG_ 2564474593 CECU18DAC6E1_DIAG_DATA_EXT7 2;
BA_ "GenSigSendType" SG_ 2564474593 CECU18DAC6E1_DIAG_DATA_EXT6 2;
BA_ "GenSigSendType" SG_ 2564474593 CECU18DAC6E1_DIAG_DATA_EXT5 2;
BA_ "GenSigSendType" SG_ 2564474593 CECU18DAC6E1_DIAG_DATA_EXT4 2;
BA_ "GenSigSendType" SG_ 2564474593 CECU18DAC6E1_DIAG_DATA_EXT3 2;
BA_ "GenSigSendType" SG_ 2564474593 CECU18DAC6E1_DIAG_DATA_EXT2 2;
BA_ "GenSigSendType" SG_ 2564474593 CECU18DAC6E1_DIAG_DATA_EXT1 2;
BA_ "GenSigSendType" SG_ 2564474593 CECU18DAC6E1_DIAG_DATA 2;
BA_ "GenSigSendType" SG_ 2564481475 EVCC18DAE1C3_DIAG_DATA_EXT7 2;
BA_ "GenSigSendType" SG_ 2564481475 EVCC18DAE1C3_DIAG_DATA_EXT6 2;
BA_ "GenSigSendType" SG_ 2564481475 EVCC18DAE1C3_DIAG_DATA_EXT5 2;
BA_ "GenSigSendType" SG_ 2564481475 EVCC18DAE1C3_DIAG_DATA_EXT4 2;
BA_ "GenSigSendType" SG_ 2564481475 EVCC18DAE1C3_DIAG_DATA_EXT3 2;
BA_ "GenSigSendType" SG_ 2564481475 EVCC18DAE1C3_DIAG_DATA_EXT2 2;
BA_ "GenSigSendType" SG_ 2564481475 EVCC18DAE1C3_DIAG_DATA_EXT1 2;
BA_ "GenSigSendType" SG_ 2564481475 EVCC18DAE1C3_DIAG_DATA 2;
BA_ "GenSigSendType" SG_ 2564473825 CECU18DAC3E1_DIAG_DATA_EXT7 2;
BA_ "GenSigSendType" SG_ 2564473825 CECU18DAC3E1_DIAG_DATA_EXT6 2;
BA_ "GenSigSendType" SG_ 2564473825 CECU18DAC3E1_DIAG_DATA_EXT5 2;
BA_ "GenSigSendType" SG_ 2564473825 CECU18DAC3E1_DIAG_DATA_EXT4 2;
BA_ "GenSigSendType" SG_ 2564473825 CECU18DAC3E1_DIAG_DATA_EXT3 2;
BA_ "GenSigSendType" SG_ 2564473825 CECU18DAC3E1_DIAG_DATA_EXT2 2;
BA_ "GenSigSendType" SG_ 2564473825 CECU18DAC3E1_DIAG_DATA_EXT1 2;
BA_ "GenSigSendType" SG_ 2564473825 CECU18DAC3E1_DIAG_DATA 2;
BA_ "GenSigSendType" SG_ 1098 EVCC44A_3_0_PNC_CC_SAVE_RES_RSLT 4;
BA_ "GenSigStartValue" SG_ 1096 EVCC448_4_0_EVSECONFPAYOPT 1;
BA_ "GenSigSendType" SG_ 1095 EVCC447_3_4_CHGWAKE 3;
BA_ "GenSigSendType" SG_ 1095 EVCC447_3_0_CHGMODE 3;
BA_ "GenSigSendType" SG_ 1093 EVCC445_3_0_DISPREQ 3;
BA_ "GenSigSendType" SG_ 2564550625 CECU18DBEFE1_DIAG_DATA 2;
BA_ "GenSigSendType" SG_ 2564550624 DNT18DBEFE0_DIAG_DATA 2;
BA_ "GenSigSendType" SG_ 1832 DNT728_7_0_DIAG_DATA 2;
BA_ "GenSigSendType" SG_ 1832 DNT728_2_0_DIAG_N_PCI_OR_DATA 2;
BA_ "GenSigSendType" SG_ 1832 DNT728_1_0_DIAG_N_PCI_OR_DATA 2;
BA_ "GenSigSendType" SG_ 1832 DNT728_0_0_DIAG_N_PCI 2;
BA_ "GenSigStartValue" SG_ 1632 CGW660_1_0_SUB_ID 65535;
BA_ "GenSigStartValue" SG_ 930 MET3A2_7_0_FUEL_AMOUNT 254;
BA_ "Fhi_SignalComment" SG_ 912 MET390_6_0_SEATBELT_DRVR "IGN-OFF中は0送信

";
BA_ "Fhi_SignalComment" SG_ 912 MET390_6_1_SEATBELT_PASS "IGN-OFF中は0送信

";
BA_ "Fhi_SignalComment" SG_ 912 MET390_4_0_OUTTEMP_FOR_IND "IGN-OFF中は初期値：FEh送信

";
BA_ "GenSigStartValue" SG_ 912 MET390_4_0_OUTTEMP_FOR_IND 254;
BA_ "Fhi_SignalComment" SG_ 912 MET390_2_0_VEHICLE_SERIES "GW:ID390-B2b2~b0→ID2BE-B5b2~b0

";
BA_ "Fhi_SignalComment" SG_ 912 MET390_2_3_DESTINATION "GW:ID390-B2b6~b3→ID2BE-B5b6~b3

";
BA_ "GenSigSendType" SG_ 1657 TPM679_3_0_STATE_TPMS 3;
BA_ "GenSigSendType" SG_ 1657 TPM679_3_2_DEFINED_STATE_TPMS 3;
BA_ "Fhi_SignalComment" SG_ 1657 TPM679_3_2_DEFINED_STATE_TPMS "※閾値設定スイッチがタッチパネルの車は、送信値を0固定とする。

";
BA_ "GenSigSendType" SG_ 1657 TPM679_2_0_WARN_TPMS 3;
BA_ "GenSigSendType" SG_ 1657 TPM679_2_3_INTERRUPT 3;
BA_ "GenSigStartValue" SG_ 827 ABG33B_4_0_PASSENGER_BELT_INFO 2;
BA_ "GenSigStartValue" SG_ 827 ABG33B_4_2_PASSENGER_DETECT_INFO 4;
BA_ "GenSigStartValue" SG_ 827 ABG33B_2_0_IND_WARN_PPA 3;
BA_ "GenSigSendType" SG_ 1618 BIU652_7_0_IND_SECURITY_IMB 3;
BA_ "GenSigSendType" SG_ 1618 BIU652_6_0_OCCUPATION_3RDRH 3;
BA_ "GenSigSendType" SG_ 1618 BIU652_6_1_OCCUPATION_3RDCTR 3;
BA_ "GenSigSendType" SG_ 1618 BIU652_6_2_OCCUPATION_3RDLH 3;
BA_ "GenSigSendType" SG_ 1618 BIU652_6_3_OCCUPATION_RRRH 3;
BA_ "GenSigSendType" SG_ 1618 BIU652_6_4_OCCUPATION_RRCTR 3;
BA_ "GenSigSendType" SG_ 1618 BIU652_6_5_OCCUPATION_RRLH 3;
BA_ "GenSigSendType" SG_ 1618 BIU652_6_6_HORNHAZARD_RES_SIG 3;
BA_ "GenSigSendType" SG_ 1618 BIU652_6_7_OCCUPATION_DRVR 3;
BA_ "GenSigSendType" SG_ 1618 BIU652_5_0_STATUS_ROOMLAMP 3;
BA_ "GenSigSendType" SG_ 1618 BIU652_5_3_HEADLAMP_SMALL 3;
BA_ "GenSigSendType" SG_ 1618 BIU652_5_4_ALL_UNLOCK_STATE 3;
BA_ "GenSigSendType" SG_ 1618 BIU652_5_5_DRVR_UNLOCK_STATE 3;
BA_ "GenSigSendType" SG_ 1618 BIU652_5_6_ALL_LOCK_STATE 3;
BA_ "GenSigSendType" SG_ 1618 BIU652_4_0_TRIG_LOCK_UNLOCK 3;
BA_ "GenSigSendType" SG_ 1618 BIU652_3_0_DOOR_DRVR 3;
BA_ "GenSigSendType" SG_ 1618 BIU652_3_1_DOOR_PASS 3;
BA_ "GenSigSendType" SG_ 1618 BIU652_3_2_DOOR_RRRH 3;
BA_ "GenSigSendType" SG_ 1618 BIU652_3_3_DOOR_RRLH 3;
BA_ "GenSigSendType" SG_ 1618 BIU652_3_4_DOOR_RG 3;
BA_ "GenSigSendType" SG_ 1618 BIU652_3_5_DOOR_TR 3;
BA_ "GenSigSendType" SG_ 1618 BIU652_3_7_OPENSW_RG 3;
BA_ "GenSigSendType" SG_ 1618 BIU652_2_0_LOCKSTATUS_DRVR 3;
BA_ "GenSigSendType" SG_ 1618 BIU652_2_1_LOCKSTATUS_PASS 3;
BA_ "GenSigSendType" SG_ 1618 BIU652_2_2_LOCKSTATUS_RRRH 3;
BA_ "GenSigSendType" SG_ 1618 BIU652_2_3_LOCKSTATUS_RRLH 3;
BA_ "GenSigSendType" SG_ 1618 BIU652_2_4_LOCKSTATUS_RG 3;
BA_ "GenSigSendType" SG_ 1618 BIU652_2_6_UNLOCK_DOORKEYSW 3;
BA_ "GenSigSendType" SG_ 1618 BIU652_2_7_LOCK_DOORKEYSW 3;
BA_ "GenSigStartValue" SG_ 942 BIU3AE_5_0_WIPER_FT_VOLUME 2;
BA_ "GenSigStartValue" SG_ 809 BST329_1_4_EB_HMI_WARNINGON 1;
BA_ "GenSigStartValue" SG_ 809 BST329_1_6_WARN_BST_RED 1;
BA_ "Fhi_SignalComment" SG_ 811 EPB32B_6_0_VEHICLE_RUN_STOP_FLG "-

";
BA_ "Fhi_SignalComment" SG_ 811 EPB32B_5_0_FLG_AVH_OILPRES_EPB "-

";
BA_ "Fhi_SignalComment" SG_ 811 EPB32B_5_1_FLG_AVH "-

";
BA_ "Fhi_SignalComment" SG_ 811 EPB32B_5_2_AVH_INTENSIFY_PRES "-

";
BA_ "Fhi_SignalComment" SG_ 811 EPB32B_5_3_BREAK_IND "-

";
BA_ "Fhi_SignalComment" SG_ 811 EPB32B_5_5_AVH_ON_LAMP "-

";
BA_ "Fhi_SignalComment" SG_ 811 EPB32B_4_0_BUZZER "-

";
BA_ "Fhi_SignalComment" SG_ 811 EPB32B_4_2_HILL_HOLD_ON_LAMP "-

";
BA_ "Fhi_SignalComment" SG_ 811 EPB32B_4_3_CLAMP_LAMP "-

";
BA_ "Fhi_SignalComment" SG_ 811 EPB32B_4_5_WARN_LAMP "-

";
BA_ "Fhi_SignalComment" SG_ 811 EPB32B_4_7_WARN_EPB_MET_LCD "-

";
BA_ "Fhi_SignalComment" SG_ 811 EPB32B_3_0_STATUS_EPB "-

";
BA_ "Fhi_SignalComment" SG_ 811 EPB32B_3_3_DYNAMIC_PARKING "-

";
BA_ "Fhi_SignalComment" SG_ 811 EPB32B_3_4_HILL_HOLD_RUN_FLG "-

";
BA_ "Fhi_SignalComment" SG_ 811 EPB32B_3_5_INHIBIT_ISS_DELAY "-

";
BA_ "Fhi_SignalComment" SG_ 811 EPB32B_3_6_INHIBIT_ISS "-

";
BA_ "Fhi_SignalComment" SG_ 811 EPB32B_2_0_ERR_INFO "-

";
BA_ "Fhi_SignalComment" SG_ 811 EPB32B_2_2_EPB_FAIL_FLG1 "-

";
BA_ "Fhi_SignalComment" SG_ 811 EPB32B_2_3_EPB_FAIL_FLG2 "-

";
BA_ "Fhi_SignalComment" SG_ 811 EPB32B_2_4_EPB_FAIL_FLG3 "-

";
BA_ "Fhi_SignalComment" SG_ 811 EPB32B_1_5_REQ_COMM_CONT "-

";
BA_ "GenSigSendType" SG_ 808 VDC328_7_3_FLAG_ACT_CBC 3;
BA_ "GenSigStartValue" SG_ 808 VDC328_5_2_WARN_BRAKE_BOOST 1;
BA_ "GenSigSendType" SG_ 808 VDC328_5_4_WARN_RBS 3;
BA_ "GenSigSendType" SG_ 808 VDC328_5_6_IND_HSA_ON 3;
BA_ "GenSigSendType" SG_ 808 VDC328_5_7_IND_TCS_OFF 3;
BA_ "GenSigStartValue" SG_ 808 VDC328_5_7_IND_TCS_OFF 1;
BA_ "GenSigStartValue" SG_ 808 VDC328_4_0_IND_VDC_OFF 1;
BA_ "GenSigStartValue" SG_ 808 VDC328_4_5_WARNING_BRAKE_SYS 1;
BA_ "GenSigStartValue" SG_ 808 VDC328_3_0_IND_WARN_EBD 1;
BA_ "GenSigStartValue" SG_ 808 VDC328_3_1_IND_WARN_ABS 1;
BA_ "GenSigStartValue" SG_ 808 VDC328_3_2_IND_WARN_VDC 1;
BA_ "GenSigStartValue" SG_ 808 VDC328_3_3_IND_WARN_HSA 1;
BA_ "GenSigStartValue" SG_ 808 VDC328_3_6_IND_TCS_OFF 1;
BA_ "Fhi_SignalComment" SG_ 315 VDC13B_7_0_ACCELERATE_F_R "補正値

";
BA_ "Fhi_SignalComment" SG_ 315 VDC13B_6_0_ACCELERATE_L_R "補正値

";
BA_ "GenSigStartValue" SG_ 315 VDC13B_4_0_ENG_TRQ_DOWN 65535;
BA_ "GenSigStartValue" SG_ 313 VDC139_7_4_FAIL_PRESSURE_SSR 1;
BA_ "Fhi_SignalComment" SG_ 313 VDC139_7_5_STATUS_EPB "-

";
BA_ "GenSigStartValue" SG_ 313 VDC139_4_3_FAIL_BRAKELAMPSW 1;
BA_ "GenSigStartValue" SG_ 313 VDC139_3_5_FAIL_VDC_SSR 1;
BA_ "GenSigStartValue" SG_ 313 VDC139_3_6_FAIL_SPD_SSR_FHI 1;
BA_ "GenSigStartValue" SG_ 313 VDC139_3_7_FAIL_ABS_SYS 1;
BA_ "Fhi_SignalComment" SG_ 313 VDC139_2_0_SPD_WHEEL_AVE "GW:ID139-B3b4~B2b0→ID270-B5b4~B4b0

";
BA_ "GenSigStartValue" SG_ 313 VDC139_1_4_FAIL_HDC_SYS 1;
BA_ "Fhi_SignalComment" SG_ 313 VDC139_1_5_VEHICLE_HIGHT "XUVは「01:OBK」/北米SPORT_OBKは「10:標準」を送信

";
BA_ "Fhi_SignalComment" SG_ 312 VDC138_7_0_PRESSURE_WC_FTLH "EyeSight対応以外は『0固定』

";
BA_ "Fhi_SignalComment" SG_ 312 VDC138_6_0_PRESSURE_WC_FTRH "EyeSight対応以外は『0固定』

";
BA_ "Fhi_SignalComment" SG_ 312 VDC138_4_0_YAW_RATE "補正値

";
BA_ "Fhi_SignalComment" SG_ 312 VDC138_2_0_STEER_ANGLE "補正値

";
BA_ "GenSigStartValue" SG_ 1143 CCU477_24_0_TIM4_CHG_END_TIME 2046;
BA_ "GenSigStartValue" SG_ 1143 CCU477_22_2_TIM4_CHG_START_TIME 2046;
BA_ "GenSigStartValue" SG_ 1143 CCU477_18_0_TIM3_CHG_END_TIME 2046;
BA_ "GenSigStartValue" SG_ 1143 CCU477_16_2_TIM3_CHG_START_TIME 2046;
BA_ "GenSigStartValue" SG_ 1143 CCU477_12_0_TIM2_CHG_END_TIME 2046;
BA_ "GenSigStartValue" SG_ 1143 CCU477_10_2_TIM2_CHG_START_TIME 2046;
BA_ "GenSigStartValue" SG_ 1143 CCU477_6_0_TIM1_CHG_END_TIME 2046;
BA_ "GenSigStartValue" SG_ 1143 CCU477_4_2_TIM1_CHG_START_TIME 2046;
BA_ "GenSigStartValue" SG_ 1142 CCU476_13_1_STS_PNC 2;
BA_ "GenSigStartValue" SG_ 1142 CCU476_11_1_STOP_TIM_TIM_CHG 511;
BA_ "GenSigStartValue" SG_ 1142 CCU476_10_0_START_TIM_TIM_CHG 511;
BA_ "GenSigStartValue" SG_ 1142 CCU476_5_1_STOP_TIM_CH_TIM_CHG 511;
BA_ "GenSigStartValue" SG_ 1142 CCU476_4_0_START_TIM_CH_TIM_CHG 511;
VAL_ 803 EYE323_7_5_SLIF_FUNC_INFO 1 "Requirement" 0 "No requirement" ;
VAL_ 803 EYE323_7_6_ISA_FUNC_INFO 1 "Requirement" 0 "No requirement" ;
VAL_ 803 EYE323_7_7_ISA_CUSTOMIZE_CURR 1 "ISA enable" 0 "ISA disable" ;
VAL_ 803 EYE323_6_0_LDW_OFFSW_INFO 1 "requirement" 0 "No requirement" ;
VAL_ 803 EYE323_6_1_LDW_ON_OFF_SET 1 "enable" 0 "disable" ;
VAL_ 803 EYE323_6_2_CSTM_DDAW_WARN_SET 1 "ON" 0 "OFF" ;
VAL_ 803 EYE323_6_3_IACC_FUNC_INFO 1 "Requirement" 0 "No requirement" ;
VAL_ 803 EYE323_6_5_CSTM_LDW_TIMING_SET 1 "LATE" 0 "EARLY" ;
VAL_ 803 EYE323_6_6_CSTM_LDW_TIMING 1 "Requirement" 0 "No requirement" ;
VAL_ 803 EYE323_6_7_SLOWDOWNL_FUNC_INFO 1 "Requirement" 0 "No requirement" ;
VAL_ 803 EYE323_5_0_CNG_GRN_CONT_CURR 1 "enable" 0 "disable" ;
VAL_ 803 EYE323_5_1_TRAFFIC_FUNC_INFO 1 "Requirement" 0 "No requirement" ;
VAL_ 803 EYE323_5_2_FCW_OFFSW_INFO 1 "requirement" 0 "No requirement" ;
VAL_ 803 EYE323_5_3_FCW_ON_OFF_SET 1 "enable" 0 "disable" ;
VAL_ 803 EYE323_5_4_WARNING_SEL_CURR 1 "Vibration" 0 "Sound" ;
VAL_ 803 EYE323_5_5_HAPT_FUNC_INFO 1 "Requirement" 0 "No requirement" ;
VAL_ 803 EYE323_5_6_TOLLGATE_CONT_CURR 1 "enable" 0 "disable" ;
VAL_ 803 EYE323_5_7_CURVE_CONT_CURR 1 "enable" 0 "disable" ;
VAL_ 803 EYE323_4_0_FCTB_ICON_L 3 "No_Definition" 2 "BLINK" 1 "TURN_ON" 0 "TURN_OFF" ;
VAL_ 803 EYE323_4_2_FCTB_ICON_R 3 "No_Definition" 2 "BLINK" 1 "TURN_ON" 0 "TURN_OFF" ;
VAL_ 803 EYE323_4_4_FCW_CONT_CURR 3 "OFF" 2 "FAR" 1 "NEAR" 0 "ON/STD." ;
VAL_ 803 EYE323_4_6_FCW_DISPLAY_SEL 3 "FULL SELECT" 2 "ON/OFF SELECT" 1 "Distance SELECT" 0 "TURN OFF" ;
VAL_ 803 EYE323_3_0_AES_FUNC_INFO 1 "Requirement" 0 "No requirement" ;
VAL_ 803 EYE323_3_1_CSTM_TSR_NO_ENTRY_SET 1 "ON" 0 "OFF" ;
VAL_ 803 EYE323_3_2_CSTM_TSR_STOP_SET 1 "ON" 0 "OFF" ;
VAL_ 803 EYE323_3_3_CSTM_TSR_GIVE_WAY_SET 1 "ON" 0 "OFF" ;
VAL_ 803 EYE323_3_4_WILDERNESS 1 "WILDERNESS" 0 "NOT_WILDERNESS" ;
VAL_ 803 EYE323_3_5_AES_OFF 1 "TURN_ON" 0 "TURN_OFF" ;
VAL_ 803 EYE323_3_6_FCTB_IND 3 "No_Definition" 2 "FAIL_ON" 1 "TURN_ON" 0 "TURN_OFF" ;
VAL_ 803 EYE323_2_0_CSTM_LDW_ALK_B 3 "ALK-B ON /LDW ON" 2 "ALK-B ON /LDW OFF" 1 "ALK-B OFF/LDW ON" 0 "ALK-B OFF/LDW OFF" ;
VAL_ 803 EYE323_2_2_CSTM_P_CR 1 "ON" 0 "OFF" ;
VAL_ 803 EYE323_2_3_SLOWDOWN_FUNC_INFO2 1 "Requirement" 0 "No requirement" ;
VAL_ 803 EYE323_2_4_CID_CODE_WARN 15 "Drowsiness attention" 14 "Eyes on request(3rd/4th)" 13 "Eyes on request(2nd)" 12 "MRM Interruption Vehicle" 11 "MRM Interruption Steering" 10 "MRM Interruption Lane change" 9 "MRM Stop" 8 "Handle steering" 7 "MRM Lane change Left" 6 "MRM Lane change Right" 5 "MRM Road shoulder Evacuation" 4 "B1 no-opr. cancel alarm" 3 "B1 no-opr. warning(long)" 2 "MRM Operation Notice" 1 "PreCrashBreak(1st)/Brake incr. alarm" 0 "No alarm " ;
VAL_ 803 EYE323_1_4_DISP_FOLLOW_FORWARD 1 "ON" 0 "OFF" ;
VAL_ 803 EYE323_1_5_KEEP_LINE_SENTER_ACT 1 "ON" 0 "OFF" ;
VAL_ 803 EYE323_1_6_DDAW_FAIL_OFF 3 "No_Definition" 2 "OFF" 1 "FAIL" 0 "TURN_OFF" ;
VAL_ 1098 EVCC44A_3_0_PNC_CC_SAVE_RES_RSLT 5 "Fail_(Not_Exist)" 4 "Fail_(Retry_to_SRV)" 3 "Fail_(Retry_to_CECU)" 2 "Fail_(No_Retry)" 1 "Success" 0 "Unknown" ;
VAL_ 1096 EVCC448_4_0_EVSECONFPAYOPT 2 "EIM" 1 "PnC" ;
VAL_ 1096 EVCC448_3_0_PNC_SW_RES_EVCC 8 "Fail" 5 "NG_(OFF_LOCK)_Failed_to_set_OFF_LOCK" 4 "NG_(New)_Failed_to_set_NEW" 3 "NG_(Lock)_Failed_to_set_lock" 2 "NG_(ON)_Failed_to_set_ON" 1 "NG_(OFF)_Failed_to_set_OFF" 0 "No_NG" ;
VAL_ 1096 EVCC448_3_4_PNC_SW_STS 7 "Fail" 4 "New_State" 3 "Lock_State" 2 "On_State" 1 "Off_State" 0 "Undefined" ;
VAL_ 1096 EVCC448_3_7_SW_STS_ACTIVE_FLG 1 "Change" 0 "No_Change" ;
VAL_ 1093 EVCC445_4_0_CHGCNRLOCSTT_DISPREQ 2 "Lock_Display_Request" 1 "Unlock_Display_Request" 0 "Hidden" ;
VAL_ 1093 EVCC445_3_0_DISPREQ 1 "Request" 0 "No_Request" ;
VAL_ 1093 EVCC445_3_1_CNCTCONSTT_DISP 1 "Connector_Connected" 0 "Connector_Not_Connected" ;
VAL_ 1093 EVCC445_3_2_LIDOPSHSTT_DISP 2 "Lid_Open" 1 "Lid_Closed" 0 "Indeterminate" ;
VAL_ 1093 EVCC445_3_5_CNCTLCKSTT_DISP 2 "Locked_State" 1 "Unlocked_State" 0 "Initial" ;
VAL_ 1092 EVCC444_3_0_CNTCPLTYP 1 "NACS_(including_AC,_DC)" 0 "Undetermined" ;
VAL_ 1092 EVCC444_3_2_CHGFRM_CCU 2 "DC_Charging" 1 "AC_Charging" 0 "Undetermined" ;
VAL_ 1305 EVCC519_1_4_ACTIVEWAKEUPBIT 1 "WakeUP_FRAME" 0 "Normal_FRAME" ;
VAL_ 1280 CGW500_1_4_ActiveWakeUpBit 1 "active wakeup" 0 "passive wakeup" ;
VAL_ 1632 CGW660_1_0_SUB_ID 65535 "NORMAL" ;
VAL_ 1744 CECU6D0_4_0_OTA_ABORT 1 "OTA中止" 0 "OTA中止でない" ;
VAL_ 1744 CECU6D0_4_1_OTA_SUSPEND 1 "OTA中断" 0 "OTA中断でない" ;
VAL_ 1744 CECU6D0_4_2_OTA_SEQUENCE 33170 "予備" 16534 "予備" 8264 "Campaignなし" 4132 "OTA完了" 1298 "SWID照合中" 598 "電源ON待ち" 296 "電源OFF待ち" 100 "Activate中(Dual)" 50 "Install中(Single)" 22 "アップデート適用開始待ち" 8 "アップデート適用承諾待ち" 4 "Install中(Dual)" 2 "Download中" 1 "Campaign情報取得中" 0 "未実施" ;
VAL_ 1743 DCM6CF_6_6_AACN_FLG 1 "AACN有" 0 "AACN無" ;
VAL_ 1743 DCM6CF_5_0_EMERGENCY_CALL_ON_OFF 1 "Emergency_call_ON" 0 "Emergency_call_OFF" ;
VAL_ 1743 DCM6CF_4_2_STR_HEATER_ON_OFF 1 "Steering_heater_ON" 0 "Steering_heater_OFF" ;
VAL_ 1743 DCM6CF_3_0_RES_CONTRACT_INFO 1 "ON" 0 "OFF" ;
VAL_ 1743 DCM6CF_3_1_REQ_ST_ON 1 "ON" 0 "OFF" ;
VAL_ 1743 DCM6CF_3_3_ON_SIGN 1 "ON" 0 "OFF" ;
VAL_ 1743 DCM6CF_3_5_REQ_PARKLIGHT_HORN 7 "NOT REQUEST" 6 "NOT REQUEST" 5 "NOT REQUEST" 4 "PARK LIGHT ON&HORN OFF" 3 "PARK LIGHT&HORN ANSWER BACK 3 TIME" 2 "PARK LIGHT&HORN ANSWER BACK 2 TIME" 1 "PARK LIGHT&HORN ANSWER BACK 1 TIME" 0 "NOT REQUEST" ;
VAL_ 1743 DCM6CF_2_1_DCM_FAILURE_STATUS 1 "at least one failure is detected" 0 "no failure is detected" ;
VAL_ 1743 DCM6CF_2_2_REQ_WINDOW_STATUS 1 "REQUEST" 0 "NOT_REQUEST" ;
VAL_ 1743 DCM6CF_1_6_DKY_PROV_STS 1 "ON" 0 "OFF" ;
VAL_ 1743 DCM6CF_1_7_PNC_PROV_STS 1 "ON" 0 "OFF" ;
VAL_ 930 MET3A2_6_0_SEATBELT_RR_RH 1 "ON_BeltOFF" 0 "OFF_BeltON" ;
VAL_ 930 MET3A2_6_1_SEATBELT_RR_CTR 1 "ON_BeltOFF" 0 "OFF_BeltON" ;
VAL_ 930 MET3A2_6_2_SEATBELT_RR_LH 1 "ON_BeltOFF" 0 "OFF_BeltON" ;
VAL_ 930 MET3A2_6_3_SEATBELT_THIRD_RH 1 "ON_BeltOFF" 0 "OFF_BeltON" ;
VAL_ 930 MET3A2_6_4_SEATBELT_THIRD_CTR 1 "ON_BeltOFF" 0 "OFF_BeltON" ;
VAL_ 930 MET3A2_6_5_SEATBELT_THIRD_LH 1 "ON_BeltOFF" 0 "OFF_BeltON" ;
VAL_ 930 MET3A2_5_0_FLG_RR_REMINDER 1 "REAR REMINDER ON" 0 "OFF" ;
VAL_ 930 MET3A2_1_4_FAIL_DISP 3 "Reserve" 2 "Reserve" 1 "MET_FAIL_DISP" 0 "NORMAL" ;
VAL_ 912 MET390_7_0_VDC_ON_OFF 3 "BLANK_NoInput" 2 "VDC ON_Input" 1 "VDC OFF_Input" 0 "Neutral" ;
VAL_ 912 MET390_7_2_RR_DOOR_RECORD_L 1 "OPEN" 0 "CLOSE" ;
VAL_ 912 MET390_7_3_RR_DOOR_RECORD_R 1 "OPEN" 0 "CLOSE" ;
VAL_ 912 MET390_7_4_REQ_CHG_CSTM_PSM 1 "required" 0 "NOT required" ;
VAL_ 912 MET390_7_5_REQ_RESET_CSTM_PSM 1 "REQUIRED" 0 "NOT　REQUIRED" ;
VAL_ 912 MET390_7_6_CSTM_MIR_AFOLD_CONT 1 "ON" 0 "OFF" ;
VAL_ 912 MET390_7_7_CSTM_MIR_RTILT_CONT 1 "ON" 0 "OFF" ;
VAL_ 912 MET390_6_0_SEATBELT_DRVR 1 "ON" 0 "OFF" ;
VAL_ 912 MET390_6_1_SEATBELT_PASS 1 "ON" 0 "OFF" ;
VAL_ 912 MET390_6_2_TURN_SIG_LEFT 1 "Turn_L_OutPut" 0 "OFF" ;
VAL_ 912 MET390_6_3_TURN_SIG_RIGHT 1 "Turn_R_OutPut" 0 "OFF" ;
VAL_ 912 MET390_6_4_BRIGHT_SW 1 "ON" 0 "OFF" ;
VAL_ 912 MET390_6_5_FAIL_UART_WA_BOX 1 "FAIL" 0 "NORMAL" ;
VAL_ 912 MET390_6_6_ISS_OFF_SW 1 "While SW is being pushed down." 0 "While SW is not being pushed down." ;
VAL_ 912 MET390_6_7_FLG_DMS 1 "DMS" 0 "NOT_DMS" ;
VAL_ 912 MET390_3_0_UNIT_SPEED_TRIP 1 "MPH、miles" 0 "km/h、km" ;
VAL_ 912 MET390_3_1_FLG_EYESIGHT 1 "EYESIGHT" 0 "OTHER" ;
VAL_ 912 MET390_3_2_FLG_ISS 1 "ISS" 0 "OTHER" ;
VAL_ 912 MET390_3_3_FLG_HEV 1 "HEV" 0 "OTHER" ;
VAL_ 912 MET390_3_4_FLG_IMB 1 "IMB_ACTIVE" 0 "NON_IMB" ;
VAL_ 912 MET390_3_5_TIRE_SIZE 1 "SPECIAL_SIZE" 0 "STANDARD_SIZE" ;
VAL_ 912 MET390_3_6_FLG_XMODE 3 "X_2MODE(GRAVEL)" 2 "X_2MODE" 1 "X_1MODE" 0 "NOT_X" ;
VAL_ 912 MET390_2_0_VEHICLE_SERIES 7 "VEHICLE_Z" 6 "VEHICLE_W" 5 "VEHICLE_V" 4 "VEHICLE_B" 3 "VEHICLE_Y" 2 "VEHICLE_S" 1 "VEHICLE_G" 0 "NON" ;
VAL_ 912 MET390_2_3_DESTINATION 12 "KC" 11 "Korea_C6" 10 "China_EHETES" 9 "Australia_KA" 8 "Singapore_ERENKYKEKVKP" 7 "England_EK" 6 "SaudiArabia_KSKG" 5 "STANDARD_LH_K4E3E5C4" 4 "Europe_LH_ECEAE2EEEPE9E7E1" 3 "CANADA_C5C0" 2 "US_U4U5U6" 1 "DOM" 0 "NON" ;
VAL_ 912 MET390_2_7_PASS_DOOR_RECORD 1 "OPEN" 0 "CLOSE" ;
VAL_ 912 MET390_1_4_WAKE_UP_FRAME 1 "WakeUP_FRAME" 0 "Normal_FRAME" ;
VAL_ 912 MET390_1_5_REQ_COMM_CONT 1 "REQ" 0 "NON_REQ" ;
VAL_ 912 MET390_1_6_DMS_ID_SET 1 "REQUIRED" 0 "NOT REQUIRED" ;
VAL_ 912 MET390_1_7_FAIL_EEPROM 1 "FAIL" 0 "NORMAL" ;
VAL_ 1657 TPM679_3_0_STATE_TPMS 3 "MODE_ERROR" 2 "TPMS3" 1 "TPMS2" 0 "TPMS1" ;
VAL_ 1657 TPM679_3_2_DEFINED_STATE_TPMS 3 "UNDER_CONFIRMATION" 2 "THRESHOLD_DECISION" 1 "UNDER_THRESHOLDING" 0 "NOMAL" ;
VAL_ 1657 TPM679_3_4_MODE_SELECT_TPMS 3 "Undefined" 2 "2Mode" 1 "3Mode" 0 "NOMAL" ;
VAL_ 1657 TPM679_2_0_WARN_TPMS 7 "FLASH_ON_1" 6 "FLASH_ON_3" 5 "FLASH_ON_3" 4 "FLASH_ON_2" 3 "FLASH_ON_1" 2 "FLASH_ON_1" 1 "LAMP_ON" 0 "LAMP_OFF" ;
VAL_ 1657 TPM679_2_3_INTERRUPT 2 "SYSTEM_FAIL" 1 "LOW_PRESSURE" 0 "NON_IND" ;
VAL_ 1657 TPM679_2_5_CHECKLUMP_TPMS 1 "LAMP_ON" 0 "LAMP_OFF" ;
VAL_ 827 ABG33B_4_0_PASSENGER_BELT_INFO 3 "MALFUNCTION" 2 "UNSTTLED" 1 "BELTED" 0 "UNBELTED" ;
VAL_ 827 ABG33B_4_2_PASSENGER_DETECT_INFO 7 "RESERVED" 6 "RESERVED" 5 "MALFUNCTION" 4 "UNSETTLED UNSTTLED" 3 "AM50 INCLUDING AM95" 2 "AF05" 1 "CHILD OR CRS (CHILD RESTRAINT SYSTEM)" 0 "NOT OCCUPANT" ;
VAL_ 827 ABG33B_3_0_PPS_STATUS_FAIL_IGN 1 "FAIL" 0 "NORMAL" ;
VAL_ 827 ABG33B_3_1_PPS_STATUS_FAIL_DEV 1 "FAIL" 0 "NORMAL" ;
VAL_ 827 ABG33B_3_2_PPS_STATUS_FAIL_SSR 1 "FAIL" 0 "NORMAL" ;
VAL_ 827 ABG33B_3_3_PPS_STATUS_FAIL_ECU 1 "FAIL" 0 "NORMAL" ;
VAL_ 827 ABG33B_2_0_IND_WARN_PPA 3 "OTHER_FAIL" 2 "RESERVE" 1 "FAIL_Turn_ON" 0 "Turn_OFF" ;
VAL_ 827 ABG33B_2_2_DETECT_CRUSH 7 "RESERVE" 6 "RESERVE" 5 "CRASH DETECTION" 4 "RESERVE" 3 "RESERVE" 2 "RESERVE" 1 "RESERVE" 0 "NORMAL" ;
VAL_ 827 ABG33B_1_4_FLG_PEDESTRIAN_AIRBAG 1 "w PPS" 0 "w/o PPS" ;
VAL_ 1621 BIU655_4_0_BUZZER_PATTERN 178 "BUZ_pattern2_by_autolock" 177 "BUZ_pattern1_by_autolock" 165 "BUZ_pattern5_by_answerback" 164 "BUZ_pattern4_by_answerback" 163 "BUZ_pattern3_by_answerback" 162 "BUZ_pattern2_by_answerback" 161 "BUZ_pattern1_by_answerback" 240 "BUZ_stop_by_keyless" 145 "BUZ_pattern4_by_keyless" 129 "BUZ_pattern3_by_keyless" 225 "BUZ_pattern2_by_keyless" 97 "BUZ_pattern1_by_keyless" 0 "BUZ_hold" ;
VAL_ 1621 BIU655_3_0_BUZZER_VOL_REQ 7 "ON_duty_7" 6 "ON_duty_6" 5 "ON_duty_5" 4 "ON_duty_4" 3 "ON_duty_3" 2 "ON_duty_2" 1 "ON_duty_1" 0 "NONE" ;
VAL_ 1621 BIU655_3_3_RDEF_RELAY_REQ 1 "ON_REQ" 0 "OFF_REQ" ;
VAL_ 1621 BIU655_3_4_WIPER_DEICER_REQ 1 "ON_REQ" 0 "OFF_REQ" ;
VAL_ 1621 BIU655_3_5_FT_WIPER_REQ 3 "NON" 2 "Hi_REQ" 1 "Lo_REQ" 0 "OFF" ;
VAL_ 1621 BIU655_2_0_RR_WIPER_REQ 1 "ON_REQ" 0 "OFF_REQ" ;
VAL_ 1621 BIU655_2_1_WASHER_REQ 3 "NON" 2 "Rr_REQ" 1 "Fr_REQ" 0 "OFF" ;
VAL_ 1621 BIU655_2_3_HL_WASHER_REQ 1 "ON_REQ" 0 "OFF_REQ" ;
VAL_ 1621 BIU655_2_4_FT_FOG_RELAY_REQ 1 "ON_REQ" 0 "OFF_REQ" ;
VAL_ 1621 BIU655_2_5_HEADLAMP_HI_REQ 3 "NON" 2 "ON_REQ" 1 "Dimmer_REQ" 0 "OFF" ;
VAL_ 1621 BIU655_2_7_HEADLAMP_LO_REQ 1 "ON_REQ" 0 "OFF_REQ" ;
VAL_ 1618 BIU652_7_0_IND_SECURITY_IMB 6 "WARNING by the supersonic wave sensor" 5 "WARNING by the impact sensor" 4 "ALARM by the supersonic wave sensor" 3 "ALARM by the impact sensor" 7 "ALARM by open the hood" 2 "ALARM by open the trunk" 1 "ALARM by open the door" 240 "Four flashing with the immobilize" 224 "Three flashing by the immobilizer" 208 "Two flashing by the immobilizer" 192 "One flashing by the immobilizer" 144 "Flashing by the immobilizer" 128 "Lighting by the immobilizer" 112 "Lighting by the panic mode" 96 "Wait flashing by ALARM" 80 "Flashing by ALARM" 64 "Lighting by ALARM" 0 "OFF" ;
VAL_ 1618 BIU652_6_0_OCCUPATION_3RDRH 1 "ON" 0 "OFF" ;
VAL_ 1618 BIU652_6_1_OCCUPATION_3RDCTR 1 "ON" 0 "OFF" ;
VAL_ 1618 BIU652_6_2_OCCUPATION_3RDLH 1 "ON" 0 "OFF" ;
VAL_ 1618 BIU652_6_3_OCCUPATION_RRRH 1 "ON" 0 "OFF" ;
VAL_ 1618 BIU652_6_4_OCCUPATION_RRCTR 1 "ON" 0 "OFF" ;
VAL_ 1618 BIU652_6_5_OCCUPATION_RRLH 1 "ON" 0 "OFF" ;
VAL_ 1618 BIU652_6_6_HORNHAZARD_RES_SIG 1 "ON" 0 "OFF" ;
VAL_ 1618 BIU652_6_7_OCCUPATION_DRVR 1 "ON" 0 "OFF" ;
VAL_ 1618 BIU652_5_0_STATUS_ROOMLAMP 7 "TURN_ON_α_S4" 6 "TURN_ON_α_S3A" 5 "TURN_ON_α_S3" 4 "TURN_ON_Pattern2_S2A" 3 "TURN_ON_Pattern1_S2" 2 "TURN_OFF_Pattern2_S1A" 1 "TURN_OFF_Pattern1_S1" 0 "TURN_OFF_S0" ;
VAL_ 1618 BIU652_5_3_HEADLAMP_SMALL 1 "Turn_ON" 0 "Turn_OFF" ;
VAL_ 1618 BIU652_5_4_ALL_UNLOCK_STATE 1 "ON" 0 "OFF" ;
VAL_ 1618 BIU652_5_5_DRVR_UNLOCK_STATE 1 "ON" 0 "OFF" ;
VAL_ 1618 BIU652_5_6_ALL_LOCK_STATE 1 "ON" 0 "OFF" ;
VAL_ 1618 BIU652_3_0_DOOR_DRVR 1 "OPEN" 0 "CLOSE" ;
VAL_ 1618 BIU652_3_1_DOOR_PASS 1 "OPEN" 0 "CLOSE" ;
VAL_ 1618 BIU652_3_2_DOOR_RRRH 1 "OPEN" 0 "CLOSE" ;
VAL_ 1618 BIU652_3_3_DOOR_RRLH 1 "OPEN" 0 "CLOSE" ;
VAL_ 1618 BIU652_3_4_DOOR_RG 1 "OPEN" 0 "CLOSE" ;
VAL_ 1618 BIU652_3_5_DOOR_TR 1 "OPEN" 0 "CLOSE" ;
VAL_ 1618 BIU652_3_7_OPENSW_RG 1 "ON" 0 "OFF" ;
VAL_ 1618 BIU652_2_0_LOCKSTATUS_DRVR 1 "UNLOCK" 0 "LOCK" ;
VAL_ 1618 BIU652_2_1_LOCKSTATUS_PASS 1 "UNLOCK" 0 "LOCK" ;
VAL_ 1618 BIU652_2_2_LOCKSTATUS_RRRH 1 "UNLOCK" 0 "LOCK" ;
VAL_ 1618 BIU652_2_3_LOCKSTATUS_RRLH 1 "UNLOCK" 0 "LOCK" ;
VAL_ 1618 BIU652_2_4_LOCKSTATUS_RG 1 "UNLOCK OR PERMIT_UNLOCK" 0 "LOCK OR PROHIBIT_UNLOOK" ;
VAL_ 1618 BIU652_2_6_UNLOCK_DOORKEYSW 1 "ON" 0 "OFF" ;
VAL_ 1618 BIU652_2_7_LOCK_DOORKEYSW 1 "ON" 0 "OFF" ;
VAL_ 942 BIU3AE_5_0_WIPER_FT_VOLUME 5 "NON" 4 "Vol.5" 3 "Vol.4" 2 "Vol.3" 1 "Vol.2" 0 "Vol.1" ;
VAL_ 942 BIU3AE_4_4_FT_WIPER_FAIL 1 "FAIL" 0 "NORMAL" ;
VAL_ 942 BIU3AE_4_5_WIPER_FT 3 "AUTO" 2 "HIGH" 1 "LOW(MIST)" 0 "OFF" ;
VAL_ 942 BIU3AE_3_0_WINKER_LEVER_STATUS 5 "NON" 4 "Left_ON_Hold" 3 "Right_ON_Hold" 2 "Left_ON" 1 "Right_ON" 0 "OFF" ;
VAL_ 942 BIU3AE_3_4_WINKER_FACTOR 15 "NON" 14 "NON" 13 "Turn_Right(ActiveLaneChange)" 12 "Turn_Left(ActiveLaneChange)" 11 "Turn_Right(MinimumRiskManeuver)" 10 "Turn_Left(MinimumRiskManeuver)" 9 "OFF(MinimumRiskManeuver)" 8 "Hazard(Other)" 7 "Hazard(MinimumRiskManeuver)" 6 "Hazard(Emergency Brake)" 5 "Hazard(Hazard SW)" 4 "Turn_Right(deep push)" 3 "Turn_Right(shallow push)" 2 "Turn_Left(deep push)" 1 "Turn_Left(shallow push)" 0 "OFF" ;
VAL_ 942 BIU3AE_2_0_TURN_LAMP_FAIL_LEFT 1 "FAIL" 0 "NORMAL" ;
VAL_ 942 BIU3AE_2_1_TURN_LAMP_FAIL_RIGHT 1 "FAIL" 0 "NORMAL" ;
VAL_ 942 BIU3AE_2_3_HAZARD_SW 1 "ON" 0 "OFF" ;
VAL_ 940 BIU3AC_7_0_HEADLAMP_SMALL 1 "Turn_ON" 0 "Turn_OFF" ;
VAL_ 940 BIU3AC_7_1_HEADLAMP_LO_REQ 1 "Turn_ON" 0 "Turn_OFF" ;
VAL_ 940 BIU3AC_7_2_HEADLAMP_HI_REQ 1 "Turn_ON" 0 "Turn_OFF" ;
VAL_ 940 BIU3AC_7_3_FT_FOG_RELAY_REQ 1 "Turn_ON" 0 "Turn_OFF" ;
VAL_ 940 BIU3AC_7_4_FOGLAMP_RR 1 "Turn_ON" 0 "Turn_OFF" ;
VAL_ 940 BIU3AC_7_5_DRL 1 "Turn_ON" 0 "Turn_OFF" ;
VAL_ 940 BIU3AC_7_6_WIPER_FRONT 1 "ON" 0 "OFF" ;
VAL_ 940 BIU3AC_7_7_RDEF_RELAY_REQ 1 "ON" 0 "OFF" ;
VAL_ 940 BIU3AC_6_0_RDEFOGSW 1 "ON" 0 "OFF" ;
VAL_ 940 BIU3AC_6_1_CSTM_PRG 1 "PRG" 0 "NOT_PRG" ;
VAL_ 940 BIU3AC_6_2_FAIL_SHIFTLOCKSOL 1 "FAIL" 0 "NORMAL" ;
VAL_ 940 BIU3AC_6_3_REQ_CANCEL_ISS 1 "CANCEL" 0 "NON_CANCEL" ;
VAL_ 940 BIU3AC_6_4_REVERSE_MT 1 "REVERSE_ON" 0 "OFF" ;
VAL_ 940 BIU3AC_6_5_HANDBRAKE 1 "ON" 0 "OFF" ;
VAL_ 940 BIU3AC_6_6_BRAKELAMPSW 1 "ON" 0 "OFF" ;
VAL_ 940 BIU3AC_6_7_TOWING_SW 1 "ON" 0 "OFF" ;
VAL_ 940 BIU3AC_5_0_LANE_OFF_SW 3 "NONE" 2 "BREAKING_OF_WIRE" 1 "P-CR-OFF-SW_ON" 0 "OFF" ;
VAL_ 940 BIU3AC_5_2_PCR_OFF_SW 3 "NONE" 2 "BREAKING_OF_WIRE" 1 "P-CR-OFF-SW_ON" 0 "OFF" ;
VAL_ 940 BIU3AC_5_4_DIMMER_CANCEL 1 "ACTIVE" 0 "NON_ACTIVE" ;
VAL_ 940 BIU3AC_5_5_KEYSW 1 "ON" 0 "OFF" ;
VAL_ 940 BIU3AC_5_6_IND_ND_SHIFTLOCK 1 "表示" 0 "非表示" ;
VAL_ 940 BIU3AC_4_0_DOOR_DRVR 1 "OPEN" 0 "CLOSE" ;
VAL_ 940 BIU3AC_4_1_DOOR_PASS 1 "OPEN" 0 "CLOSE" ;
VAL_ 940 BIU3AC_4_2_DOOR_RRRH 1 "OPEN" 0 "CLOSE" ;
VAL_ 940 BIU3AC_4_3_DOOR_RRLH 1 "OPEN" 0 "CLOSE" ;
VAL_ 940 BIU3AC_4_4_DOOR_RG 1 "OPEN" 0 "CLOSE" ;
VAL_ 940 BIU3AC_4_5_DOOR_TR 1 "OPEN" 0 "CLOSE" ;
VAL_ 940 BIU3AC_4_6_HOOD_CLOSE 1 "ON" 0 "OFF" ;
VAL_ 940 BIU3AC_4_7_HOOD_OPEN 1 "ON" 0 "OFF" ;
VAL_ 940 BIU3AC_3_0_GW_STSW_RES 1 "REQ_RES_EGStart" 0 "NON_REQ_RES_EGStart" ;
VAL_ 940 BIU3AC_3_1_GW_POWER_RES 2 "RES_Start_MODE" 1 "Pre_Air_Cond_MODE" 0 "Normal_MODE" ;
VAL_ 940 BIU3AC_3_3_ST1 1 "ST" 0 "NORMAL" ;
VAL_ 940 BIU3AC_3_4_ST2 1 "ST" 0 "NORMAL" ;
VAL_ 940 BIU3AC_3_5_ACC 1 "ON" 0 "OFF" ;
VAL_ 940 BIU3AC_3_6_IGA 1 "ON" 0 "OFF" ;
VAL_ 940 BIU3AC_3_7_BAT_BACKUP 1 "ON" 0 "OFF" ;
VAL_ 940 BIU3AC_2_0_CSTM_AC 1 "ACTIVE" 0 "NON_ACTIVE" ;
VAL_ 940 BIU3AC_2_1_IMB_SMT 3 "Push&SMT" 2 "IMB_NO" 1 "IMB_YES" 0 "NON" ;
VAL_ 940 BIU3AC_2_3_CSTM_WGN_SDN 1 "WGN" 0 "SDN" ;
VAL_ 940 BIU3AC_2_4_VAL_SEAT_BACK_CTSM 1 "SEAT_BACK_ON" 0 "SEAT_BACK_OFF" ;
VAL_ 940 BIU3AC_2_5_VAL_MIR_AFOLD_CTSM 1 "MIR_AFOLD_ON" 0 "MIR_AFOLD_OFF" ;
VAL_ 940 BIU3AC_2_6_VAL_MIR_RTILT_CTSM 1 "MIR_RTILT_ON" 0 "MIR_RTILT_OFF" ;
VAL_ 940 BIU3AC_2_7_WIPER_REAR 1 "ON" 0 "OFF" ;
VAL_ 940 BIU3AC_1_4_PADDLESHIFT_DOWN_SW 1 "ON" 0 "OFF" ;
VAL_ 940 BIU3AC_1_5_PADDLESHIFT_UP_SW 1 "ON" 0 "OFF" ;
VAL_ 940 BIU3AC_1_6_MANUALMODE_SW 1 "ON" 0 "OFF" ;
VAL_ 1616 BIU650_7_3_DOOR_LINK_SW_STS 1 "ON" 0 "OFF" ;
VAL_ 1616 BIU650_6_3_RR_WIPER_STATUS 3 "Undefined" 2 "Hi" 1 "Lo" 0 "OFF" ;
VAL_ 1616 BIU650_6_5_WIPER_SENSITIVITY_CTM 3 "4" 2 "3" 1 "2" 0 "1" ;
VAL_ 1616 BIU650_5_2_FMH_DOOR_LOCK 3 "Undefined" 2 "Unlock" 1 "Lock" 0 "No request" ;
VAL_ 1616 BIU650_5_4_LMH_DOOR_LOCK 3 "Undefined" 2 "Unlock" 1 "Lock" 0 "No request" ;
VAL_ 1616 BIU650_4_0_REQ_OPE_AUTOLIGHT 3 "Undefined" 2 "Lo" 1 "Small" 0 "OFF" ;
VAL_ 1616 BIU650_4_2_STATE_SHINSSR 3 "Normal Mode" 2 "Diagnostic Mode" 1 "Shipping Inspection Mode" 0 "Initialization Mode" ;
VAL_ 1616 BIU650_4_4_STATE_RLS_FAIL 3 "Undefined" 2 "Recovering" 1 "Abnormal" 0 "Normal" ;
VAL_ 1616 BIU650_3_0_REQ_FWASHER_ITLOCK 1 "ON" 0 "OFF" ;
VAL_ 1616 BIU650_3_1_FWIPER_RTN 1 "ON" 0 "OFF" ;
VAL_ 1616 BIU650_3_2_TURN_LAMP_STATE_LEFT 1 "Blink" 0 "OFF" ;
VAL_ 1616 BIU650_3_3_TURN_LAMP_STATE_RIGHT 1 "Blink" 0 "OFF" ;
VAL_ 1616 BIU650_2_0_HEADLAMP_SMALL_SW 1 "ON" 0 "OFF" ;
VAL_ 1616 BIU650_2_1_HEADLAMP_LO_SW 1 "ON" 0 "OFF" ;
VAL_ 1616 BIU650_2_2_HEADLAMP_OFF_SW 1 "ON" 0 "OFF" ;
VAL_ 1616 BIU650_2_3_HEADLAMP_Hi_SW 1 "ON" 0 "OFF" ;
VAL_ 1616 BIU650_2_4_HEAD_LAMP_PASS_SW 1 "ON" 0 "OFF" ;
VAL_ 1616 BIU650_2_5_FFOG_SW 1 "ON" 0 "OFF" ;
VAL_ 1616 BIU650_2_6_RFOG_SW 1 "ON" 0 "OFF" ;
VAL_ 809 BST329_1_4_EB_HMI_WARNINGON 1 "Turn_ON" 0 "Turn_OFF" ;
VAL_ 809 BST329_1_5_WARN_BST_MET_LCD 0 "NOT_IINDICATE" 1 "INDICATE" ;
VAL_ 809 BST329_1_6_WARN_BST_RED 1 "Turn_ON" 0 "Turn_OFF" ;
VAL_ 811 EPB32B_6_0_VEHICLE_RUN_STOP_FLG 3 "reserve" 2 "ERROR" 1 "DRIVING" 0 "STOPPING" ;
VAL_ 811 EPB32B_6_2_REQ_HILL_P_CAUTION 1 "Turn_ON" 0 "Turn_OFF" ;
VAL_ 811 EPB32B_5_0_FLG_AVH_OILPRES_EPB 0 "NOT_OPERATE" 1 "OPERATE" ;
VAL_ 811 EPB32B_5_1_FLG_AVH 1 "AVH_OPERATE" 0 "AVH_NOT_OPERATE" ;
VAL_ 811 EPB32B_5_2_AVH_INTENSIFY_PRES 0 "OTHER" 1 "AVH_INTENSIFY_PRESSURE_DURING_ISS" ;
VAL_ 811 EPB32B_5_3_BREAK_IND 3 "UNDEFINED(TURN_OFF/DISPLAY OFF)" 2 "BLINK(Segment LC) or DISPLAY ON(Color LC)" 1 "TURN_ON(Segment LC) or DISPLAY ON(Color LC)" 0 "TURN_OFF(Segment LC) or DISPLAY OFF(Color LC)" ;
VAL_ 811 EPB32B_5_5_AVH_ON_LAMP 1 "ON" 0 "OFF" ;
VAL_ 811 EPB32B_5_6_AVH_FUNC_ON_LUMP 1 "ON" 0 "OFF" ;
VAL_ 811 EPB32B_5_7_AVH_ACTIVE 1 "WITH_AVH" 0 "WIITHOUT_AVH" ;
VAL_ 811 EPB32B_4_0_BUZZER 3 "CANCEL_Pi-X1" 2 "SHIFT_DISABLE_PiX2" 1 "DRIVER_BRAKE_CUE_Pi-" 0 "NO_BUZZER" ;
VAL_ 811 EPB32B_4_2_HILL_HOLD_ON_LAMP 1 "ON" 0 "OFF" ;
VAL_ 811 EPB32B_4_3_CLAMP_LAMP 3 "No_difinition" 2 "LAMP_BLINK" 1 "LAMP_ON" 0 "LAMP_OFF" ;
VAL_ 811 EPB32B_4_5_WARN_LAMP 3 "No_difinition" 2 "LAMP_BLINK" 1 "LAMP_ON" 0 "LAMP_OFF" ;
VAL_ 811 EPB32B_4_7_WARN_EPB_MET_LCD 1 "INDICATE" 0 "NOT_IINDICATE" ;
VAL_ 811 EPB32B_3_0_STATUS_EPB 7 "No_difinition" 6 "No_difinition" 5 "DYNAMIC PARKING" 4 "RELEASING" 3 "OPERATING" 2 "OPERATE" 1 "RELEASE" 0 "ERROR" ;
VAL_ 811 EPB32B_3_3_DYNAMIC_PARKING 1 "ON" 0 "OFF" ;
VAL_ 811 EPB32B_3_4_HILL_HOLD_RUN_FLG 1 "OPERATE" 0 "NOT_OPERATE" ;
VAL_ 811 EPB32B_3_5_INHIBIT_ISS_DELAY 1 "INHIBIT" 0 "PERMIT" ;
VAL_ 811 EPB32B_3_6_INHIBIT_ISS 1 "INHIBIT" 0 "PERMIT" ;
VAL_ 811 EPB32B_3_7_AVH_PERMIT_CONT_ACC 1 "PERMISSION" 0 "PROHIBITION" ;
VAL_ 811 EPB32B_2_0_ERR_INFO 3 "PULL_FORCE_FAIL" 2 "EMERGENCY_RELEASE" 1 "STROKE_SHORT" 0 "NORMAL" ;
VAL_ 811 EPB32B_2_2_EPB_FAIL_FLG1 1 "PERMIT" 0 "INHIBIT" ;
VAL_ 811 EPB32B_2_3_EPB_FAIL_FLG2 1 "PERMIT" 0 "INHIBIT" ;
VAL_ 811 EPB32B_2_4_EPB_FAIL_FLG3 1 "PERMIT" 0 "INHIBIT" ;
VAL_ 811 EPB32B_1_4_WAKE_UP_FRAME 1 "WakeUP_FRAME" 0 "Normal_FRAME" ;
VAL_ 811 EPB32B_1_5_REQ_COMM_CONT 1 "REQUEST" 0 "NO_REQUEST" ;
VAL_ 362 VDC16A_3_7_JUDGE_EXTRUSION 1 "EXTRUSION" 0 "OTHER" ;
VAL_ 808 VDC328_7_1_IND_WARN_CBC 1 "Turn_ON" 0 "Turn_OFF" ;
VAL_ 808 VDC328_7_2_ACTIVATE_CBC 1 "Turn_ON" 0 "Turn_OFF" ;
VAL_ 808 VDC328_7_3_FLAG_ACT_CBC 1 "ACTIVE" 0 "NON_ACTIVE" ;
VAL_ 808 VDC328_6_0_PROHIBIT_VDC_OFF_CCU 1 "PROHIBIT" 0 "PERMIT" ;
VAL_ 808 VDC328_6_1_PROHIBIT_AVH_CCU 1 "PROHIBIT" 0 "PERMIT" ;
VAL_ 808 VDC328_5_0_VDC_BUZZER 3 "reserve" 2 "VDC_OFF_SHIFT" 1 "VDC_OFF_SHIFT_DISABLE" 0 "NO_BUZZER" ;
VAL_ 808 VDC328_5_2_WARN_BRAKE_BOOST 1 "TURN_ON" 0 "TURN_OFF" ;
VAL_ 808 VDC328_5_6_IND_HSA_ON 1 "HSA ON" 0 "HSA OFF" ;
VAL_ 808 VDC328_5_7_IND_TCS_OFF 1 "Turn_ON" 0 "Turn_OFF" ;
VAL_ 808 VDC328_4_0_IND_VDC_OFF 1 "Turn_ON" 0 "Turn_OFF" ;
VAL_ 808 VDC328_4_1_STATE_ACTIVATE_VDC 1 "ACTIVE" 0 "NON_ACTIVE" ;
VAL_ 808 VDC328_4_2_IND_HSA_OFF 1 "HSA OFF" 0 "HSA ON" ;
VAL_ 808 VDC328_4_3_IND_HDC 3 "Uncertain_TURN_OFF" 2 "BLINK" 1 "TURN_ON" 0 "TURN_OFF" ;
VAL_ 808 VDC328_4_5_WARNING_BRAKE_SYS 3 "reserve" 2 "reserve" 1 "TURN_ON" 0 "TURN_OFF" ;
VAL_ 808 VDC328_4_7_ACTIVE_OHB 1 "ACTIVE" 0 "DEACTIVE" ;
VAL_ 808 VDC328_3_0_IND_WARN_EBD 1 "Turn_ON" 0 "Turn_OFF" ;
VAL_ 808 VDC328_3_1_IND_WARN_ABS 1 "Turn_ON" 0 "Turn_OFF" ;
VAL_ 808 VDC328_3_2_IND_WARN_VDC 1 "Turn_ON" 0 "Turn_OFF" ;
VAL_ 808 VDC328_3_3_IND_WARN_HSA 1 "Turn_ON" 0 "Turn_OFF" ;
VAL_ 808 VDC328_3_4_WARN_BRAKEFLUID_LV 3 "OTHER_FAIL" 2 "RESERVE" 1 "FAIL_Turn_ON" 0 "Turn_OFF" ;
VAL_ 808 VDC328_3_6_IND_TCS_OFF 1 "ON" 0 "OFF" ;
VAL_ 808 VDC328_3_7_EXIST_EPB 1 "WITH_EPB" 0 "WIITHOUT_EPB" ;
VAL_ 808 VDC328_2_0_WARN_EBD_MET_LCD 1 "INDICATE" 0 "NOT_IINDICATE" ;
VAL_ 808 VDC328_2_1_WARN_ABS_MET_LCD 1 "INDICATE" 0 "NOT_IINDICATE" ;
VAL_ 808 VDC328_2_2_WARN_VDC_MET_LCD 1 "INDICATE" 0 "NOT_IINDICATE" ;
VAL_ 808 VDC328_2_3_WARN_HSA_MET_LCD 1 "INDICATE" 0 "NOT_IINDICATE" ;
VAL_ 808 VDC328_2_4_EXIST_VECTARING 1 "WITH VECTORING(16inch_BRAKE)" 0 "WITHOUT VECTORING(15inch_BRAKE)" ;
VAL_ 315 VDC13B_1_4_BRAKE_TYPE 1 "ACTIVE_BOOSTER" 0 "VDC" ;
VAL_ 315 VDC13B_1_5_REQ_ENG_TRQ_DOWN 1 "REQ" 0 "NON_REQ" ;
VAL_ 315 VDC13B_1_6_REQ_ENG_TRQ_UP 1 "REQ" 0 "NON_REQ" ;
VAL_ 315 VDC13B_1_7_PROHIBIT_FUEL_CUT 1 "PROHIBIT" 0 "PERMIT" ;
VAL_ 313 VDC139_7_4_FAIL_PRESSURE_SSR 1 "NORMAL" 0 "FAIL" ;
VAL_ 313 VDC139_7_5_STATUS_EPB 7 "No_difinition" 6 "AVH_OPERATE" 5 "DYNAMIC PARKING" 4 "RELEASING" 3 "OPERATING" 2 "OPERATE" 1 "RELEASE" 0 "ERROR" ;
VAL_ 313 VDC139_4_0_HDC_STATUS 3 "Uncertain(SYS_OFF)" 2 "SYS_ACTIVE" 1 "SYS_WAIT" 0 "SYS_OFF" ;
VAL_ 313 VDC139_4_2_BRAKELAMPSW 1 "ON" 0 "OFF" ;
VAL_ 313 VDC139_4_3_FAIL_BRAKELAMPSW 1 "NORMAL" 0 "FAIL" ;
VAL_ 313 VDC139_4_4_ACTIVATE_ABS 1 "ACTIVE" 0 "NON_ACTIVE" ;
VAL_ 313 VDC139_4_5_ACTIVATE_TCS 1 "ACTIVE" 0 "NON_ACTIVE" ;
VAL_ 313 VDC139_4_6_CONT_OVER_STR 1 "control" 0 "NON_Control" ;
VAL_ 313 VDC139_4_7_CONT_UNDER_STR 1 "control" 0 "NON_Control" ;
VAL_ 313 VDC139_3_5_FAIL_VDC_SSR 1 "NORMAL" 0 "FAIL" ;
VAL_ 313 VDC139_3_6_FAIL_SPD_SSR_FHI 1 "NORMAL" 0 "FAIL" ;
VAL_ 313 VDC139_3_7_FAIL_ABS_SYS 1 "NORMAL" 0 "FAIL" ;
VAL_ 313 VDC139_1_4_FAIL_HDC_SYS 1 "NORMAL" 0 "FAIL" ;
VAL_ 313 VDC139_1_5_VEHICLE_HIGHT 2 "STANDARD" 1 "OBK" 0 "NON" ;
VAL_ 313 VDC139_1_7_REPROGRAMING 1 "STOP_Diag&COMM" 0 "NORMAL" ;
VAL_ 312 VDC138_1_4_ACTIVE_LDP 1 "ACTIVE" 0 "NON_ACTIVE" ;
VAL_ 312 VDC138_1_5_PROHIBIT_LDP 1 "PROHIBIT" 0 "PERMIT" ;
VAL_ 312 VDC138_1_6_VDC_SMALL_MARGIN 1 "SMALL MARGIN" 0 "NOMAL" ;
VAL_ 312 VDC138_1_7_DETECT_REAR_SLIP 1 "CONTROL" 0 "NOT_CONTROL" ;
VAL_ 1143 CCU477_28_2_TIM_CHG_CHG_FLG 3 "Fail _Value" 2 "Timer_Charging_Setting_UnChanged" 1 "Timer_Charging_Setting_Changed" 0 "Initial_Value" ;
VAL_ 1143 CCU477_28_0_TIM_CHG_ICON_DISP 3 "Fail_Value" 2 "OFF" 1 "ON" 0 "Initial_Value" ;
VAL_ 1143 CCU477_27_4_TIM_CHG_STATUS 15 "Fail_Value" 8 "Charging_Now(Reserved)" 7 "Time_Range_Type_Charging_End(Reserved)" 6 "Time_Range_Type_Charging_Start(Reserved)" 5 "Start_Time_Type_Charging_Start(Reserved)" 4 "Charging_End" 3 "Charging_Start" 2 "Timer_Charging_Standby" 1 "Non_Timer_Charging" 0 "Initial _Value" ;
VAL_ 1143 CCU477_27_1_DEP_TIM_PRE_CON_FLAG 7 "Fail_Value" 6 "Reserved" 5 "Reserved" 4 "Departure_Time" 3 "Start_AC" 2 "Start_Temp_Ctrl_Performance" 1 "Start_Temp_Ctrl_Normal" 0 "Initial_Value(OFF)" ;
VAL_ 1143 CCU477_27_0_TIM_CHG_PERM_FLAG 1 "Timer_Charging_Abled" 0 "Initial_Value (timer charging disabled)" ;
VAL_ 1143 CCU477_22_0_TIM4_CHG_SET_TYPE 3 "Fail_Value" 2 "Time_Range_Type" 1 "Start_Time_Type" 0 "Initial_Value" ;
VAL_ 1143 CCU477_21_5_TIM4_CHG_SW_STS 3 "Fail_Value" 2 "ON" 1 "OFF" 0 "Initial_Value(Non-timer)	" ;
VAL_ 1143 CCU477_21_0_TIM4_DISP_ID 31 "Fail_Value" 4 "Disp_Seq_No_ID4" 3 "Disp_Seq_No_ID3" 2 "Disp_Seq_No_ID2" 1 "Disp_Seq_No_ID1" 0 "Initial_Value(Non-display)	" ;
VAL_ 1143 CCU477_16_0_TIM3_CHG_SET_TYPE 3 "Fail_Value" 2 "Time_Range_Type" 1 "Start_Time_Type" 0 "Initial_Value" ;
VAL_ 1143 CCU477_15_5_TIM3_CHG_SW_STS 3 "Fail_Value" 2 "ON" 1 "OFF" 0 "Initial_Value(Non-timer)	" ;
VAL_ 1143 CCU477_15_0_TIM3_DISP_ID 31 "Fail_Value" 4 "Disp_Seq_No_ID4" 3 "Disp_Seq_No_ID3" 2 "Disp_Seq_No_ID2" 1 "Disp_Seq_No_ID1" 0 "Initial_Value(Non-display)	" ;
VAL_ 1143 CCU477_10_0_TIM2_CHG_SET_TYPE 3 "Fail_value" 2 "TimeRange_Type" 1 "StartTime_Type" 0 "Initial_value" ;
VAL_ 1143 CCU477_9_5_TIM2_CHG_SW_STS 3 "Fail_Value" 2 "ON" 1 "OFF" 0 "Initial_Value(Non-timer)	" ;
VAL_ 1143 CCU477_9_0_TIM2_DISP_ID 31 "Fail_Value" 4 "Disp_Seq_No_ID4" 3 "Disp_Seq_No_ID3" 2 "Disp_Seq_No_ID2" 1 "Disp_Seq_No_ID1" 0 "Initial_Value(Non-display)	" ;
VAL_ 1143 CCU477_4_0_TIM1_CHG_SET_TYPE 3 "Fail_Value" 2 "Time_Range_Type" 1 "Start_Time_Type" 0 "Initial_Value" ;
VAL_ 1143 CCU477_3_5_TIM1_CHG_SW_STS 3 "Fail_Value" 2 "ON" 1 "OFF" 0 "Initial_Value(Non-timer)	" ;
VAL_ 1143 CCU477_3_0_TIM1_DISP_ID 31 "Fail_Value" 4 "Disp_Seq_No_ID4" 3 "Disp_Seq_No_ID3" 2 "Disp_Seq_No_ID2" 1 "Disp_Seq_No_ID1" 0 "Initial_Value(Non-display)	" ;
VAL_ 1142 CCU476_17_2_SW_STOP_CHG 1 "ON" 0 "OFF" ;
VAL_ 1142 CCU476_17_1_SW_NORMAL_MOD_CHG 1 "押す" 0 "No signal" ;
VAL_ 1142 CCU476_17_0_SW_PWR_MOD_CHG 1 "押す" 0 "No signal" ;
VAL_ 1142 CCU476_16_4_AC_CUR_MAX_LIM_CHG 6 "8A" 5 "12A" 4 "16A" 3 "24A" 2 "32A" 1 "40A" 0 "要求なし" ;
VAL_ 1142 CCU476_16_0_DC_PWR_MAX_LIM_CHG 8 "50kW" 7 "75kW" 6 "100kW" 5 "125kW" 4 "150kW" 3 "175kW" 2 "200kW" 1 "225kW" 0 "要求なし" ;
VAL_ 1142 CCU476_13_5_SW_CAUTION_PNC 1 "押す" 0 "No signal" ;
VAL_ 1142 CCU476_13_4_SW_NEW_PNC 1 "押す" 0 "No signal" ;
VAL_ 1142 CCU476_13_3_START_CTR_PNC 1 "契約案内出力" 0 "非表示" ;
VAL_ 1142 CCU476_13_1_STS_PNC 3 "オン状態（ON）" 2 "オフ状態（OFF）" 1 "新規契約 (New)" 0 "新規契約 (New)" ;
VAL_ 1142 CCU476_13_0_DESC_PNC 1 "文言A表示" 0 "非表示" ;
VAL_ 1142 CCU476_9_0_WKD_SET_TIM_CHG 7 "日曜日" 6 "土曜日 " 5 "金曜日 " 4 "木曜日 " 3 "水曜日 " 2 "火曜日 " 1 "月曜日" 0 "不定" ;
VAL_ 1142 CCU476_8_0_LOGIN_REQ_TIM_CHG 3 "削除" 2 "変更" 1 "追加 " 0 "不定(設定要求なし)" ;
VAL_ 1142 CCU476_3_0_PNC_SW_REQ_CCU 5 "PnC_Function_Terminated(Certificate_Deleted)" 4 "Key_Unlocked" 3 "Key_Locked" 2 "ON" 1 "OFF" 0 "No_Request" ;
VAL_ 1142 CCU476_2_7_SW_TIM_CHG 1 "オン状態" 0 "オフ状態" ;
